[part 3 of 3: package /ComponentTypes]
AUTOSAR XML (schema 00050)
package /ComponentTypes  (continued)
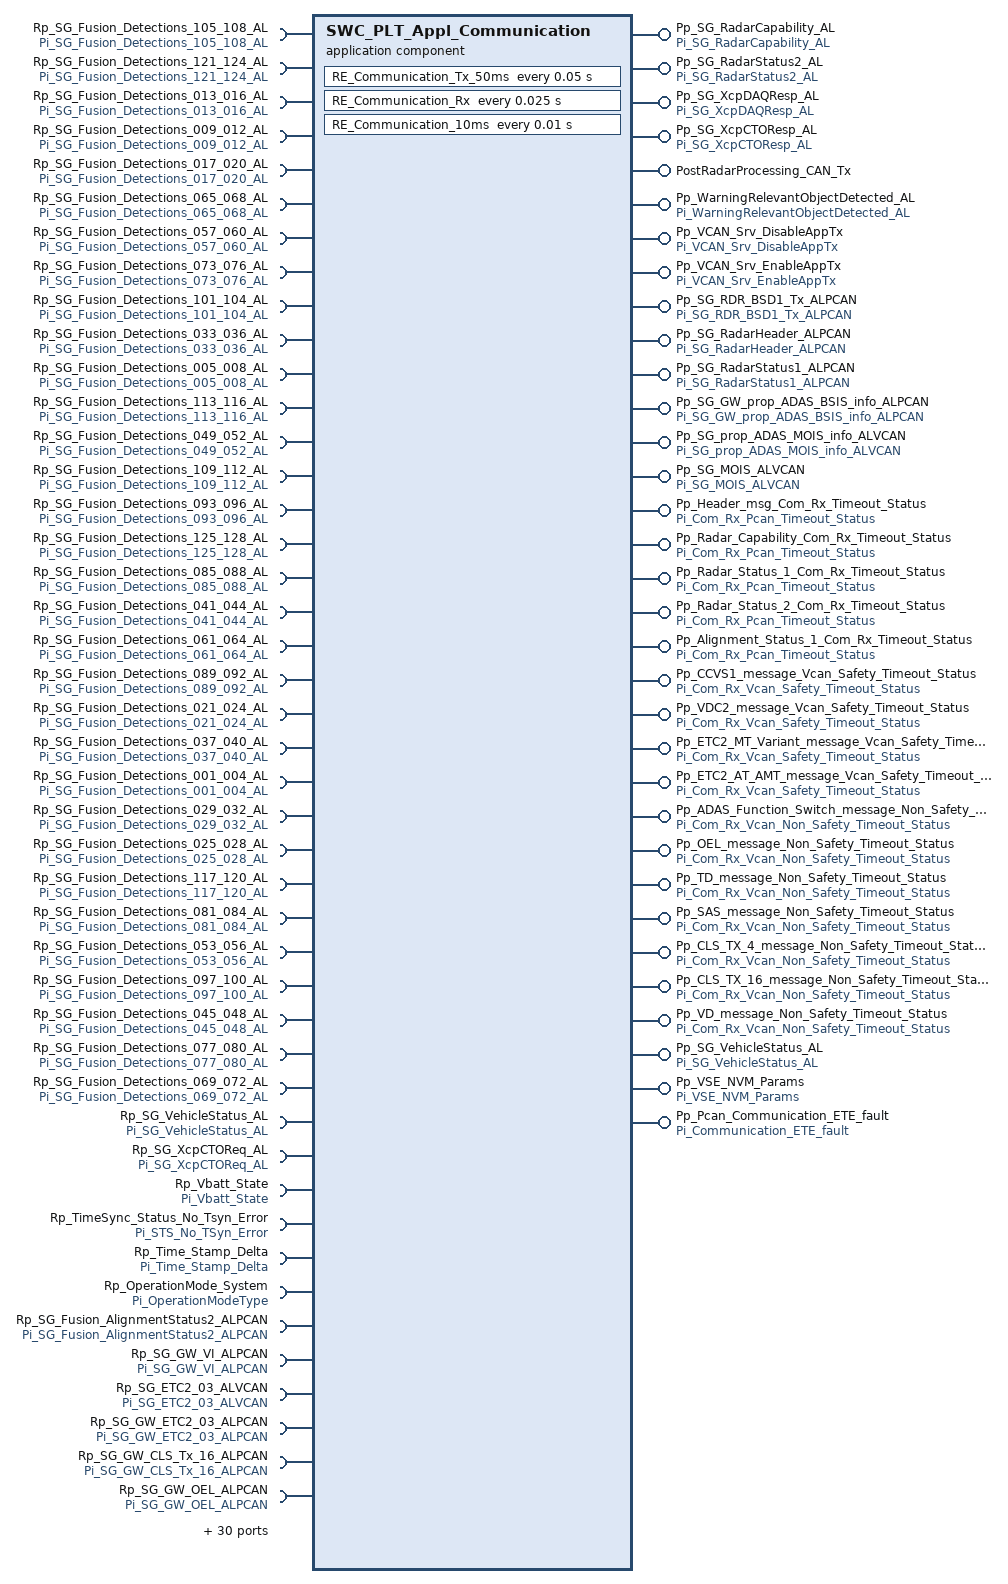
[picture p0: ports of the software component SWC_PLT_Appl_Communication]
  application sw component type SWC_PLT_Appl_Communication  (continued)
    182 x provide port:  (continued)
      Pp_SG_Detections_157_160_AL: nonqueued-sender-com-spec{data-element=Vdp_SG_Detections_157_160_AL, init-value=fields=[DET_AZIMUTH_157:0, DET_AZIMUTH_158:0, DET_AZIMUTH_159:0, DET_AZIMUTH_160:0, DET_AZIMUTH_ERR_157:0, DET_AZIMUTH_ERR_158:0, DET_AZIMUTH_ERR_159:0, DET_AZIMUTH_ERR_160:0, DET_BELOW_RAIN_THOLD_157:0, DET_BELOW_RAIN_THOLD_158:0, DET_BELOW_RAIN_THOLD_159:0, DET_BELOW_RAIN_THOLD_160:0, DET_BI_STATIC_FLAG_157:0, DET_BI_STATIC_FLAG_158:0, DET_BI_STATIC_FLAG_159:0, DET_BI_STATIC_FLAG_160:0, DET_CONFD_AZIMUTH_157:0, DET_CONFD_AZIMUTH_158:0, DET_CONFD_AZIMUTH_159:0, DET_CONFD_AZIMUTH_160:0, DET_CONFD_ELEVATION_157:0, DET_CONFD_ELEVATION_158:0, DET_CONFD_ELEVATION_159:0, DET_CONFD_ELEVATION_160:0, DET_ELEVATION_157:0, DET_ELEVATION_158:0, DET_ELEVATION_159:0, DET_ELEVATION_160:0, DET_ELEVATION_ERR_157:0, DET_ELEVATION_ERR_158:0, DET_ELEVATION_ERR_159:0, DET_ELEVATION_ERR_160:0, DET_EXISTENCE_PROB_157:0, DET_EXISTENCE_PROB_158:0, DET_EXISTENCE_PROB_159:0, DET_EXISTENCE_PROB_160:0, DET_HVC_FLAG_157:0, DET_HVC_FLAG_158:0, DET_HVC_FLAG_159:0, DET_HVC_FLAG_160:0, DET_IDM_157:0, DET_IDM_158:0, DET_IDM_159:0, DET_IDM_160:0, DET_MH_CRC16_157_160:0, DET_MH_CYCLE_COUNTER_157_160:0, DET_MH_SCAN_INDEX_4LSB_157_160:0, DET_MTD_157:0, DET_MTD_158:0, DET_MTD_159:0, DET_MTD_160:0, DET_PROB_1STAZHYPO_157:0, DET_PROB_1STAZHYPO_158:0, DET_PROB_1STAZHYPO_159:0, DET_PROB_1STAZHYPO_160:0, DET_RANGE_157:0, DET_RANGE_158:0, DET_RANGE_159:0, DET_RANGE_160:0, DET_RANGE_ERR_157:0, DET_RANGE_ERR_158:0, DET_RANGE_ERR_159:0, DET_RANGE_ERR_160:0, DET_RANGE_VELOCITY_157:16384, DET_RANGE_VELOCITY_158:16384, DET_RANGE_VELOCITY_159:16384, DET_RANGE_VELOCITY_160:16384, DET_RANGE_VELOCITY_ERR_157:0, DET_RANGE_VELOCITY_ERR_158:0, DET_RANGE_VELOCITY_ERR_159:0, DET_RANGE_VELOCITY_ERR_160:0, DET_RCS_157:128, DET_RCS_158:128, DET_RCS_159:128, DET_RCS_160:128, DET_SNR_157:0, DET_SNR_158:0, DET_SNR_159:0, DET_SNR_160:0, DET_SUPER_RES_TARGET_157:0, DET_SUPER_RES_TARGET_158:0, DET_SUPER_RES_TARGET_159:0, DET_SUPER_RES_TARGET_160:0]}, provided-interface=Pi_SG_Detections_157_160_AL
      Pp_SG_Detections_013_016_AL: nonqueued-sender-com-spec{data-element=Vdp_SG_Detections_013_016_AL, init-value=fields=[DET_AZIMUTH_013:0, DET_AZIMUTH_014:0, DET_AZIMUTH_015:0, DET_AZIMUTH_016:0, DET_AZIMUTH_ERR_013:0, DET_AZIMUTH_ERR_014:0, DET_AZIMUTH_ERR_015:0, DET_AZIMUTH_ERR_016:0, DET_BELOW_RAIN_THOLD_013:0, DET_BELOW_RAIN_THOLD_014:0, DET_BELOW_RAIN_THOLD_015:0, DET_BELOW_RAIN_THOLD_016:0, DET_BI_STATIC_FLAG_013:0, DET_BI_STATIC_FLAG_014:0, DET_BI_STATIC_FLAG_015:0, DET_BI_STATIC_FLAG_016:0, DET_CONFD_AZIMUTH_013:0, DET_CONFD_AZIMUTH_014:0, DET_CONFD_AZIMUTH_015:0, DET_CONFD_AZIMUTH_016:0, DET_CONFD_ELEVATION_013:0, DET_CONFD_ELEVATION_014:0, DET_CONFD_ELEVATION_015:0, DET_CONFD_ELEVATION_016:0, DET_ELEVATION_013:0, DET_ELEVATION_014:0, DET_ELEVATION_015:0, DET_ELEVATION_016:0, DET_ELEVATION_ERR_013:0, DET_ELEVATION_ERR_014:0, DET_ELEVATION_ERR_015:0, DET_ELEVATION_ERR_016:0, DET_EXISTENCE_PROB_013:0, DET_EXISTENCE_PROB_014:0, DET_EXISTENCE_PROB_015:0, DET_EXISTENCE_PROB_016:0, DET_HVC_FLAG_013:0, DET_HVC_FLAG_014:0, DET_HVC_FLAG_015:0, DET_HVC_FLAG_016:0, DET_IDM_013:0, DET_IDM_014:0, DET_IDM_015:0, DET_IDM_016:0, DET_MH_CRC16_013_016:0, DET_MH_CYCLE_COUNTER_013_016:0, DET_MH_SCAN_INDEX_4LSB_013_016:0, DET_MTD_013:0, DET_MTD_014:0, DET_MTD_015:0, DET_MTD_016:0, DET_PROB_1STAZHYPO_013:0, DET_PROB_1STAZHYPO_014:0, DET_PROB_1STAZHYPO_015:0, DET_PROB_1STAZHYPO_016:0, DET_RANGE_013:0, DET_RANGE_014:0, DET_RANGE_015:0, DET_RANGE_016:0, DET_RANGE_ERR_013:0, DET_RANGE_ERR_014:0, DET_RANGE_ERR_015:0, DET_RANGE_ERR_016:0, DET_RANGE_VELOCITY_013:16384, DET_RANGE_VELOCITY_014:16384, DET_RANGE_VELOCITY_015:16384, DET_RANGE_VELOCITY_016:16384, DET_RANGE_VELOCITY_ERR_013:0, DET_RANGE_VELOCITY_ERR_014:0, DET_RANGE_VELOCITY_ERR_015:0, DET_RANGE_VELOCITY_ERR_016:0, DET_RCS_013:128, DET_RCS_014:128, DET_RCS_015:128, DET_RCS_016:128, DET_SNR_013:0, DET_SNR_014:0, DET_SNR_015:0, DET_SNR_016:0, DET_SUPER_RES_TARGET_013:0, DET_SUPER_RES_TARGET_014:0, DET_SUPER_RES_TARGET_015:0, DET_SUPER_RES_TARGET_016:0]}, provided-interface=Pi_SG_Detections_013_016_AL
    32 x require port:
      Rp_SG_Fusion_Detections_105_108_AL: nonqueued-receiver-com-spec{data-element=Vdp_SG_Fusion_Detections_105_108_AL, init-value=fields=[DET_AZIMUTH_105_Rx:0, DET_AZIMUTH_106_Rx:0, DET_AZIMUTH_107_Rx:0, DET_AZIMUTH_108_Rx:0, DET_AZIMUTH_ERR_105_Rx:0, DET_AZIMUTH_ERR_106_Rx:0, DET_AZIMUTH_ERR_107_Rx:0, DET_AZIMUTH_ERR_108_Rx:0, DET_BELOW_RAIN_THOLD_105_Rx:0, DET_BELOW_RAIN_THOLD_106_Rx:0, DET_BELOW_RAIN_THOLD_107_Rx:0, DET_BELOW_RAIN_THOLD_108_Rx:0, DET_BI_STATIC_FLAG_105_Rx:0, DET_BI_STATIC_FLAG_106_Rx:0, DET_BI_STATIC_FLAG_107_Rx:0, DET_BI_STATIC_FLAG_108_Rx:0, DET_CONFD_AZIMUTH_105_Rx:0, DET_CONFD_AZIMUTH_106_Rx:0, DET_CONFD_AZIMUTH_107_Rx:0, DET_CONFD_AZIMUTH_108_Rx:0, DET_CONFD_ELEVATION_105_Rx:0, DET_CONFD_ELEVATION_106_Rx:0, DET_CONFD_ELEVATION_107_Rx:0, DET_CONFD_ELEVATION_108_Rx:0, DET_ELEVATION_105_Rx:0, DET_ELEVATION_106_Rx:0, DET_ELEVATION_107_Rx:0, DET_ELEVATION_108_Rx:0, DET_ELEVATION_ERR_105_Rx:0, DET_ELEVATION_ERR_106_Rx:0, DET_ELEVATION_ERR_107_Rx:0, DET_ELEVATION_ERR_108_Rx:0, DET_EXISTENCE_PROB_105_Rx:0, DET_EXISTENCE_PROB_106_Rx:0, DET_EXISTENCE_PROB_107_Rx:0, DET_EXISTENCE_PROB_108_Rx:0, DET_HVC_FLAG_105_Rx:0, DET_HVC_FLAG_106_Rx:0, DET_HVC_FLAG_107_Rx:0, DET_HVC_FLAG_108_Rx:0, DET_IDM_105_Rx:0, DET_IDM_106_Rx:0, DET_IDM_107_Rx:0, DET_IDM_108_Rx:0, DET_MH_CRC16_105_108_Rx:0, DET_MH_CYCLE_COUNTER_105_108_Rx:0, DET_MH_SCAN_INDEX_4LSB_105_108_Rx:0, DET_MTD_105_Rx:0, DET_MTD_106_Rx:0, DET_MTD_107_Rx:0, DET_MTD_108_Rx:0, DET_PROB_1STAZHYPO_105_Rx:0, DET_PROB_1STAZHYPO_106_Rx:0, DET_PROB_1STAZHYPO_107_Rx:0, DET_PROB_1STAZHYPO_108_Rx:0, DET_RANGE_105_Rx:0, DET_RANGE_106_Rx:0, DET_RANGE_107_Rx:0, DET_RANGE_108_Rx:0, DET_RANGE_ERR_105_Rx:0, DET_RANGE_ERR_106_Rx:0, DET_RANGE_ERR_107_Rx:0, DET_RANGE_ERR_108_Rx:0, DET_RANGE_VELOCITY_105_Rx:0, DET_RANGE_VELOCITY_106_Rx:0, DET_RANGE_VELOCITY_107_Rx:0, DET_RANGE_VELOCITY_108_Rx:0, DET_RANGE_VELOCITY_ERR_105_Rx:0, DET_RANGE_VELOCITY_ERR_106_Rx:0, DET_RANGE_VELOCITY_ERR_107_Rx:0, DET_RANGE_VELOCITY_ERR_108_Rx:0, DET_RCS_105_Rx:0, DET_RCS_106_Rx:0, DET_RCS_107_Rx:0, DET_RCS_108_Rx:0, DET_SNR_105_Rx:0, DET_SNR_106_Rx:0, DET_SNR_107_Rx:0, DET_SNR_108_Rx:0, DET_SUPER_RES_TARGET_105_Rx:0, DET_SUPER_RES_TARGET_106_Rx:0, DET_SUPER_RES_TARGET_107_Rx:0, DET_SUPER_RES_TARGET_108_Rx:0]}, required-interface=Pi_SG_Fusion_Detections_105_108_AL
      Rp_SG_Fusion_Detections_121_124_AL: nonqueued-receiver-com-spec{data-element=Vdp_SG_Fusion_Detections_121_124_AL, init-value=fields=[DET_AZIMUTH_121_Rx:0, DET_AZIMUTH_122_Rx:0, DET_AZIMUTH_123_Rx:0, DET_AZIMUTH_124_Rx:0, DET_AZIMUTH_ERR_121_Rx:0, DET_AZIMUTH_ERR_122_Rx:0, DET_AZIMUTH_ERR_123_Rx:0, DET_AZIMUTH_ERR_124_Rx:0, DET_BELOW_RAIN_THOLD_121_Rx:0, DET_BELOW_RAIN_THOLD_122_Rx:0, DET_BELOW_RAIN_THOLD_123_Rx:0, DET_BELOW_RAIN_THOLD_124_Rx:0, DET_BI_STATIC_FLAG_121_Rx:0, DET_BI_STATIC_FLAG_122_Rx:0, DET_BI_STATIC_FLAG_123_Rx:0, DET_BI_STATIC_FLAG_124_Rx:0, DET_CONFD_AZIMUTH_121_Rx:0, DET_CONFD_AZIMUTH_122_Rx:0, DET_CONFD_AZIMUTH_123_Rx:0, DET_CONFD_AZIMUTH_124_Rx:0, DET_CONFD_ELEVATION_121_Rx:0, DET_CONFD_ELEVATION_122_Rx:0, DET_CONFD_ELEVATION_123_Rx:0, DET_CONFD_ELEVATION_124_Rx:0, DET_ELEVATION_121_Rx:0, DET_ELEVATION_122_Rx:0, DET_ELEVATION_123_Rx:0, DET_ELEVATION_124_Rx:0, DET_ELEVATION_ERR_121_Rx:0, DET_ELEVATION_ERR_122_Rx:0, DET_ELEVATION_ERR_123_Rx:0, DET_ELEVATION_ERR_124_Rx:0, DET_EXISTENCE_PROB_121_Rx:0, DET_EXISTENCE_PROB_122_Rx:0, DET_EXISTENCE_PROB_123_Rx:0, DET_EXISTENCE_PROB_124_Rx:0, DET_HVC_FLAG_121_Rx:0, DET_HVC_FLAG_122_Rx:0, DET_HVC_FLAG_123_Rx:0, DET_HVC_FLAG_124_Rx:0, DET_IDM_121_Rx:0, DET_IDM_122_Rx:0, DET_IDM_123_Rx:0, DET_IDM_124_Rx:0, DET_MH_CRC16_121_124_Rx:0, DET_MH_CYCLE_COUNTER_121_124_Rx:0, DET_MH_SCAN_INDEX_4LSB_121_124_Rx:0, DET_MTD_121_Rx:0, DET_MTD_122_Rx:0, DET_MTD_123_Rx:0, DET_MTD_124_Rx:0, DET_PROB_1STAZHYPO_121_Rx:0, DET_PROB_1STAZHYPO_122_Rx:0, DET_PROB_1STAZHYPO_123_Rx:0, DET_PROB_1STAZHYPO_124_Rx:0, DET_RANGE_121_Rx:0, DET_RANGE_122_Rx:0, DET_RANGE_123_Rx:0, DET_RANGE_124_Rx:0, DET_RANGE_ERR_121_Rx:0, DET_RANGE_ERR_122_Rx:0, DET_RANGE_ERR_123_Rx:0, DET_RANGE_ERR_124_Rx:0, DET_RANGE_VELOCITY_121_Rx:0, DET_RANGE_VELOCITY_122_Rx:0, DET_RANGE_VELOCITY_123_Rx:0, DET_RANGE_VELOCITY_124_Rx:0, DET_RANGE_VELOCITY_ERR_121_Rx:0, DET_RANGE_VELOCITY_ERR_122_Rx:0, DET_RANGE_VELOCITY_ERR_123_Rx:0, DET_RANGE_VELOCITY_ERR_124_Rx:0, DET_RCS_121_Rx:0, DET_RCS_122_Rx:0, DET_RCS_123_Rx:0, DET_RCS_124_Rx:0, DET_SNR_121_Rx:0, DET_SNR_122_Rx:0, DET_SNR_123_Rx:0, DET_SNR_124_Rx:0, DET_SUPER_RES_TARGET_121_Rx:0, DET_SUPER_RES_TARGET_122_Rx:0, DET_SUPER_RES_TARGET_123_Rx:0, DET_SUPER_RES_TARGET_124_Rx:0]}, required-interface=Pi_SG_Fusion_Detections_121_124_AL
      Rp_SG_Fusion_Detections_013_016_AL: nonqueued-receiver-com-spec{data-element=Vdp_SG_Fusion_Detections_013_016_AL, init-value=fields=[DET_AZIMUTH_013_Rx:0, DET_AZIMUTH_014_Rx:0, DET_AZIMUTH_015_Rx:0, DET_AZIMUTH_016_Rx:0, DET_AZIMUTH_ERR_013_Rx:0, DET_AZIMUTH_ERR_014_Rx:0, DET_AZIMUTH_ERR_015_Rx:0, DET_AZIMUTH_ERR_016_Rx:0, DET_BELOW_RAIN_THOLD_013_Rx:0, DET_BELOW_RAIN_THOLD_014_Rx:0, DET_BELOW_RAIN_THOLD_015_Rx:0, DET_BELOW_RAIN_THOLD_016_Rx:0, DET_BI_STATIC_FLAG_013_Rx:0, DET_BI_STATIC_FLAG_014_Rx:0, DET_BI_STATIC_FLAG_015_Rx:0, DET_BI_STATIC_FLAG_016_Rx:0, DET_CONFD_AZIMUTH_013_Rx:0, DET_CONFD_AZIMUTH_014_Rx:0, DET_CONFD_AZIMUTH_015_Rx:0, DET_CONFD_AZIMUTH_016_Rx:0, DET_CONFD_ELEVATION_013_Rx:0, DET_CONFD_ELEVATION_014_Rx:0, DET_CONFD_ELEVATION_015_Rx:0, DET_CONFD_ELEVATION_016_Rx:0, DET_ELEVATION_013_Rx:0, DET_ELEVATION_014_Rx:0, DET_ELEVATION_015_Rx:0, DET_ELEVATION_016_Rx:0, DET_ELEVATION_ERR_013_Rx:0, DET_ELEVATION_ERR_014_Rx:0, DET_ELEVATION_ERR_015_Rx:0, DET_ELEVATION_ERR_016_Rx:0, DET_EXISTENCE_PROB_013_Rx:0, DET_EXISTENCE_PROB_014_Rx:0, DET_EXISTENCE_PROB_015_Rx:0, DET_EXISTENCE_PROB_016_Rx:0, DET_HVC_FLAG_013_Rx:0, DET_HVC_FLAG_014_Rx:0, DET_HVC_FLAG_015_Rx:0, DET_HVC_FLAG_016_Rx:0, DET_IDM_013_Rx:0, DET_IDM_014_Rx:0, DET_IDM_015_Rx:0, DET_IDM_016_Rx:0, DET_MH_CRC16_013_016_Rx:0, DET_MH_CYCLE_COUNTER_013_016_Rx:0, DET_MH_SCAN_INDEX_4LSB_013_016_Rx:0, DET_MTD_013_Rx:0, DET_MTD_014_Rx:0, DET_MTD_015_Rx:0, DET_MTD_016_Rx:0, DET_PROB_1STAZHYPO_013_Rx:0, DET_PROB_1STAZHYPO_014_Rx:0, DET_PROB_1STAZHYPO_015_Rx:0, DET_PROB_1STAZHYPO_016_Rx:0, DET_RANGE_013_Rx:0, DET_RANGE_014_Rx:0, DET_RANGE_015_Rx:0, DET_RANGE_016_Rx:0, DET_RANGE_ERR_013_Rx:0, DET_RANGE_ERR_014_Rx:0, DET_RANGE_ERR_015_Rx:0, DET_RANGE_ERR_016_Rx:0, DET_RANGE_VELOCITY_013_Rx:0, DET_RANGE_VELOCITY_014_Rx:0, DET_RANGE_VELOCITY_015_Rx:0, DET_RANGE_VELOCITY_016_Rx:0, DET_RANGE_VELOCITY_ERR_013_Rx:0, DET_RANGE_VELOCITY_ERR_014_Rx:0, DET_RANGE_VELOCITY_ERR_015_Rx:0, DET_RANGE_VELOCITY_ERR_016_Rx:0, DET_RCS_013_Rx:0, DET_RCS_014_Rx:0, DET_RCS_015_Rx:0, DET_RCS_016_Rx:0, DET_SNR_013_Rx:0, DET_SNR_014_Rx:0, DET_SNR_015_Rx:0, DET_SNR_016_Rx:0, DET_SUPER_RES_TARGET_013_Rx:0, DET_SUPER_RES_TARGET_014_Rx:0, DET_SUPER_RES_TARGET_015_Rx:0, DET_SUPER_RES_TARGET_016_Rx:0]}, required-interface=Pi_SG_Fusion_Detections_013_016_AL
      Rp_SG_Fusion_Detections_009_012_AL: nonqueued-receiver-com-spec{data-element=Vdp_SG_Fusion_Detections_009_012_AL, init-value=fields=[DET_AZIMUTH_009_Rx:0, DET_AZIMUTH_010_Rx:0, DET_AZIMUTH_011_Rx:0, DET_AZIMUTH_012_Rx:0, DET_AZIMUTH_ERR_009_Rx:0, DET_AZIMUTH_ERR_010_Rx:0, DET_AZIMUTH_ERR_011_Rx:0, DET_AZIMUTH_ERR_012_Rx:0, DET_BELOW_RAIN_THOLD_009_Rx:0, DET_BELOW_RAIN_THOLD_010_Rx:0, DET_BELOW_RAIN_THOLD_011_Rx:0, DET_BELOW_RAIN_THOLD_012_Rx:0, DET_BI_STATIC_FLAG_009_Rx:0, DET_BI_STATIC_FLAG_010_Rx:0, DET_BI_STATIC_FLAG_011_Rx:0, DET_BI_STATIC_FLAG_012_Rx:0, DET_CONFD_AZIMUTH_009_Rx:0, DET_CONFD_AZIMUTH_010_Rx:0, DET_CONFD_AZIMUTH_011_Rx:0, DET_CONFD_AZIMUTH_012_Rx:0, DET_CONFD_ELEVATION_009_Rx:0, DET_CONFD_ELEVATION_010_Rx:0, DET_CONFD_ELEVATION_011_Rx:0, DET_CONFD_ELEVATION_012_Rx:0, DET_ELEVATION_009_Rx:0, DET_ELEVATION_010_Rx:0, DET_ELEVATION_011_Rx:0, DET_ELEVATION_012_Rx:0, DET_ELEVATION_ERR_009_Rx:0, DET_ELEVATION_ERR_010_Rx:0, DET_ELEVATION_ERR_011_Rx:0, DET_ELEVATION_ERR_012_Rx:0, DET_EXISTENCE_PROB_009_Rx:0, DET_EXISTENCE_PROB_010_Rx:0, DET_EXISTENCE_PROB_011_Rx:0, DET_EXISTENCE_PROB_012_Rx:0, DET_HVC_FLAG_009_Rx:0, DET_HVC_FLAG_010_Rx:0, DET_HVC_FLAG_011_Rx:0, DET_HVC_FLAG_012_Rx:0, DET_IDM_009_Rx:0, DET_IDM_010_Rx:0, DET_IDM_011_Rx:0, DET_IDM_012_Rx:0, DET_MH_CRC16_009_012_Rx:0, DET_MH_CYCLE_COUNTER_009_012_Rx:0, DET_MH_SCAN_INDEX_4LSB_009_012_Rx:0, DET_MTD_009_Rx:0, DET_MTD_010_Rx:0, DET_MTD_011_Rx:0, DET_MTD_012_Rx:0, DET_PROB_1STAZHYPO_009_Rx:0, DET_PROB_1STAZHYPO_010_Rx:0, DET_PROB_1STAZHYPO_011_Rx:0, DET_PROB_1STAZHYPO_012_Rx:0, DET_RANGE_009_Rx:0, DET_RANGE_010_Rx:0, DET_RANGE_011_Rx:0, DET_RANGE_012_Rx:0, DET_RANGE_ERR_009_Rx:0, DET_RANGE_ERR_010_Rx:0, DET_RANGE_ERR_011_Rx:0, DET_RANGE_ERR_012_Rx:0, DET_RANGE_VELOCITY_009_Rx:0, DET_RANGE_VELOCITY_010_Rx:0, DET_RANGE_VELOCITY_011_Rx:0, DET_RANGE_VELOCITY_012_Rx:0, DET_RANGE_VELOCITY_ERR_009_Rx:0, DET_RANGE_VELOCITY_ERR_010_Rx:0, DET_RANGE_VELOCITY_ERR_011_Rx:0, DET_RANGE_VELOCITY_ERR_012_Rx:0, DET_RCS_009_Rx:0, DET_RCS_010_Rx:0, DET_RCS_011_Rx:0, DET_RCS_012_Rx:0, DET_SNR_009_Rx:0, DET_SNR_010_Rx:0, DET_SNR_011_Rx:0, DET_SNR_012_Rx:0, DET_SUPER_RES_TARGET_009_Rx:0, DET_SUPER_RES_TARGET_010_Rx:0, DET_SUPER_RES_TARGET_011_Rx:0, DET_SUPER_RES_TARGET_012_Rx:0]}, required-interface=Pi_SG_Fusion_Detections_009_012_AL
      Rp_SG_Fusion_Detections_017_020_AL: nonqueued-receiver-com-spec{data-element=Vdp_SG_Fusion_Detections_017_020_AL, init-value=fields=[DET_AZIMUTH_017_Rx:0, DET_AZIMUTH_018_Rx:0, DET_AZIMUTH_019_Rx:0, DET_AZIMUTH_020_Rx:0, DET_AZIMUTH_ERR_017_Rx:0, DET_AZIMUTH_ERR_018_Rx:0, DET_AZIMUTH_ERR_019_Rx:0, DET_AZIMUTH_ERR_020_Rx:0, DET_BELOW_RAIN_THOLD_017_Rx:0, DET_BELOW_RAIN_THOLD_018_Rx:0, DET_BELOW_RAIN_THOLD_019_Rx:0, DET_BELOW_RAIN_THOLD_020_Rx:0, DET_BI_STATIC_FLAG_017_Rx:0, DET_BI_STATIC_FLAG_018_Rx:0, DET_BI_STATIC_FLAG_019_Rx:0, DET_BI_STATIC_FLAG_020_Rx:0, DET_CONFD_AZIMUTH_017_Rx:0, DET_CONFD_AZIMUTH_018_Rx:0, DET_CONFD_AZIMUTH_019_Rx:0, DET_CONFD_AZIMUTH_020_Rx:0, DET_CONFD_ELEVATION_017_Rx:0, DET_CONFD_ELEVATION_018_Rx:0, DET_CONFD_ELEVATION_019_Rx:0, DET_CONFD_ELEVATION_020_Rx:0, DET_ELEVATION_017_Rx:0, DET_ELEVATION_018_Rx:0, DET_ELEVATION_019_Rx:0, DET_ELEVATION_020_Rx:0, DET_ELEVATION_ERR_017_Rx:0, DET_ELEVATION_ERR_018_Rx:0, DET_ELEVATION_ERR_019_Rx:0, DET_ELEVATION_ERR_020_Rx:0, DET_EXISTENCE_PROB_017_Rx:0, DET_EXISTENCE_PROB_018_Rx:0, DET_EXISTENCE_PROB_019_Rx:0, DET_EXISTENCE_PROB_020_Rx:0, DET_HVC_FLAG_017_Rx:0, DET_HVC_FLAG_018_Rx:0, DET_HVC_FLAG_019_Rx:0, DET_HVC_FLAG_020_Rx:0, DET_IDM_017_Rx:0, DET_IDM_018_Rx:0, DET_IDM_019_Rx:0, DET_IDM_020_Rx:0, DET_MH_CRC16_017_020_Rx:0, DET_MH_CYCLE_COUNTER_017_020_Rx:0, DET_MH_SCAN_INDEX_4LSB_017_020_Rx:0, DET_MTD_017_Rx:0, DET_MTD_018_Rx:0, DET_MTD_019_Rx:0, DET_MTD_020_Rx:0, DET_PROB_1STAZHYPO_017_Rx:0, DET_PROB_1STAZHYPO_018_Rx:0, DET_PROB_1STAZHYPO_019_Rx:0, DET_PROB_1STAZHYPO_020_Rx:0, DET_RANGE_017_Rx:0, DET_RANGE_018_Rx:0, DET_RANGE_019_Rx:0, DET_RANGE_020_Rx:0, DET_RANGE_ERR_017_Rx:0, DET_RANGE_ERR_018_Rx:0, DET_RANGE_ERR_019_Rx:0, DET_RANGE_ERR_020_Rx:0, DET_RANGE_VELOCITY_017_Rx:0, DET_RANGE_VELOCITY_018_Rx:0, DET_RANGE_VELOCITY_019_Rx:0, DET_RANGE_VELOCITY_020_Rx:0, DET_RANGE_VELOCITY_ERR_017_Rx:0, DET_RANGE_VELOCITY_ERR_018_Rx:0, DET_RANGE_VELOCITY_ERR_019_Rx:0, DET_RANGE_VELOCITY_ERR_020_Rx:0, DET_RCS_017_Rx:0, DET_RCS_018_Rx:0, DET_RCS_019_Rx:0, DET_RCS_020_Rx:0, DET_SNR_017_Rx:0, DET_SNR_018_Rx:0, DET_SNR_019_Rx:0, DET_SNR_020_Rx:0, DET_SUPER_RES_TARGET_017_Rx:0, DET_SUPER_RES_TARGET_018_Rx:0, DET_SUPER_RES_TARGET_019_Rx:0, DET_SUPER_RES_TARGET_020_Rx:0]}, required-interface=Pi_SG_Fusion_Detections_017_020_AL
      Rp_SG_Fusion_Detections_065_068_AL: nonqueued-receiver-com-spec{data-element=Vdp_SG_Fusion_Detections_065_068_AL, init-value=fields=[DET_AZIMUTH_065_Rx:0, DET_AZIMUTH_066_Rx:0, DET_AZIMUTH_067_Rx:0, DET_AZIMUTH_068_Rx:0, DET_AZIMUTH_ERR_065_Rx:0, DET_AZIMUTH_ERR_066_Rx:0, DET_AZIMUTH_ERR_067_Rx:0, DET_AZIMUTH_ERR_068_Rx:0, DET_BELOW_RAIN_THOLD_065_Rx:0, DET_BELOW_RAIN_THOLD_066_Rx:0, DET_BELOW_RAIN_THOLD_067_Rx:0, DET_BELOW_RAIN_THOLD_068_Rx:0, DET_BI_STATIC_FLAG_065_Rx:0, DET_BI_STATIC_FLAG_066_Rx:0, DET_BI_STATIC_FLAG_067_Rx:0, DET_BI_STATIC_FLAG_068_Rx:0, DET_CONFD_AZIMUTH_065_Rx:0, DET_CONFD_AZIMUTH_066_Rx:0, DET_CONFD_AZIMUTH_067_Rx:0, DET_CONFD_AZIMUTH_068_Rx:0, DET_CONFD_ELEVATION_065_Rx:0, DET_CONFD_ELEVATION_066_Rx:0, DET_CONFD_ELEVATION_067_Rx:0, DET_CONFD_ELEVATION_068_Rx:0, DET_ELEVATION_065_Rx:0, DET_ELEVATION_066_Rx:0, DET_ELEVATION_067_Rx:0, DET_ELEVATION_068_Rx:0, DET_ELEVATION_ERR_065_Rx:0, DET_ELEVATION_ERR_066_Rx:0, DET_ELEVATION_ERR_067_Rx:0, DET_ELEVATION_ERR_068_Rx:0, DET_EXISTENCE_PROB_065_Rx:0, DET_EXISTENCE_PROB_066_Rx:0, DET_EXISTENCE_PROB_067_Rx:0, DET_EXISTENCE_PROB_068_Rx:0, DET_HVC_FLAG_065_Rx:0, DET_HVC_FLAG_066_Rx:0, DET_HVC_FLAG_067_Rx:0, DET_HVC_FLAG_068_Rx:0, DET_IDM_065_Rx:0, DET_IDM_066_Rx:0, DET_IDM_067_Rx:0, DET_IDM_068_Rx:0, DET_MH_CRC16_065_068_Rx:0, DET_MH_CYCLE_COUNTER_065_068_Rx:0, DET_MH_SCAN_INDEX_4LSB_065_068_Rx:0, DET_MTD_065_Rx:0, DET_MTD_066_Rx:0, DET_MTD_067_Rx:0, DET_MTD_068_Rx:0, DET_PROB_1STAZHYPO_065_Rx:0, DET_PROB_1STAZHYPO_066_Rx:0, DET_PROB_1STAZHYPO_067_Rx:0, DET_PROB_1STAZHYPO_068_Rx:0, DET_RANGE_065_Rx:0, DET_RANGE_066_Rx:0, DET_RANGE_067_Rx:0, DET_RANGE_068_Rx:0, DET_RANGE_ERR_065_Rx:0, DET_RANGE_ERR_066_Rx:0, DET_RANGE_ERR_067_Rx:0, DET_RANGE_ERR_068_Rx:0, DET_RANGE_VELOCITY_065_Rx:0, DET_RANGE_VELOCITY_066_Rx:0, DET_RANGE_VELOCITY_067_Rx:0, DET_RANGE_VELOCITY_068_Rx:0, DET_RANGE_VELOCITY_ERR_065_Rx:0, DET_RANGE_VELOCITY_ERR_066_Rx:0, DET_RANGE_VELOCITY_ERR_067_Rx:0, DET_RANGE_VELOCITY_ERR_068_Rx:0, DET_RCS_065_Rx:0, DET_RCS_066_Rx:0, DET_RCS_067_Rx:0, DET_RCS_068_Rx:0, DET_SNR_065_Rx:0, DET_SNR_066_Rx:0, DET_SNR_067_Rx:0, DET_SNR_068_Rx:0, DET_SUPER_RES_TARGET_065_Rx:0, DET_SUPER_RES_TARGET_066_Rx:0, DET_SUPER_RES_TARGET_067_Rx:0, DET_SUPER_RES_TARGET_068_Rx:0]}, required-interface=Pi_SG_Fusion_Detections_065_068_AL
      Rp_SG_Fusion_Detections_057_060_AL: nonqueued-receiver-com-spec{data-element=Vdp_SG_Fusion_Detections_057_060_AL, init-value=fields=[DET_AZIMUTH_057_Rx:0, DET_AZIMUTH_058_Rx:0, DET_AZIMUTH_059_Rx:0, DET_AZIMUTH_060_Rx:0, DET_AZIMUTH_ERR_057_Rx:0, DET_AZIMUTH_ERR_058_Rx:0, DET_AZIMUTH_ERR_059_Rx:0, DET_AZIMUTH_ERR_060_Rx:0, DET_BELOW_RAIN_THOLD_057_Rx:0, DET_BELOW_RAIN_THOLD_058_Rx:0, DET_BELOW_RAIN_THOLD_059_Rx:0, DET_BELOW_RAIN_THOLD_060_Rx:0, DET_BI_STATIC_FLAG_057_Rx:0, DET_BI_STATIC_FLAG_058_Rx:0, DET_BI_STATIC_FLAG_059_Rx:0, DET_BI_STATIC_FLAG_060_Rx:0, DET_CONFD_AZIMUTH_057_Rx:0, DET_CONFD_AZIMUTH_058_Rx:0, DET_CONFD_AZIMUTH_059_Rx:0, DET_CONFD_AZIMUTH_060_Rx:0, DET_CONFD_ELEVATION_057_Rx:0, DET_CONFD_ELEVATION_058_Rx:0, DET_CONFD_ELEVATION_059_Rx:0, DET_CONFD_ELEVATION_060_Rx:0, DET_ELEVATION_057_Rx:0, DET_ELEVATION_058_Rx:0, DET_ELEVATION_059_Rx:0, DET_ELEVATION_060_Rx:0, DET_ELEVATION_ERR_057_Rx:0, DET_ELEVATION_ERR_058_Rx:0, DET_ELEVATION_ERR_059_Rx:0, DET_ELEVATION_ERR_060_Rx:0, DET_EXISTENCE_PROB_057_Rx:0, DET_EXISTENCE_PROB_058_Rx:0, DET_EXISTENCE_PROB_059_Rx:0, DET_EXISTENCE_PROB_060_Rx:0, DET_HVC_FLAG_057_Rx:0, DET_HVC_FLAG_058_Rx:0, DET_HVC_FLAG_059_Rx:0, DET_HVC_FLAG_060_Rx:0, DET_IDM_057_Rx:0, DET_IDM_058_Rx:0, DET_IDM_059_Rx:0, DET_IDM_060_Rx:0, DET_MH_CRC16_057_060_Rx:0, DET_MH_CYCLE_COUNTER_057_060_Rx:0, DET_MH_SCAN_INDEX_4LSB_057_060_Rx:0, DET_MTD_057_Rx:0, DET_MTD_058_Rx:0, DET_MTD_059_Rx:0, DET_MTD_060_Rx:0, DET_PROB_1STAZHYPO_057_Rx:0, DET_PROB_1STAZHYPO_058_Rx:0, DET_PROB_1STAZHYPO_059_Rx:0, DET_PROB_1STAZHYPO_060_Rx:0, DET_RANGE_057_Rx:0, DET_RANGE_058_Rx:0, DET_RANGE_059_Rx:0, DET_RANGE_060_Rx:0, DET_RANGE_ERR_057_Rx:0, DET_RANGE_ERR_058_Rx:0, DET_RANGE_ERR_059_Rx:0, DET_RANGE_ERR_060_Rx:0, DET_RANGE_VELOCITY_057_Rx:0, DET_RANGE_VELOCITY_058_Rx:0, DET_RANGE_VELOCITY_059_Rx:0, DET_RANGE_VELOCITY_060_Rx:0, DET_RANGE_VELOCITY_ERR_057_Rx:0, DET_RANGE_VELOCITY_ERR_058_Rx:0, DET_RANGE_VELOCITY_ERR_059_Rx:0, DET_RANGE_VELOCITY_ERR_060_Rx:0, DET_RCS_057_Rx:0, DET_RCS_058_Rx:0, DET_RCS_059_Rx:0, DET_RCS_060_Rx:0, DET_SNR_057_Rx:0, DET_SNR_058_Rx:0, DET_SNR_059_Rx:0, DET_SNR_060_Rx:0, DET_SUPER_RES_TARGET_057_Rx:0, DET_SUPER_RES_TARGET_058_Rx:0, DET_SUPER_RES_TARGET_059_Rx:0, DET_SUPER_RES_TARGET_060_Rx:0]}, required-interface=Pi_SG_Fusion_Detections_057_060_AL
      Rp_SG_Fusion_Detections_073_076_AL: nonqueued-receiver-com-spec{data-element=Vdp_SG_Fusion_Detections_073_076_AL, init-value=fields=[DET_AZIMUTH_073_Rx:0, DET_AZIMUTH_074_Rx:0, DET_AZIMUTH_075_Rx:0, DET_AZIMUTH_076_Rx:0, DET_AZIMUTH_ERR_073_Rx:0, DET_AZIMUTH_ERR_074_Rx:0, DET_AZIMUTH_ERR_075_Rx:0, DET_AZIMUTH_ERR_076_Rx:0, DET_BELOW_RAIN_THOLD_073_Rx:0, DET_BELOW_RAIN_THOLD_074_Rx:0, DET_BELOW_RAIN_THOLD_075_Rx:0, DET_BELOW_RAIN_THOLD_076_Rx:0, DET_BI_STATIC_FLAG_073_Rx:0, DET_BI_STATIC_FLAG_074_Rx:0, DET_BI_STATIC_FLAG_075_Rx:0, DET_BI_STATIC_FLAG_076_Rx:0, DET_CONFD_AZIMUTH_073_Rx:0, DET_CONFD_AZIMUTH_074_Rx:0, DET_CONFD_AZIMUTH_075_Rx:0, DET_CONFD_AZIMUTH_076_Rx:0, DET_CONFD_ELEVATION_073_Rx:0, DET_CONFD_ELEVATION_074_Rx:0, DET_CONFD_ELEVATION_075_Rx:0, DET_CONFD_ELEVATION_076_Rx:0, DET_ELEVATION_073_Rx:0, DET_ELEVATION_074_Rx:0, DET_ELEVATION_075_Rx:0, DET_ELEVATION_076_Rx:0, DET_ELEVATION_ERR_073_Rx:0, DET_ELEVATION_ERR_074_Rx:0, DET_ELEVATION_ERR_075_Rx:0, DET_ELEVATION_ERR_076_Rx:0, DET_EXISTENCE_PROB_073_Rx:0, DET_EXISTENCE_PROB_074_Rx:0, DET_EXISTENCE_PROB_075_Rx:0, DET_EXISTENCE_PROB_076_Rx:0, DET_HVC_FLAG_073_Rx:0, DET_HVC_FLAG_074_Rx:0, DET_HVC_FLAG_075_Rx:0, DET_HVC_FLAG_076_Rx:0, DET_IDM_073_Rx:0, DET_IDM_074_Rx:0, DET_IDM_075_Rx:0, DET_IDM_076_Rx:0, DET_MH_CRC16_073_076_Rx:0, DET_MH_CYCLE_COUNTER_073_076_Rx:0, DET_MH_SCAN_INDEX_4LSB_073_076_Rx:0, DET_MTD_073_Rx:0, DET_MTD_074_Rx:0, DET_MTD_075_Rx:0, DET_MTD_076_Rx:0, DET_PROB_1STAZHYPO_073_Rx:0, DET_PROB_1STAZHYPO_074_Rx:0, DET_PROB_1STAZHYPO_075_Rx:0, DET_PROB_1STAZHYPO_076_Rx:0, DET_RANGE_073_Rx:0, DET_RANGE_074_Rx:0, DET_RANGE_075_Rx:0, DET_RANGE_076_Rx:0, DET_RANGE_ERR_073_Rx:0, DET_RANGE_ERR_074_Rx:0, DET_RANGE_ERR_075_Rx:0, DET_RANGE_ERR_076_Rx:0, DET_RANGE_VELOCITY_073_Rx:0, DET_RANGE_VELOCITY_074_Rx:0, DET_RANGE_VELOCITY_075_Rx:0, DET_RANGE_VELOCITY_076_Rx:0, DET_RANGE_VELOCITY_ERR_073_Rx:0, DET_RANGE_VELOCITY_ERR_074_Rx:0, DET_RANGE_VELOCITY_ERR_075_Rx:0, DET_RANGE_VELOCITY_ERR_076_Rx:0, DET_RCS_073_Rx:0, DET_RCS_074_Rx:0, DET_RCS_075_Rx:0, DET_RCS_076_Rx:0, DET_SNR_073_Rx:0, DET_SNR_074_Rx:0, DET_SNR_075_Rx:0, DET_SNR_076_Rx:0, DET_SUPER_RES_TARGET_073_Rx:0, DET_SUPER_RES_TARGET_074_Rx:0, DET_SUPER_RES_TARGET_075_Rx:0, DET_SUPER_RES_TARGET_076_Rx:0]}, required-interface=Pi_SG_Fusion_Detections_073_076_AL
      Rp_SG_Fusion_Detections_101_104_AL: nonqueued-receiver-com-spec{data-element=Vdp_SG_Fusion_Detections_101_104_AL, init-value=fields=[DET_AZIMUTH_101_Rx:0, DET_AZIMUTH_102_Rx:0, DET_AZIMUTH_103_Rx:0, DET_AZIMUTH_104_Rx:0, DET_AZIMUTH_ERR_101_Rx:0, DET_AZIMUTH_ERR_102_Rx:0, DET_AZIMUTH_ERR_103_Rx:0, DET_AZIMUTH_ERR_104_Rx:0, DET_BELOW_RAIN_THOLD_101_Rx:0, DET_BELOW_RAIN_THOLD_102_Rx:0, DET_BELOW_RAIN_THOLD_103_Rx:0, DET_BELOW_RAIN_THOLD_104_Rx:0, DET_BI_STATIC_FLAG_101_Rx:0, DET_BI_STATIC_FLAG_102_Rx:0, DET_BI_STATIC_FLAG_103_Rx:0, DET_BI_STATIC_FLAG_104_Rx:0, DET_CONFD_AZIMUTH_101_Rx:0, DET_CONFD_AZIMUTH_102_Rx:0, DET_CONFD_AZIMUTH_103_Rx:0, DET_CONFD_AZIMUTH_104_Rx:0, DET_CONFD_ELEVATION_101_Rx:0, DET_CONFD_ELEVATION_102_Rx:0, DET_CONFD_ELEVATION_103_Rx:0, DET_CONFD_ELEVATION_104_Rx:0, DET_ELEVATION_101_Rx:0, DET_ELEVATION_102_Rx:0, DET_ELEVATION_103_Rx:0, DET_ELEVATION_104_Rx:0, DET_ELEVATION_ERR_101_Rx:0, DET_ELEVATION_ERR_102_Rx:0, DET_ELEVATION_ERR_103_Rx:0, DET_ELEVATION_ERR_104_Rx:0, DET_EXISTENCE_PROB_101_Rx:0, DET_EXISTENCE_PROB_102_Rx:0, DET_EXISTENCE_PROB_103_Rx:0, DET_EXISTENCE_PROB_104_Rx:0, DET_HVC_FLAG_101_Rx:0, DET_HVC_FLAG_102_Rx:0, DET_HVC_FLAG_103_Rx:0, DET_HVC_FLAG_104_Rx:0, DET_IDM_101_Rx:0, DET_IDM_102_Rx:0, DET_IDM_103_Rx:0, DET_IDM_104_Rx:0, DET_MH_CRC16_101_104_Rx:0, DET_MH_CYCLE_COUNTER_101_104_Rx:0, DET_MH_SCAN_INDEX_4LSB_101_104_Rx:0, DET_MTD_101_Rx:0, DET_MTD_102_Rx:0, DET_MTD_103_Rx:0, DET_MTD_104_Rx:0, DET_PROB_1STAZHYPO_101_Rx:0, DET_PROB_1STAZHYPO_102_Rx:0, DET_PROB_1STAZHYPO_103_Rx:0, DET_PROB_1STAZHYPO_104_Rx:0, DET_RANGE_101_Rx:0, DET_RANGE_102_Rx:0, DET_RANGE_103_Rx:0, DET_RANGE_104_Rx:0, DET_RANGE_ERR_101_Rx:0, DET_RANGE_ERR_102_Rx:0, DET_RANGE_ERR_103_Rx:0, DET_RANGE_ERR_104_Rx:0, DET_RANGE_VELOCITY_101_Rx:0, DET_RANGE_VELOCITY_102_Rx:0, DET_RANGE_VELOCITY_103_Rx:0, DET_RANGE_VELOCITY_104_Rx:0, DET_RANGE_VELOCITY_ERR_101_Rx:0, DET_RANGE_VELOCITY_ERR_102_Rx:0, DET_RANGE_VELOCITY_ERR_103_Rx:0, DET_RANGE_VELOCITY_ERR_104_Rx:0, DET_RCS_101_Rx:0, DET_RCS_102_Rx:0, DET_RCS_103_Rx:0, DET_RCS_104_Rx:0, DET_SNR_101_Rx:0, DET_SNR_102_Rx:0, DET_SNR_103_Rx:0, DET_SNR_104_Rx:0, DET_SUPER_RES_TARGET_101_Rx:0, DET_SUPER_RES_TARGET_102_Rx:0, DET_SUPER_RES_TARGET_103_Rx:0, DET_SUPER_RES_TARGET_104_Rx:0]}, required-interface=Pi_SG_Fusion_Detections_101_104_AL
      Rp_SG_Fusion_Detections_033_036_AL: nonqueued-receiver-com-spec{data-element=Vdp_SG_Fusion_Detections_033_036_AL, init-value=fields=[DET_AZIMUTH_033_Rx:0, DET_AZIMUTH_034_Rx:0, DET_AZIMUTH_035_Rx:0, DET_AZIMUTH_036_Rx:0, DET_AZIMUTH_ERR_033_Rx:0, DET_AZIMUTH_ERR_034_Rx:0, DET_AZIMUTH_ERR_035_Rx:0, DET_AZIMUTH_ERR_036_Rx:0, DET_BELOW_RAIN_THOLD_033_Rx:0, DET_BELOW_RAIN_THOLD_034_Rx:0, DET_BELOW_RAIN_THOLD_035_Rx:0, DET_BELOW_RAIN_THOLD_036_Rx:0, DET_BI_STATIC_FLAG_033_Rx:0, DET_BI_STATIC_FLAG_034_Rx:0, DET_BI_STATIC_FLAG_035_Rx:0, DET_BI_STATIC_FLAG_036_Rx:0, DET_CONFD_AZIMUTH_033_Rx:0, DET_CONFD_AZIMUTH_034_Rx:0, DET_CONFD_AZIMUTH_035_Rx:0, DET_CONFD_AZIMUTH_036_Rx:0, DET_CONFD_ELEVATION_033_Rx:0, DET_CONFD_ELEVATION_034_Rx:0, DET_CONFD_ELEVATION_035_Rx:0, DET_CONFD_ELEVATION_036_Rx:0, DET_ELEVATION_033_Rx:0, DET_ELEVATION_034_Rx:0, DET_ELEVATION_035_Rx:0, DET_ELEVATION_036_Rx:0, DET_ELEVATION_ERR_033_Rx:0, DET_ELEVATION_ERR_034_Rx:0, DET_ELEVATION_ERR_035_Rx:0, DET_ELEVATION_ERR_036_Rx:0, DET_EXISTENCE_PROB_033_Rx:0, DET_EXISTENCE_PROB_034_Rx:0, DET_EXISTENCE_PROB_035_Rx:0, DET_EXISTENCE_PROB_036_Rx:0, DET_HVC_FLAG_033_Rx:0, DET_HVC_FLAG_034_Rx:0, DET_HVC_FLAG_035_Rx:0, DET_HVC_FLAG_036_Rx:0, DET_IDM_033_Rx:0, DET_IDM_034_Rx:0, DET_IDM_035_Rx:0, DET_IDM_036_Rx:0, DET_MH_CRC16_033_036_Rx:0, DET_MH_CYCLE_COUNTER_033_036_Rx:0, DET_MH_SCAN_INDEX_4LSB_033_036_Rx:0, DET_MTD_033_Rx:0, DET_MTD_034_Rx:0, DET_MTD_035_Rx:0, DET_MTD_036_Rx:0, DET_PROB_1STAZHYPO_033_Rx:0, DET_PROB_1STAZHYPO_034_Rx:0, DET_PROB_1STAZHYPO_035_Rx:0, DET_PROB_1STAZHYPO_036_Rx:0, DET_RANGE_033_Rx:0, DET_RANGE_034_Rx:0, DET_RANGE_035_Rx:0, DET_RANGE_036_Rx:0, DET_RANGE_ERR_033_Rx:0, DET_RANGE_ERR_034_Rx:0, DET_RANGE_ERR_035_Rx:0, DET_RANGE_ERR_036_Rx:0, DET_RANGE_VELOCITY_033_Rx:0, DET_RANGE_VELOCITY_034_Rx:0, DET_RANGE_VELOCITY_035_Rx:0, DET_RANGE_VELOCITY_036_Rx:0, DET_RANGE_VELOCITY_ERR_033_Rx:0, DET_RANGE_VELOCITY_ERR_034_Rx:0, DET_RANGE_VELOCITY_ERR_035_Rx:0, DET_RANGE_VELOCITY_ERR_036_Rx:0, DET_RCS_033_Rx:0, DET_RCS_034_Rx:0, DET_RCS_035_Rx:0, DET_RCS_036_Rx:0, DET_SNR_033_Rx:0, DET_SNR_034_Rx:0, DET_SNR_035_Rx:0, DET_SNR_036_Rx:0, DET_SUPER_RES_TARGET_033_Rx:0, DET_SUPER_RES_TARGET_034_Rx:0, DET_SUPER_RES_TARGET_035_Rx:0, DET_SUPER_RES_TARGET_036_Rx:0]}, required-interface=Pi_SG_Fusion_Detections_033_036_AL
      Rp_SG_Fusion_Detections_005_008_AL: nonqueued-receiver-com-spec{data-element=Vdp_SG_Fusion_Detections_005_008_AL, init-value=fields=[DET_AZIMUTH_005_Rx:0, DET_AZIMUTH_006_Rx:0, DET_AZIMUTH_007_Rx:0, DET_AZIMUTH_008_Rx:0, DET_AZIMUTH_ERR_005_Rx:0, DET_AZIMUTH_ERR_006_Rx:0, DET_AZIMUTH_ERR_007_Rx:0, DET_AZIMUTH_ERR_008_Rx:0, DET_BELOW_RAIN_THOLD_005_Rx:0, DET_BELOW_RAIN_THOLD_006_Rx:0, DET_BELOW_RAIN_THOLD_007_Rx:0, DET_BELOW_RAIN_THOLD_008_Rx:0, DET_BI_STATIC_FLAG_005_Rx:0, DET_BI_STATIC_FLAG_006_Rx:0, DET_BI_STATIC_FLAG_007_Rx:0, DET_BI_STATIC_FLAG_008_Rx:0, DET_CONFD_AZIMUTH_005_Rx:0, DET_CONFD_AZIMUTH_006_Rx:0, DET_CONFD_AZIMUTH_007_Rx:0, DET_CONFD_AZIMUTH_008_Rx:0, DET_CONFD_ELEVATION_005_Rx:0, DET_CONFD_ELEVATION_006_Rx:0, DET_CONFD_ELEVATION_007_Rx:0, DET_CONFD_ELEVATION_008_Rx:0, DET_ELEVATION_005_Rx:0, DET_ELEVATION_006_Rx:0, DET_ELEVATION_007_Rx:0, DET_ELEVATION_008_Rx:0, DET_ELEVATION_ERR_005_Rx:0, DET_ELEVATION_ERR_006_Rx:0, DET_ELEVATION_ERR_007_Rx:0, DET_ELEVATION_ERR_008_Rx:0, DET_EXISTENCE_PROB_005_Rx:0, DET_EXISTENCE_PROB_006_Rx:0, DET_EXISTENCE_PROB_007_Rx:0, DET_EXISTENCE_PROB_008_Rx:0, DET_HVC_FLAG_005_Rx:0, DET_HVC_FLAG_006_Rx:0, DET_HVC_FLAG_007_Rx:0, DET_HVC_FLAG_008_Rx:0, DET_IDM_005_Rx:0, DET_IDM_006_Rx:0, DET_IDM_007_Rx:0, DET_IDM_008_Rx:0, DET_MH_CRC16_005_008_Rx:0, DET_MH_CYCLE_COUNTER_005_008_Rx:0, DET_MH_SCAN_INDEX_4LSB_005_008_Rx:0, DET_MTD_005_Rx:0, DET_MTD_006_Rx:0, DET_MTD_007_Rx:0, DET_MTD_008_Rx:0, DET_PROB_1STAZHYPO_005_Rx:0, DET_PROB_1STAZHYPO_006_Rx:0, DET_PROB_1STAZHYPO_007_Rx:0, DET_PROB_1STAZHYPO_008_Rx:0, DET_RANGE_005_Rx:0, DET_RANGE_006_Rx:0, DET_RANGE_007_Rx:0, DET_RANGE_008_Rx:0, DET_RANGE_ERR_005_Rx:0, DET_RANGE_ERR_006_Rx:0, DET_RANGE_ERR_007_Rx:0, DET_RANGE_ERR_008_Rx:0, DET_RANGE_VELOCITY_005_Rx:0, DET_RANGE_VELOCITY_006_Rx:0, DET_RANGE_VELOCITY_007_Rx:0, DET_RANGE_VELOCITY_008_Rx:0, DET_RANGE_VELOCITY_ERR_005_Rx:0, DET_RANGE_VELOCITY_ERR_006_Rx:0, DET_RANGE_VELOCITY_ERR_007_Rx:0, DET_RANGE_VELOCITY_ERR_008_Rx:0, DET_RCS_005_Rx:0, DET_RCS_006_Rx:0, DET_RCS_007_Rx:0, DET_RCS_008_Rx:0, DET_SNR_005_Rx:0, DET_SNR_006_Rx:0, DET_SNR_007_Rx:0, DET_SNR_008_Rx:0, DET_SUPER_RES_TARGET_005_Rx:0, DET_SUPER_RES_TARGET_006_Rx:0, DET_SUPER_RES_TARGET_007_Rx:0, DET_SUPER_RES_TARGET_008_Rx:0]}, required-interface=Pi_SG_Fusion_Detections_005_008_AL
      Rp_SG_Fusion_Detections_113_116_AL: nonqueued-receiver-com-spec{data-element=Vdp_SG_Fusion_Detections_113_116_AL, init-value=fields=[DET_AZIMUTH_113_Rx:0, DET_AZIMUTH_114_Rx:0, DET_AZIMUTH_115_Rx:0, DET_AZIMUTH_116_Rx:0, DET_AZIMUTH_ERR_113_Rx:0, DET_AZIMUTH_ERR_114_Rx:0, DET_AZIMUTH_ERR_115_Rx:0, DET_AZIMUTH_ERR_116_Rx:0, DET_BELOW_RAIN_THOLD_113_Rx:0, DET_BELOW_RAIN_THOLD_114_Rx:0, DET_BELOW_RAIN_THOLD_115_Rx:0, DET_BELOW_RAIN_THOLD_116_Rx:0, DET_BI_STATIC_FLAG_113_Rx:0, DET_BI_STATIC_FLAG_114_Rx:0, DET_BI_STATIC_FLAG_115_Rx:0, DET_BI_STATIC_FLAG_116_Rx:0, DET_CONFD_AZIMUTH_113_Rx:0, DET_CONFD_AZIMUTH_114_Rx:0, DET_CONFD_AZIMUTH_115_Rx:0, DET_CONFD_AZIMUTH_116_Rx:0, DET_CONFD_ELEVATION_113_Rx:0, DET_CONFD_ELEVATION_114_Rx:0, DET_CONFD_ELEVATION_115_Rx:0, DET_CONFD_ELEVATION_116_Rx:0, DET_ELEVATION_113_Rx:0, DET_ELEVATION_114_Rx:0, DET_ELEVATION_115_Rx:0, DET_ELEVATION_116_Rx:0, DET_ELEVATION_ERR_113_Rx:0, DET_ELEVATION_ERR_114_Rx:0, DET_ELEVATION_ERR_115_Rx:0, DET_ELEVATION_ERR_116_Rx:0, DET_EXISTENCE_PROB_113_Rx:0, DET_EXISTENCE_PROB_114_Rx:0, DET_EXISTENCE_PROB_115_Rx:0, DET_EXISTENCE_PROB_116_Rx:0, DET_HVC_FLAG_113_Rx:0, DET_HVC_FLAG_114_Rx:0, DET_HVC_FLAG_115_Rx:0, DET_HVC_FLAG_116_Rx:0, DET_IDM_113_Rx:0, DET_IDM_114_Rx:0, DET_IDM_115_Rx:0, DET_IDM_116_Rx:0, DET_MH_CRC16_113_116_Rx:0, DET_MH_CYCLE_COUNTER_113_116_Rx:0, DET_MH_SCAN_INDEX_4LSB_113_116_Rx:0, DET_MTD_113_Rx:0, DET_MTD_114_Rx:0, DET_MTD_115_Rx:0, DET_MTD_116_Rx:0, DET_PROB_1STAZHYPO_113_Rx:0, DET_PROB_1STAZHYPO_114_Rx:0, DET_PROB_1STAZHYPO_115_Rx:0, DET_PROB_1STAZHYPO_116_Rx:0, DET_RANGE_113_Rx:0, DET_RANGE_114_Rx:0, DET_RANGE_115_Rx:0, DET_RANGE_116_Rx:0, DET_RANGE_ERR_113_Rx:0, DET_RANGE_ERR_114_Rx:0, DET_RANGE_ERR_115_Rx:0, DET_RANGE_ERR_116_Rx:0, DET_RANGE_VELOCITY_113_Rx:0, DET_RANGE_VELOCITY_114_Rx:0, DET_RANGE_VELOCITY_115_Rx:0, DET_RANGE_VELOCITY_116_Rx:0, DET_RANGE_VELOCITY_ERR_113_Rx:0, DET_RANGE_VELOCITY_ERR_114_Rx:0, DET_RANGE_VELOCITY_ERR_115_Rx:0, DET_RANGE_VELOCITY_ERR_116_Rx:0, DET_RCS_113_Rx:0, DET_RCS_114_Rx:0, DET_RCS_115_Rx:0, DET_RCS_116_Rx:0, DET_SNR_113_Rx:0, DET_SNR_114_Rx:0, DET_SNR_115_Rx:0, DET_SNR_116_Rx:0, DET_SUPER_RES_TARGET_113_Rx:0, DET_SUPER_RES_TARGET_114_Rx:0, DET_SUPER_RES_TARGET_115_Rx:0, DET_SUPER_RES_TARGET_116_Rx:0]}, required-interface=Pi_SG_Fusion_Detections_113_116_AL
      Rp_SG_Fusion_Detections_049_052_AL: nonqueued-receiver-com-spec{data-element=Vdp_SG_Fusion_Detections_049_052_AL, init-value=fields=[DET_AZIMUTH_049_Rx:0, DET_AZIMUTH_050_Rx:0, DET_AZIMUTH_051_Rx:0, DET_AZIMUTH_052_Rx:0, DET_AZIMUTH_ERR_049_Rx:0, DET_AZIMUTH_ERR_050_Rx:0, DET_AZIMUTH_ERR_051_Rx:0, DET_AZIMUTH_ERR_052_Rx:0, DET_BELOW_RAIN_THOLD_049_Rx:0, DET_BELOW_RAIN_THOLD_050_Rx:0, DET_BELOW_RAIN_THOLD_051_Rx:0, DET_BELOW_RAIN_THOLD_052_Rx:0, DET_BI_STATIC_FLAG_049_Rx:0, DET_BI_STATIC_FLAG_050_Rx:0, DET_BI_STATIC_FLAG_051_Rx:0, DET_BI_STATIC_FLAG_052_Rx:0, DET_CONFD_AZIMUTH_049_Rx:0, DET_CONFD_AZIMUTH_050_Rx:0, DET_CONFD_AZIMUTH_051_Rx:0, DET_CONFD_AZIMUTH_052_Rx:0, DET_CONFD_ELEVATION_049_Rx:0, DET_CONFD_ELEVATION_050_Rx:0, DET_CONFD_ELEVATION_051_Rx:0, DET_CONFD_ELEVATION_052_Rx:0, DET_ELEVATION_049_Rx:0, DET_ELEVATION_050_Rx:0, DET_ELEVATION_051_Rx:0, DET_ELEVATION_052_Rx:0, DET_ELEVATION_ERR_049_Rx:0, DET_ELEVATION_ERR_050_Rx:0, DET_ELEVATION_ERR_051_Rx:0, DET_ELEVATION_ERR_052_Rx:0, DET_EXISTENCE_PROB_049_Rx:0, DET_EXISTENCE_PROB_050_Rx:0, DET_EXISTENCE_PROB_051_Rx:0, DET_EXISTENCE_PROB_052_Rx:0, DET_HVC_FLAG_049_Rx:0, DET_HVC_FLAG_050_Rx:0, DET_HVC_FLAG_051_Rx:0, DET_HVC_FLAG_052_Rx:0, DET_IDM_049_Rx:0, DET_IDM_050_Rx:0, DET_IDM_051_Rx:0, DET_IDM_052_Rx:0, DET_MH_CRC16_049_052_Rx:0, DET_MH_CYCLE_COUNTER_049_052_Rx:0, DET_MH_SCAN_INDEX_4LSB_049_052_Rx:0, DET_MTD_049_Rx:0, DET_MTD_050_Rx:0, DET_MTD_051_Rx:0, DET_MTD_052_Rx:0, DET_PROB_1STAZHYPO_049_Rx:0, DET_PROB_1STAZHYPO_050_Rx:0, DET_PROB_1STAZHYPO_051_Rx:0, DET_PROB_1STAZHYPO_052_Rx:0, DET_RANGE_049_Rx:0, DET_RANGE_050_Rx:0, DET_RANGE_051_Rx:0, DET_RANGE_052_Rx:0, DET_RANGE_ERR_049_Rx:0, DET_RANGE_ERR_050_Rx:0, DET_RANGE_ERR_051_Rx:0, DET_RANGE_ERR_052_Rx:0, DET_RANGE_VELOCITY_049_Rx:0, DET_RANGE_VELOCITY_050_Rx:0, DET_RANGE_VELOCITY_051_Rx:0, DET_RANGE_VELOCITY_052_Rx:0, DET_RANGE_VELOCITY_ERR_049_Rx:0, DET_RANGE_VELOCITY_ERR_050_Rx:0, DET_RANGE_VELOCITY_ERR_051_Rx:0, DET_RANGE_VELOCITY_ERR_052_Rx:0, DET_RCS_049_Rx:0, DET_RCS_050_Rx:0, DET_RCS_051_Rx:0, DET_RCS_052_Rx:0, DET_SNR_049_Rx:0, DET_SNR_050_Rx:0, DET_SNR_051_Rx:0, DET_SNR_052_Rx:0, DET_SUPER_RES_TARGET_049_Rx:0, DET_SUPER_RES_TARGET_050_Rx:0, DET_SUPER_RES_TARGET_051_Rx:0, DET_SUPER_RES_TARGET_052_Rx:0]}, required-interface=Pi_SG_Fusion_Detections_049_052_AL
      Rp_SG_Fusion_Detections_109_112_AL: nonqueued-receiver-com-spec{data-element=Vdp_SG_Fusion_Detections_109_112_AL, init-value=fields=[DET_AZIMUTH_109_Rx:0, DET_AZIMUTH_110_Rx:0, DET_AZIMUTH_111_Rx:0, DET_AZIMUTH_112_Rx:0, DET_AZIMUTH_ERR_109_Rx:0, DET_AZIMUTH_ERR_110_Rx:0, DET_AZIMUTH_ERR_111_Rx:0, DET_AZIMUTH_ERR_112_Rx:0, DET_BELOW_RAIN_THOLD_109_Rx:0, DET_BELOW_RAIN_THOLD_110_Rx:0, DET_BELOW_RAIN_THOLD_111_Rx:0, DET_BELOW_RAIN_THOLD_112_Rx:0, DET_BI_STATIC_FLAG_109_Rx:0, DET_BI_STATIC_FLAG_110_Rx:0, DET_BI_STATIC_FLAG_111_Rx:0, DET_BI_STATIC_FLAG_112_Rx:0, DET_CONFD_AZIMUTH_109_Rx:0, DET_CONFD_AZIMUTH_110_Rx:0, DET_CONFD_AZIMUTH_111_Rx:0, DET_CONFD_AZIMUTH_112_Rx:0, DET_CONFD_ELEVATION_109_Rx:0, DET_CONFD_ELEVATION_110_Rx:0, DET_CONFD_ELEVATION_111_Rx:0, DET_CONFD_ELEVATION_112_Rx:0, DET_ELEVATION_109_Rx:0, DET_ELEVATION_110_Rx:0, DET_ELEVATION_111_Rx:0, DET_ELEVATION_112_Rx:0, DET_ELEVATION_ERR_109_Rx:0, DET_ELEVATION_ERR_110_Rx:0, DET_ELEVATION_ERR_111_Rx:0, DET_ELEVATION_ERR_112_Rx:0, DET_EXISTENCE_PROB_109_Rx:0, DET_EXISTENCE_PROB_110_Rx:0, DET_EXISTENCE_PROB_111_Rx:0, DET_EXISTENCE_PROB_112_Rx:0, DET_HVC_FLAG_109_Rx:0, DET_HVC_FLAG_110_Rx:0, DET_HVC_FLAG_111_Rx:0, DET_HVC_FLAG_112_Rx:0, DET_IDM_109_Rx:0, DET_IDM_110_Rx:0, DET_IDM_111_Rx:0, DET_IDM_112_Rx:0, DET_MH_CRC16_109_112_Rx:0, DET_MH_CYCLE_COUNTER_109_112_Rx:0, DET_MH_SCAN_INDEX_4LSB_109_112_Rx:0, DET_MTD_109_Rx:0, DET_MTD_110_Rx:0, DET_MTD_111_Rx:0, DET_MTD_112_Rx:0, DET_PROB_1STAZHYPO_109_Rx:0, DET_PROB_1STAZHYPO_110_Rx:0, DET_PROB_1STAZHYPO_111_Rx:0, DET_PROB_1STAZHYPO_112_Rx:0, DET_RANGE_109_Rx:0, DET_RANGE_110_Rx:0, DET_RANGE_111_Rx:0, DET_RANGE_112_Rx:0, DET_RANGE_ERR_109_Rx:0, DET_RANGE_ERR_110_Rx:0, DET_RANGE_ERR_111_Rx:0, DET_RANGE_ERR_112_Rx:0, DET_RANGE_VELOCITY_109_Rx:0, DET_RANGE_VELOCITY_110_Rx:0, DET_RANGE_VELOCITY_111_Rx:0, DET_RANGE_VELOCITY_112_Rx:0, DET_RANGE_VELOCITY_ERR_109_Rx:0, DET_RANGE_VELOCITY_ERR_110_Rx:0, DET_RANGE_VELOCITY_ERR_111_Rx:0, DET_RANGE_VELOCITY_ERR_112_Rx:0, DET_RCS_109_Rx:0, DET_RCS_110_Rx:0, DET_RCS_111_Rx:0, DET_RCS_112_Rx:0, DET_SNR_109_Rx:0, DET_SNR_110_Rx:0, DET_SNR_111_Rx:0, DET_SNR_112_Rx:0, DET_SUPER_RES_TARGET_109_Rx:0, DET_SUPER_RES_TARGET_110_Rx:0, DET_SUPER_RES_TARGET_111_Rx:0, DET_SUPER_RES_TARGET_112_Rx:0]}, required-interface=Pi_SG_Fusion_Detections_109_112_AL
      Rp_SG_Fusion_Detections_093_096_AL: nonqueued-receiver-com-spec{data-element=Vdp_SG_Fusion_Detections_093_096_AL, init-value=fields=[DET_AZIMUTH_093_Rx:0, DET_AZIMUTH_094_Rx:0, DET_AZIMUTH_095_Rx:0, DET_AZIMUTH_096_Rx:0, DET_AZIMUTH_ERR_093_Rx:0, DET_AZIMUTH_ERR_094_Rx:0, DET_AZIMUTH_ERR_095_Rx:0, DET_AZIMUTH_ERR_096_Rx:0, DET_BELOW_RAIN_THOLD_093_Rx:0, DET_BELOW_RAIN_THOLD_094_Rx:0, DET_BELOW_RAIN_THOLD_095_Rx:0, DET_BELOW_RAIN_THOLD_096_Rx:0, DET_BI_STATIC_FLAG_093_Rx:0, DET_BI_STATIC_FLAG_094_Rx:0, DET_BI_STATIC_FLAG_095_Rx:0, DET_BI_STATIC_FLAG_096_Rx:0, DET_CONFD_AZIMUTH_093_Rx:0, DET_CONFD_AZIMUTH_094_Rx:0, DET_CONFD_AZIMUTH_095_Rx:0, DET_CONFD_AZIMUTH_096_Rx:0, DET_CONFD_ELEVATION_093_Rx:0, DET_CONFD_ELEVATION_094_Rx:0, DET_CONFD_ELEVATION_095_Rx:0, DET_CONFD_ELEVATION_096_Rx:0, DET_ELEVATION_093_Rx:0, DET_ELEVATION_094_Rx:0, DET_ELEVATION_095_Rx:0, DET_ELEVATION_096_Rx:0, DET_ELEVATION_ERR_093_Rx:0, DET_ELEVATION_ERR_094_Rx:0, DET_ELEVATION_ERR_095_Rx:0, DET_ELEVATION_ERR_096_Rx:0, DET_EXISTENCE_PROB_093_Rx:0, DET_EXISTENCE_PROB_094_Rx:0, DET_EXISTENCE_PROB_095_Rx:0, DET_EXISTENCE_PROB_096_Rx:0, DET_HVC_FLAG_093_Rx:0, DET_HVC_FLAG_094_Rx:0, DET_HVC_FLAG_095_Rx:0, DET_HVC_FLAG_096_Rx:0, DET_IDM_093_Rx:0, DET_IDM_094_Rx:0, DET_IDM_095_Rx:0, DET_IDM_096_Rx:0, DET_MH_CRC16_093_096_Rx:0, DET_MH_CYCLE_COUNTER_093_096_Rx:0, DET_MH_SCAN_INDEX_4LSB_093_096_Rx:0, DET_MTD_093_Rx:0, DET_MTD_094_Rx:0, DET_MTD_095_Rx:0, DET_MTD_096_Rx:0, DET_PROB_1STAZHYPO_093_Rx:0, DET_PROB_1STAZHYPO_094_Rx:0, DET_PROB_1STAZHYPO_095_Rx:0, DET_PROB_1STAZHYPO_096_Rx:0, DET_RANGE_093_Rx:0, DET_RANGE_094_Rx:0, DET_RANGE_095_Rx:0, DET_RANGE_096_Rx:0, DET_RANGE_ERR_093_Rx:0, DET_RANGE_ERR_094_Rx:0, DET_RANGE_ERR_095_Rx:0, DET_RANGE_ERR_096_Rx:0, DET_RANGE_VELOCITY_093_Rx:0, DET_RANGE_VELOCITY_094_Rx:0, DET_RANGE_VELOCITY_095_Rx:0, DET_RANGE_VELOCITY_096_Rx:0, DET_RANGE_VELOCITY_ERR_093_Rx:0, DET_RANGE_VELOCITY_ERR_094_Rx:0, DET_RANGE_VELOCITY_ERR_095_Rx:0, DET_RANGE_VELOCITY_ERR_096_Rx:0, DET_RCS_093_Rx:0, DET_RCS_094_Rx:0, DET_RCS_095_Rx:0, DET_RCS_096_Rx:0, DET_SNR_093_Rx:0, DET_SNR_094_Rx:0, DET_SNR_095_Rx:0, DET_SNR_096_Rx:0, DET_SUPER_RES_TARGET_093_Rx:0, DET_SUPER_RES_TARGET_094_Rx:0, DET_SUPER_RES_TARGET_095_Rx:0, DET_SUPER_RES_TARGET_096_Rx:0]}, required-interface=Pi_SG_Fusion_Detections_093_096_AL
      Rp_SG_Fusion_Detections_125_128_AL: nonqueued-receiver-com-spec{data-element=Vdp_SG_Fusion_Detections_125_128_AL, init-value=fields=[DET_AZIMUTH_125_Rx:0, DET_AZIMUTH_126_Rx:0, DET_AZIMUTH_127_Rx:0, DET_AZIMUTH_128_Rx:0, DET_AZIMUTH_ERR_125_Rx:0, DET_AZIMUTH_ERR_126_Rx:0, DET_AZIMUTH_ERR_127_Rx:0, DET_AZIMUTH_ERR_128_Rx:0, DET_BELOW_RAIN_THOLD_125_Rx:0, DET_BELOW_RAIN_THOLD_126_Rx:0, DET_BELOW_RAIN_THOLD_127_Rx:0, DET_BELOW_RAIN_THOLD_128_Rx:0, DET_BI_STATIC_FLAG_125_Rx:0, DET_BI_STATIC_FLAG_126_Rx:0, DET_BI_STATIC_FLAG_127_Rx:0, DET_BI_STATIC_FLAG_128_Rx:0, DET_CONFD_AZIMUTH_125_Rx:0, DET_CONFD_AZIMUTH_126_Rx:0, DET_CONFD_AZIMUTH_127_Rx:0, DET_CONFD_AZIMUTH_128_Rx:0, DET_CONFD_ELEVATION_125_Rx:0, DET_CONFD_ELEVATION_126_Rx:0, DET_CONFD_ELEVATION_127_Rx:0, DET_CONFD_ELEVATION_128_Rx:0, DET_ELEVATION_125_Rx:0, DET_ELEVATION_126_Rx:0, DET_ELEVATION_127_Rx:0, DET_ELEVATION_128_Rx:0, DET_ELEVATION_ERR_125_Rx:0, DET_ELEVATION_ERR_126_Rx:0, DET_ELEVATION_ERR_127_Rx:0, DET_ELEVATION_ERR_128_Rx:0, DET_EXISTENCE_PROB_125_Rx:0, DET_EXISTENCE_PROB_126_Rx:0, DET_EXISTENCE_PROB_127_Rx:0, DET_EXISTENCE_PROB_128_Rx:0, DET_HVC_FLAG_125_Rx:0, DET_HVC_FLAG_126_Rx:0, DET_HVC_FLAG_127_Rx:0, DET_HVC_FLAG_128_Rx:0, DET_IDM_125_Rx:0, DET_IDM_126_Rx:0, DET_IDM_127_Rx:0, DET_IDM_128_Rx:0, DET_MH_CRC16_125_128_Rx:0, DET_MH_CYCLE_COUNTER_125_128_Rx:0, DET_MH_SCAN_INDEX_4LSB_125_128_Rx:0, DET_MTD_125_Rx:0, DET_MTD_126_Rx:0, DET_MTD_127_Rx:0, DET_MTD_128_Rx:0, DET_PROB_1STAZHYPO_125_Rx:0, DET_PROB_1STAZHYPO_126_Rx:0, DET_PROB_1STAZHYPO_127_Rx:0, DET_PROB_1STAZHYPO_128_Rx:0, DET_RANGE_125_Rx:0, DET_RANGE_126_Rx:0, DET_RANGE_127_Rx:0, DET_RANGE_128_Rx:0, DET_RANGE_ERR_125_Rx:0, DET_RANGE_ERR_126_Rx:0, DET_RANGE_ERR_127_Rx:0, DET_RANGE_ERR_128_Rx:0, DET_RANGE_VELOCITY_125_Rx:0, DET_RANGE_VELOCITY_126_Rx:0, DET_RANGE_VELOCITY_127_Rx:0, DET_RANGE_VELOCITY_128_Rx:0, DET_RANGE_VELOCITY_ERR_125_Rx:0, DET_RANGE_VELOCITY_ERR_126_Rx:0, DET_RANGE_VELOCITY_ERR_127_Rx:0, DET_RANGE_VELOCITY_ERR_128_Rx:0, DET_RCS_125_Rx:0, DET_RCS_126_Rx:0, DET_RCS_127_Rx:0, DET_RCS_128_Rx:0, DET_SNR_125_Rx:0, DET_SNR_126_Rx:0, DET_SNR_127_Rx:0, DET_SNR_128_Rx:0, DET_SUPER_RES_TARGET_125_Rx:0, DET_SUPER_RES_TARGET_126_Rx:0, DET_SUPER_RES_TARGET_127_Rx:0, DET_SUPER_RES_TARGET_128_Rx:0]}, required-interface=Pi_SG_Fusion_Detections_125_128_AL
      Rp_SG_Fusion_Detections_085_088_AL: nonqueued-receiver-com-spec{data-element=Vdp_SG_Fusion_Detections_085_088_AL, init-value=fields=[DET_AZIMUTH_085_Rx:0, DET_AZIMUTH_086_Rx:0, DET_AZIMUTH_087_Rx:0, DET_AZIMUTH_088_Rx:0, DET_AZIMUTH_ERR_085_Rx:0, DET_AZIMUTH_ERR_086_Rx:0, DET_AZIMUTH_ERR_087_Rx:0, DET_AZIMUTH_ERR_088_Rx:0, DET_BELOW_RAIN_THOLD_085_Rx:0, DET_BELOW_RAIN_THOLD_086_Rx:0, DET_BELOW_RAIN_THOLD_087_Rx:0, DET_BELOW_RAIN_THOLD_088_Rx:0, DET_BI_STATIC_FLAG_085_Rx:0, DET_BI_STATIC_FLAG_086_Rx:0, DET_BI_STATIC_FLAG_087_Rx:0, DET_BI_STATIC_FLAG_088_Rx:0, DET_CONFD_AZIMUTH_085_Rx:0, DET_CONFD_AZIMUTH_086_Rx:0, DET_CONFD_AZIMUTH_087_Rx:0, DET_CONFD_AZIMUTH_088_Rx:0, DET_CONFD_ELEVATION_085_Rx:0, DET_CONFD_ELEVATION_086_Rx:0, DET_CONFD_ELEVATION_087_Rx:0, DET_CONFD_ELEVATION_088_Rx:0, DET_ELEVATION_085_Rx:0, DET_ELEVATION_086_Rx:0, DET_ELEVATION_087_Rx:0, DET_ELEVATION_088_Rx:0, DET_ELEVATION_ERR_085_Rx:0, DET_ELEVATION_ERR_086_Rx:0, DET_ELEVATION_ERR_087_Rx:0, DET_ELEVATION_ERR_088_Rx:0, DET_EXISTENCE_PROB_085_Rx:0, DET_EXISTENCE_PROB_086_Rx:0, DET_EXISTENCE_PROB_087_Rx:0, DET_EXISTENCE_PROB_088_Rx:0, DET_HVC_FLAG_085_Rx:0, DET_HVC_FLAG_086_Rx:0, DET_HVC_FLAG_087_Rx:0, DET_HVC_FLAG_088_Rx:0, DET_IDM_085_Rx:0, DET_IDM_086_Rx:0, DET_IDM_087_Rx:0, DET_IDM_088_Rx:0, DET_MH_CRC16_085_088_Rx:0, DET_MH_CYCLE_COUNTER_085_088_Rx:0, DET_MH_SCAN_INDEX_4LSB_085_088_Rx:0, DET_MTD_085_Rx:0, DET_MTD_086_Rx:0, DET_MTD_087_Rx:0, DET_MTD_088_Rx:0, DET_PROB_1STAZHYPO_085_Rx:0, DET_PROB_1STAZHYPO_086_Rx:0, DET_PROB_1STAZHYPO_087_Rx:0, DET_PROB_1STAZHYPO_088_Rx:0, DET_RANGE_085_Rx:0, DET_RANGE_086_Rx:0, DET_RANGE_087_Rx:0, DET_RANGE_088_Rx:0, DET_RANGE_ERR_085_Rx:0, DET_RANGE_ERR_086_Rx:0, DET_RANGE_ERR_087_Rx:0, DET_RANGE_ERR_088_Rx:0, DET_RANGE_VELOCITY_085_Rx:0, DET_RANGE_VELOCITY_086_Rx:0, DET_RANGE_VELOCITY_087_Rx:0, DET_RANGE_VELOCITY_088_Rx:0, DET_RANGE_VELOCITY_ERR_085_Rx:0, DET_RANGE_VELOCITY_ERR_086_Rx:0, DET_RANGE_VELOCITY_ERR_087_Rx:0, DET_RANGE_VELOCITY_ERR_088_Rx:0, DET_RCS_085_Rx:0, DET_RCS_086_Rx:0, DET_RCS_087_Rx:0, DET_RCS_088_Rx:0, DET_SNR_085_Rx:0, DET_SNR_086_Rx:0, DET_SNR_087_Rx:0, DET_SNR_088_Rx:0, DET_SUPER_RES_TARGET_085_Rx:0, DET_SUPER_RES_TARGET_086_Rx:0, DET_SUPER_RES_TARGET_087_Rx:0, DET_SUPER_RES_TARGET_088_Rx:0]}, required-interface=Pi_SG_Fusion_Detections_085_088_AL
      Rp_SG_Fusion_Detections_041_044_AL: nonqueued-receiver-com-spec{data-element=Vdp_SG_Fusion_Detections_041_044_AL, init-value=fields=[DET_AZIMUTH_041_Rx:0, DET_AZIMUTH_042_Rx:0, DET_AZIMUTH_043_Rx:0, DET_AZIMUTH_044_Rx:0, DET_AZIMUTH_ERR_041_Rx:0, DET_AZIMUTH_ERR_042_Rx:0, DET_AZIMUTH_ERR_043_Rx:0, DET_AZIMUTH_ERR_044_Rx:0, DET_BELOW_RAIN_THOLD_041_Rx:0, DET_BELOW_RAIN_THOLD_042_Rx:0, DET_BELOW_RAIN_THOLD_043_Rx:0, DET_BELOW_RAIN_THOLD_044_Rx:0, DET_BI_STATIC_FLAG_041_Rx:0, DET_BI_STATIC_FLAG_042_Rx:0, DET_BI_STATIC_FLAG_043_Rx:0, DET_BI_STATIC_FLAG_044_Rx:0, DET_CONFD_AZIMUTH_041_Rx:0, DET_CONFD_AZIMUTH_042_Rx:0, DET_CONFD_AZIMUTH_043_Rx:0, DET_CONFD_AZIMUTH_044_Rx:0, DET_CONFD_ELEVATION_041_Rx:0, DET_CONFD_ELEVATION_042_Rx:0, DET_CONFD_ELEVATION_043_Rx:0, DET_CONFD_ELEVATION_044_Rx:0, DET_ELEVATION_041_Rx:0, DET_ELEVATION_042_Rx:0, DET_ELEVATION_043_Rx:0, DET_ELEVATION_044_Rx:0, DET_ELEVATION_ERR_041_Rx:0, DET_ELEVATION_ERR_042_Rx:0, DET_ELEVATION_ERR_043_Rx:0, DET_ELEVATION_ERR_044_Rx:0, DET_EXISTENCE_PROB_041_Rx:0, DET_EXISTENCE_PROB_042_Rx:0, DET_EXISTENCE_PROB_043_Rx:0, DET_EXISTENCE_PROB_044_Rx:0, DET_HVC_FLAG_041_Rx:0, DET_HVC_FLAG_042_Rx:0, DET_HVC_FLAG_043_Rx:0, DET_HVC_FLAG_044_Rx:0, DET_IDM_041_Rx:0, DET_IDM_042_Rx:0, DET_IDM_043_Rx:0, DET_IDM_044_Rx:0, DET_MH_CRC16_041_044_Rx:0, DET_MH_CYCLE_COUNTER_041_044_Rx:0, DET_MH_SCAN_INDEX_4LSB_041_044_Rx:0, DET_MTD_041_Rx:0, DET_MTD_042_Rx:0, DET_MTD_043_Rx:0, DET_MTD_044_Rx:0, DET_PROB_1STAZHYPO_041_Rx:0, DET_PROB_1STAZHYPO_042_Rx:0, DET_PROB_1STAZHYPO_043_Rx:0, DET_PROB_1STAZHYPO_044_Rx:0, DET_RANGE_041_Rx:0, DET_RANGE_042_Rx:0, DET_RANGE_043_Rx:0, DET_RANGE_044_Rx:0, DET_RANGE_ERR_041_Rx:0, DET_RANGE_ERR_042_Rx:0, DET_RANGE_ERR_043_Rx:0, DET_RANGE_ERR_044_Rx:0, DET_RANGE_VELOCITY_041_Rx:0, DET_RANGE_VELOCITY_042_Rx:0, DET_RANGE_VELOCITY_043_Rx:0, DET_RANGE_VELOCITY_044_Rx:0, DET_RANGE_VELOCITY_ERR_041_Rx:0, DET_RANGE_VELOCITY_ERR_042_Rx:0, DET_RANGE_VELOCITY_ERR_043_Rx:0, DET_RANGE_VELOCITY_ERR_044_Rx:0, DET_RCS_041_Rx:0, DET_RCS_042_Rx:0, DET_RCS_043_Rx:0, DET_RCS_044_Rx:0, DET_SNR_041_Rx:0, DET_SNR_042_Rx:0, DET_SNR_043_Rx:0, DET_SNR_044_Rx:0, DET_SUPER_RES_TARGET_041_Rx:0, DET_SUPER_RES_TARGET_042_Rx:0, DET_SUPER_RES_TARGET_043_Rx:0, DET_SUPER_RES_TARGET_044_Rx:0]}, required-interface=Pi_SG_Fusion_Detections_041_044_AL
      Rp_SG_Fusion_Detections_061_064_AL: nonqueued-receiver-com-spec{data-element=Vdp_SG_Fusion_Detections_061_064_AL, init-value=fields=[DET_AZIMUTH_061_Rx:0, DET_AZIMUTH_062_Rx:0, DET_AZIMUTH_063_Rx:0, DET_AZIMUTH_064_Rx:0, DET_AZIMUTH_ERR_061_Rx:0, DET_AZIMUTH_ERR_062_Rx:0, DET_AZIMUTH_ERR_063_Rx:0, DET_AZIMUTH_ERR_064_Rx:0, DET_BELOW_RAIN_THOLD_061_Rx:0, DET_BELOW_RAIN_THOLD_062_Rx:0, DET_BELOW_RAIN_THOLD_063_Rx:0, DET_BELOW_RAIN_THOLD_064_Rx:0, DET_BI_STATIC_FLAG_061_Rx:0, DET_BI_STATIC_FLAG_062_Rx:0, DET_BI_STATIC_FLAG_063_Rx:0, DET_BI_STATIC_FLAG_064_Rx:0, DET_CONFD_AZIMUTH_061_Rx:0, DET_CONFD_AZIMUTH_062_Rx:0, DET_CONFD_AZIMUTH_063_Rx:0, DET_CONFD_AZIMUTH_064_Rx:0, DET_CONFD_ELEVATION_061_Rx:0, DET_CONFD_ELEVATION_062_Rx:0, DET_CONFD_ELEVATION_063_Rx:0, DET_CONFD_ELEVATION_064_Rx:0, DET_ELEVATION_061_Rx:0, DET_ELEVATION_062_Rx:0, DET_ELEVATION_063_Rx:0, DET_ELEVATION_064_Rx:0, DET_ELEVATION_ERR_061_Rx:0, DET_ELEVATION_ERR_062_Rx:0, DET_ELEVATION_ERR_063_Rx:0, DET_ELEVATION_ERR_064_Rx:0, DET_EXISTENCE_PROB_061_Rx:0, DET_EXISTENCE_PROB_062_Rx:0, DET_EXISTENCE_PROB_063_Rx:0, DET_EXISTENCE_PROB_064_Rx:0, DET_HVC_FLAG_061_Rx:0, DET_HVC_FLAG_062_Rx:0, DET_HVC_FLAG_063_Rx:0, DET_HVC_FLAG_064_Rx:0, DET_IDM_061_Rx:0, DET_IDM_062_Rx:0, DET_IDM_063_Rx:0, DET_IDM_064_Rx:0, DET_MH_CRC16_061_064_Rx:0, DET_MH_CYCLE_COUNTER_061_064_Rx:0, DET_MH_SCAN_INDEX_4LSB_061_064_Rx:0, DET_MTD_061_Rx:0, DET_MTD_062_Rx:0, DET_MTD_063_Rx:0, DET_MTD_064_Rx:0, DET_PROB_1STAZHYPO_061_Rx:0, DET_PROB_1STAZHYPO_062_Rx:0, DET_PROB_1STAZHYPO_063_Rx:0, DET_PROB_1STAZHYPO_064_Rx:0, DET_RANGE_061_Rx:0, DET_RANGE_062_Rx:0, DET_RANGE_063_Rx:0, DET_RANGE_064_Rx:0, DET_RANGE_ERR_061_Rx:0, DET_RANGE_ERR_062_Rx:0, DET_RANGE_ERR_063_Rx:0, DET_RANGE_ERR_064_Rx:0, DET_RANGE_VELOCITY_061_Rx:0, DET_RANGE_VELOCITY_062_Rx:0, DET_RANGE_VELOCITY_063_Rx:0, DET_RANGE_VELOCITY_064_Rx:0, DET_RANGE_VELOCITY_ERR_061_Rx:0, DET_RANGE_VELOCITY_ERR_062_Rx:0, DET_RANGE_VELOCITY_ERR_063_Rx:0, DET_RANGE_VELOCITY_ERR_064_Rx:0, DET_RCS_061_Rx:0, DET_RCS_062_Rx:0, DET_RCS_063_Rx:0, DET_RCS_064_Rx:0, DET_SNR_061_Rx:0, DET_SNR_062_Rx:0, DET_SNR_063_Rx:0, DET_SNR_064_Rx:0, DET_SUPER_RES_TARGET_061_Rx:0, DET_SUPER_RES_TARGET_062_Rx:0, DET_SUPER_RES_TARGET_063_Rx:0, DET_SUPER_RES_TARGET_064_Rx:0]}, required-interface=Pi_SG_Fusion_Detections_061_064_AL
      Rp_SG_Fusion_Detections_089_092_AL: nonqueued-receiver-com-spec{data-element=Vdp_SG_Fusion_Detections_089_092_AL, init-value=fields=[DET_AZIMUTH_089_Rx:0, DET_AZIMUTH_090_Rx:0, DET_AZIMUTH_091_Rx:0, DET_AZIMUTH_092_Rx:0, DET_AZIMUTH_ERR_089_Rx:0, DET_AZIMUTH_ERR_090_Rx:0, DET_AZIMUTH_ERR_091_Rx:0, DET_AZIMUTH_ERR_092_Rx:0, DET_BELOW_RAIN_THOLD_089_Rx:0, DET_BELOW_RAIN_THOLD_090_Rx:0, DET_BELOW_RAIN_THOLD_091_Rx:0, DET_BELOW_RAIN_THOLD_092_Rx:0, DET_BI_STATIC_FLAG_089_Rx:0, DET_BI_STATIC_FLAG_090_Rx:0, DET_BI_STATIC_FLAG_091_Rx:0, DET_BI_STATIC_FLAG_092_Rx:0, DET_CONFD_AZIMUTH_089_Rx:0, DET_CONFD_AZIMUTH_090_Rx:0, DET_CONFD_AZIMUTH_091_Rx:0, DET_CONFD_AZIMUTH_092_Rx:0, DET_CONFD_ELEVATION_089_Rx:0, DET_CONFD_ELEVATION_090_Rx:0, DET_CONFD_ELEVATION_091_Rx:0, DET_CONFD_ELEVATION_092_Rx:0, DET_ELEVATION_089_Rx:0, DET_ELEVATION_090_Rx:0, DET_ELEVATION_091_Rx:0, DET_ELEVATION_092_Rx:0, DET_ELEVATION_ERR_089_Rx:0, DET_ELEVATION_ERR_090_Rx:0, DET_ELEVATION_ERR_091_Rx:0, DET_ELEVATION_ERR_092_Rx:0, DET_EXISTENCE_PROB_089_Rx:0, DET_EXISTENCE_PROB_090_Rx:0, DET_EXISTENCE_PROB_091_Rx:0, DET_EXISTENCE_PROB_092_Rx:0, DET_HVC_FLAG_089_Rx:0, DET_HVC_FLAG_090_Rx:0, DET_HVC_FLAG_091_Rx:0, DET_HVC_FLAG_092_Rx:0, DET_IDM_089_Rx:0, DET_IDM_090_Rx:0, DET_IDM_091_Rx:0, DET_IDM_092_Rx:0, DET_MH_CRC16_089_092_Rx:0, DET_MH_CYCLE_COUNTER_089_092_Rx:0, DET_MH_SCAN_INDEX_4LSB_089_092_Rx:0, DET_MTD_089_Rx:0, DET_MTD_090_Rx:0, DET_MTD_091_Rx:0, DET_MTD_092_Rx:0, DET_PROB_1STAZHYPO_089_Rx:0, DET_PROB_1STAZHYPO_090_Rx:0, DET_PROB_1STAZHYPO_091_Rx:0, DET_PROB_1STAZHYPO_092_Rx:0, DET_RANGE_089_Rx:0, DET_RANGE_090_Rx:0, DET_RANGE_091_Rx:0, DET_RANGE_092_Rx:0, DET_RANGE_ERR_089_Rx:0, DET_RANGE_ERR_090_Rx:0, DET_RANGE_ERR_091_Rx:0, DET_RANGE_ERR_092_Rx:0, DET_RANGE_VELOCITY_089_Rx:0, DET_RANGE_VELOCITY_090_Rx:0, DET_RANGE_VELOCITY_091_Rx:0, DET_RANGE_VELOCITY_092_Rx:0, DET_RANGE_VELOCITY_ERR_089_Rx:0, DET_RANGE_VELOCITY_ERR_090_Rx:0, DET_RANGE_VELOCITY_ERR_091_Rx:0, DET_RANGE_VELOCITY_ERR_092_Rx:0, DET_RCS_089_Rx:0, DET_RCS_090_Rx:0, DET_RCS_091_Rx:0, DET_RCS_092_Rx:0, DET_SNR_089_Rx:0, DET_SNR_090_Rx:0, DET_SNR_091_Rx:0, DET_SNR_092_Rx:0, DET_SUPER_RES_TARGET_089_Rx:0, DET_SUPER_RES_TARGET_090_Rx:0, DET_SUPER_RES_TARGET_091_Rx:0, DET_SUPER_RES_TARGET_092_Rx:0]}, required-interface=Pi_SG_Fusion_Detections_089_092_AL
      Rp_SG_Fusion_Detections_021_024_AL: nonqueued-receiver-com-spec{data-element=Vdp_SG_Fusion_Detections_021_024_AL, init-value=fields=[DET_AZIMUTH_021_Rx:0, DET_AZIMUTH_022_Rx:0, DET_AZIMUTH_023_Rx:0, DET_AZIMUTH_024_Rx:0, DET_AZIMUTH_ERR_021_Rx:0, DET_AZIMUTH_ERR_022_Rx:0, DET_AZIMUTH_ERR_023_Rx:0, DET_AZIMUTH_ERR_024_Rx:0, DET_BELOW_RAIN_THOLD_021_Rx:0, DET_BELOW_RAIN_THOLD_022_Rx:0, DET_BELOW_RAIN_THOLD_023_Rx:0, DET_BELOW_RAIN_THOLD_024_Rx:0, DET_BI_STATIC_FLAG_021_Rx:0, DET_BI_STATIC_FLAG_022_Rx:0, DET_BI_STATIC_FLAG_023_Rx:0, DET_BI_STATIC_FLAG_024_Rx:0, DET_CONFD_AZIMUTH_021_Rx:0, DET_CONFD_AZIMUTH_022_Rx:0, DET_CONFD_AZIMUTH_023_Rx:0, DET_CONFD_AZIMUTH_024_Rx:0, DET_CONFD_ELEVATION_021_Rx:0, DET_CONFD_ELEVATION_022_Rx:0, DET_CONFD_ELEVATION_023_Rx:0, DET_CONFD_ELEVATION_024_Rx:0, DET_ELEVATION_021_Rx:0, DET_ELEVATION_022_Rx:0, DET_ELEVATION_023_Rx:0, DET_ELEVATION_024_Rx:0, DET_ELEVATION_ERR_021_Rx:0, DET_ELEVATION_ERR_022_Rx:0, DET_ELEVATION_ERR_023_Rx:0, DET_ELEVATION_ERR_024_Rx:0, DET_EXISTENCE_PROB_021_Rx:0, DET_EXISTENCE_PROB_022_Rx:0, DET_EXISTENCE_PROB_023_Rx:0, DET_EXISTENCE_PROB_024_Rx:0, DET_HVC_FLAG_021_Rx:0, DET_HVC_FLAG_022_Rx:0, DET_HVC_FLAG_023_Rx:0, DET_HVC_FLAG_024_Rx:0, DET_IDM_021_Rx:0, DET_IDM_022_Rx:0, DET_IDM_023_Rx:0, DET_IDM_024_Rx:0, DET_MH_CRC16_021_024_Rx:0, DET_MH_CYCLE_COUNTER_021_024_Rx:0, DET_MH_SCAN_INDEX_4LSB_021_024_Rx:0, DET_MTD_021_Rx:0, DET_MTD_022_Rx:0, DET_MTD_023_Rx:0, DET_MTD_024_Rx:0, DET_PROB_1STAZHYPO_021_Rx:0, DET_PROB_1STAZHYPO_022_Rx:0, DET_PROB_1STAZHYPO_023_Rx:0, DET_PROB_1STAZHYPO_024_Rx:0, DET_RANGE_021_Rx:0, DET_RANGE_022_Rx:0, DET_RANGE_023_Rx:0, DET_RANGE_024_Rx:0, DET_RANGE_ERR_021_Rx:0, DET_RANGE_ERR_022_Rx:0, DET_RANGE_ERR_023_Rx:0, DET_RANGE_ERR_024_Rx:0, DET_RANGE_VELOCITY_021_Rx:0, DET_RANGE_VELOCITY_022_Rx:0, DET_RANGE_VELOCITY_023_Rx:0, DET_RANGE_VELOCITY_024_Rx:0, DET_RANGE_VELOCITY_ERR_021_Rx:0, DET_RANGE_VELOCITY_ERR_022_Rx:0, DET_RANGE_VELOCITY_ERR_023_Rx:0, DET_RANGE_VELOCITY_ERR_024_Rx:0, DET_RCS_021_Rx:0, DET_RCS_022_Rx:0, DET_RCS_023_Rx:0, DET_RCS_024_Rx:0, DET_SNR_021_Rx:0, DET_SNR_022_Rx:0, DET_SNR_023_Rx:0, DET_SNR_024_Rx:0, DET_SUPER_RES_TARGET_021_Rx:0, DET_SUPER_RES_TARGET_022_Rx:0, DET_SUPER_RES_TARGET_023_Rx:0, DET_SUPER_RES_TARGET_024_Rx:0]}, required-interface=Pi_SG_Fusion_Detections_021_024_AL
      Rp_SG_Fusion_Detections_037_040_AL: nonqueued-receiver-com-spec{data-element=Vdp_SG_Fusion_Detections_037_040_AL, init-value=fields=[DET_AZIMUTH_037_Rx:0, DET_AZIMUTH_038_Rx:0, DET_AZIMUTH_039_Rx:0, DET_AZIMUTH_040_Rx:0, DET_AZIMUTH_ERR_037_Rx:0, DET_AZIMUTH_ERR_038_Rx:0, DET_AZIMUTH_ERR_039_Rx:0, DET_AZIMUTH_ERR_040_Rx:0, DET_BELOW_RAIN_THOLD_037_Rx:0, DET_BELOW_RAIN_THOLD_038_Rx:0, DET_BELOW_RAIN_THOLD_039_Rx:0, DET_BELOW_RAIN_THOLD_040_Rx:0, DET_BI_STATIC_FLAG_037_Rx:0, DET_BI_STATIC_FLAG_038_Rx:0, DET_BI_STATIC_FLAG_039_Rx:0, DET_BI_STATIC_FLAG_040_Rx:0, DET_CONFD_AZIMUTH_037_Rx:0, DET_CONFD_AZIMUTH_038_Rx:0, DET_CONFD_AZIMUTH_039_Rx:0, DET_CONFD_AZIMUTH_040_Rx:0, DET_CONFD_ELEVATION_037_Rx:0, DET_CONFD_ELEVATION_038_Rx:0, DET_CONFD_ELEVATION_039_Rx:0, DET_CONFD_ELEVATION_040_Rx:0, DET_ELEVATION_037_Rx:0, DET_ELEVATION_038_Rx:0, DET_ELEVATION_039_Rx:0, DET_ELEVATION_040_Rx:0, DET_ELEVATION_ERR_037_Rx:0, DET_ELEVATION_ERR_038_Rx:0, DET_ELEVATION_ERR_039_Rx:0, DET_ELEVATION_ERR_040_Rx:0, DET_EXISTENCE_PROB_037_Rx:0, DET_EXISTENCE_PROB_038_Rx:0, DET_EXISTENCE_PROB_039_Rx:0, DET_EXISTENCE_PROB_040_Rx:0, DET_HVC_FLAG_037_Rx:0, DET_HVC_FLAG_038_Rx:0, DET_HVC_FLAG_039_Rx:0, DET_HVC_FLAG_040_Rx:0, DET_IDM_037_Rx:0, DET_IDM_038_Rx:0, DET_IDM_039_Rx:0, DET_IDM_040_Rx:0, DET_MH_CRC16_037_040_Rx:0, DET_MH_CYCLE_COUNTER_037_040_Rx:0, DET_MH_SCAN_INDEX_4LSB_037_040_Rx:0, DET_MTD_037_Rx:0, DET_MTD_038_Rx:0, DET_MTD_039_Rx:0, DET_MTD_040_Rx:0, DET_PROB_1STAZHYPO_037_Rx:0, DET_PROB_1STAZHYPO_038_Rx:0, DET_PROB_1STAZHYPO_039_Rx:0, DET_PROB_1STAZHYPO_040_Rx:0, DET_RANGE_037_Rx:0, DET_RANGE_038_Rx:0, DET_RANGE_039_Rx:0, DET_RANGE_040_Rx:0, DET_RANGE_ERR_037_Rx:0, DET_RANGE_ERR_038_Rx:0, DET_RANGE_ERR_039_Rx:0, DET_RANGE_ERR_040_Rx:0, DET_RANGE_VELOCITY_037_Rx:0, DET_RANGE_VELOCITY_038_Rx:0, DET_RANGE_VELOCITY_039_Rx:0, DET_RANGE_VELOCITY_040_Rx:0, DET_RANGE_VELOCITY_ERR_037_Rx:0, DET_RANGE_VELOCITY_ERR_038_Rx:0, DET_RANGE_VELOCITY_ERR_039_Rx:0, DET_RANGE_VELOCITY_ERR_040_Rx:0, DET_RCS_037_Rx:0, DET_RCS_038_Rx:0, DET_RCS_039_Rx:0, DET_RCS_040_Rx:0, DET_SNR_037_Rx:0, DET_SNR_038_Rx:0, DET_SNR_039_Rx:0, DET_SNR_040_Rx:0, DET_SUPER_RES_TARGET_037_Rx:0, DET_SUPER_RES_TARGET_038_Rx:0, DET_SUPER_RES_TARGET_039_Rx:0, DET_SUPER_RES_TARGET_040_Rx:0]}, required-interface=Pi_SG_Fusion_Detections_037_040_AL
      Rp_SG_Fusion_Detections_001_004_AL: nonqueued-receiver-com-spec{data-element=Vdp_SG_Fusion_Detections_001_004_AL, init-value=fields=[DET_AZIMUTH_001_Rx:0, DET_AZIMUTH_002_Rx:0, DET_AZIMUTH_003_Rx:0, DET_AZIMUTH_004_Rx:0, DET_AZIMUTH_ERR_001_Rx:0, DET_AZIMUTH_ERR_002_Rx:0, DET_AZIMUTH_ERR_003_Rx:0, DET_AZIMUTH_ERR_004_Rx:0, DET_BELOW_RAIN_THOLD_001_Rx:0, DET_BELOW_RAIN_THOLD_002_Rx:0, DET_BELOW_RAIN_THOLD_003_Rx:0, DET_BELOW_RAIN_THOLD_004_Rx:0, DET_BI_STATIC_FLAG_001_Rx:0, DET_BI_STATIC_FLAG_002_Rx:0, DET_BI_STATIC_FLAG_003_Rx:0, DET_BI_STATIC_FLAG_004_Rx:0, DET_CONFD_AZIMUTH_001_Rx:0, DET_CONFD_AZIMUTH_002_Rx:0, DET_CONFD_AZIMUTH_003_Rx:0, DET_CONFD_AZIMUTH_004_Rx:0, DET_CONFD_ELEVATION_001_Rx:0, DET_CONFD_ELEVATION_002_Rx:0, DET_CONFD_ELEVATION_003_Rx:0, DET_CONFD_ELEVATION_004_Rx:0, DET_ELEVATION_001_Rx:0, DET_ELEVATION_002_Rx:0, DET_ELEVATION_003_Rx:0, DET_ELEVATION_004_Rx:0, DET_ELEVATION_ERR_001_Rx:0, DET_ELEVATION_ERR_002_Rx:0, DET_ELEVATION_ERR_003_Rx:0, DET_ELEVATION_ERR_004_Rx:0, DET_EXISTENCE_PROB_001_Rx:0, DET_EXISTENCE_PROB_002_Rx:0, DET_EXISTENCE_PROB_003_Rx:0, DET_EXISTENCE_PROB_004_Rx:0, DET_HVC_FLAG_001_Rx:0, DET_HVC_FLAG_002_Rx:0, DET_HVC_FLAG_003_Rx:0, DET_HVC_FLAG_004_Rx:0, DET_IDM_001_Rx:0, DET_IDM_002_Rx:0, DET_IDM_003_Rx:0, DET_IDM_004_Rx:0, DET_MH_CRC16_001_004_Rx:0, DET_MH_CYCLE_COUNTER_001_004_Rx:0, DET_MH_SCAN_INDEX_4LSB_001_004_Rx:0, DET_MTD_001_Rx:0, DET_MTD_002_Rx:0, DET_MTD_003_Rx:0, DET_MTD_004_Rx:0, DET_PROB_1STAZHYPO_001_Rx:0, DET_PROB_1STAZHYPO_002_Rx:0, DET_PROB_1STAZHYPO_003_Rx:0, DET_PROB_1STAZHYPO_004_Rx:0, DET_RANGE_001_Rx:0, DET_RANGE_002_Rx:0, DET_RANGE_003_Rx:0, DET_RANGE_004_Rx:0, DET_RANGE_ERR_001_Rx:0, DET_RANGE_ERR_002_Rx:0, DET_RANGE_ERR_003_Rx:0, DET_RANGE_ERR_004_Rx:0, DET_RANGE_VELOCITY_001_Rx:0, DET_RANGE_VELOCITY_002_Rx:0, DET_RANGE_VELOCITY_003_Rx:0, DET_RANGE_VELOCITY_004_Rx:0, DET_RANGE_VELOCITY_ERR_001_Rx:0, DET_RANGE_VELOCITY_ERR_002_Rx:0, DET_RANGE_VELOCITY_ERR_003_Rx:0, DET_RANGE_VELOCITY_ERR_004_Rx:0, DET_RCS_001_Rx:0, DET_RCS_002_Rx:0, DET_RCS_003_Rx:0, DET_RCS_004_Rx:0, DET_SNR_001_Rx:0, DET_SNR_002_Rx:0, DET_SNR_003_Rx:0, DET_SNR_004_Rx:0, DET_SUPER_RES_TARGET_001_Rx:0, DET_SUPER_RES_TARGET_002_Rx:0, DET_SUPER_RES_TARGET_003_Rx:0, DET_SUPER_RES_TARGET_004_Rx:0]}, required-interface=Pi_SG_Fusion_Detections_001_004_AL
      Rp_SG_Fusion_Detections_029_032_AL: nonqueued-receiver-com-spec{data-element=Vdp_SG_Fusion_Detections_029_032_AL, init-value=fields=[DET_AZIMUTH_029_Rx:0, DET_AZIMUTH_030_Rx:0, DET_AZIMUTH_031_Rx:0, DET_AZIMUTH_032_Rx:0, DET_AZIMUTH_ERR_029_Rx:0, DET_AZIMUTH_ERR_030_Rx:0, DET_AZIMUTH_ERR_031_Rx:0, DET_AZIMUTH_ERR_032_Rx:0, DET_BELOW_RAIN_THOLD_029_Rx:0, DET_BELOW_RAIN_THOLD_030_Rx:0, DET_BELOW_RAIN_THOLD_031_Rx:0, DET_BELOW_RAIN_THOLD_032_Rx:0, DET_BI_STATIC_FLAG_029_Rx:0, DET_BI_STATIC_FLAG_030_Rx:0, DET_BI_STATIC_FLAG_031_Rx:0, DET_BI_STATIC_FLAG_032_Rx:0, DET_CONFD_AZIMUTH_029_Rx:0, DET_CONFD_AZIMUTH_030_Rx:0, DET_CONFD_AZIMUTH_031_Rx:0, DET_CONFD_AZIMUTH_032_Rx:0, DET_CONFD_ELEVATION_029_Rx:0, DET_CONFD_ELEVATION_030_Rx:0, DET_CONFD_ELEVATION_031_Rx:0, DET_CONFD_ELEVATION_032_Rx:0, DET_ELEVATION_029_Rx:0, DET_ELEVATION_030_Rx:0, DET_ELEVATION_031_Rx:0, DET_ELEVATION_032_Rx:0, DET_ELEVATION_ERR_029_Rx:0, DET_ELEVATION_ERR_030_Rx:0, DET_ELEVATION_ERR_031_Rx:0, DET_ELEVATION_ERR_032_Rx:0, DET_EXISTENCE_PROB_029_Rx:0, DET_EXISTENCE_PROB_030_Rx:0, DET_EXISTENCE_PROB_031_Rx:0, DET_EXISTENCE_PROB_032_Rx:0, DET_HVC_FLAG_029_Rx:0, DET_HVC_FLAG_030_Rx:0, DET_HVC_FLAG_031_Rx:0, DET_HVC_FLAG_032_Rx:0, DET_IDM_029_Rx:0, DET_IDM_030_Rx:0, DET_IDM_031_Rx:0, DET_IDM_032_Rx:0, DET_MH_CRC16_029_032_Rx:0, DET_MH_CYCLE_COUNTER_029_032_Rx:0, DET_MH_SCAN_INDEX_4LSB_029_032_Rx:0, DET_MTD_029_Rx:0, DET_MTD_030_Rx:0, DET_MTD_031_Rx:0, DET_MTD_032_Rx:0, DET_PROB_1STAZHYPO_029_Rx:0, DET_PROB_1STAZHYPO_030_Rx:0, DET_PROB_1STAZHYPO_031_Rx:0, DET_PROB_1STAZHYPO_032_Rx:0, DET_RANGE_029_Rx:0, DET_RANGE_030_Rx:0, DET_RANGE_031_Rx:0, DET_RANGE_032_Rx:0, DET_RANGE_ERR_029_Rx:0, DET_RANGE_ERR_030_Rx:0, DET_RANGE_ERR_031_Rx:0, DET_RANGE_ERR_032_Rx:0, DET_RANGE_VELOCITY_029_Rx:0, DET_RANGE_VELOCITY_030_Rx:0, DET_RANGE_VELOCITY_031_Rx:0, DET_RANGE_VELOCITY_032_Rx:0, DET_RANGE_VELOCITY_ERR_029_Rx:0, DET_RANGE_VELOCITY_ERR_030_Rx:0, DET_RANGE_VELOCITY_ERR_031_Rx:0, DET_RANGE_VELOCITY_ERR_032_Rx:0, DET_RCS_029_Rx:0, DET_RCS_030_Rx:0, DET_RCS_031_Rx:0, DET_RCS_032_Rx:0, DET_SNR_029_Rx:0, DET_SNR_030_Rx:0, DET_SNR_031_Rx:0, DET_SNR_032_Rx:0, DET_SUPER_RES_TARGET_029_Rx:0, DET_SUPER_RES_TARGET_030_Rx:0, DET_SUPER_RES_TARGET_031_Rx:0, DET_SUPER_RES_TARGET_032_Rx:0]}, required-interface=Pi_SG_Fusion_Detections_029_032_AL
      Rp_SG_Fusion_Detections_025_028_AL: nonqueued-receiver-com-spec{data-element=Vdp_SG_Fusion_Detections_025_028_AL, init-value=fields=[DET_AZIMUTH_025_Rx:0, DET_AZIMUTH_026_Rx:0, DET_AZIMUTH_027_Rx:0, DET_AZIMUTH_028_Rx:0, DET_AZIMUTH_ERR_025_Rx:0, DET_AZIMUTH_ERR_026_Rx:0, DET_AZIMUTH_ERR_027_Rx:0, DET_AZIMUTH_ERR_028_Rx:0, DET_BELOW_RAIN_THOLD_025_Rx:0, DET_BELOW_RAIN_THOLD_026_Rx:0, DET_BELOW_RAIN_THOLD_027_Rx:0, DET_BELOW_RAIN_THOLD_028_Rx:0, DET_BI_STATIC_FLAG_025_Rx:0, DET_BI_STATIC_FLAG_026_Rx:0, DET_BI_STATIC_FLAG_027_Rx:0, DET_BI_STATIC_FLAG_028_Rx:0, DET_CONFD_AZIMUTH_025_Rx:0, DET_CONFD_AZIMUTH_026_Rx:0, DET_CONFD_AZIMUTH_027_Rx:0, DET_CONFD_AZIMUTH_028_Rx:0, DET_CONFD_ELEVATION_025_Rx:0, DET_CONFD_ELEVATION_026_Rx:0, DET_CONFD_ELEVATION_027_Rx:0, DET_CONFD_ELEVATION_028_Rx:0, DET_ELEVATION_025_Rx:0, DET_ELEVATION_026_Rx:0, DET_ELEVATION_027_Rx:0, DET_ELEVATION_028_Rx:0, DET_ELEVATION_ERR_025_Rx:0, DET_ELEVATION_ERR_026_Rx:0, DET_ELEVATION_ERR_027_Rx:0, DET_ELEVATION_ERR_028_Rx:0, DET_EXISTENCE_PROB_025_Rx:0, DET_EXISTENCE_PROB_026_Rx:0, DET_EXISTENCE_PROB_027_Rx:0, DET_EXISTENCE_PROB_028_Rx:0, DET_HVC_FLAG_025_Rx:0, DET_HVC_FLAG_026_Rx:0, DET_HVC_FLAG_027_Rx:0, DET_HVC_FLAG_028_Rx:0, DET_IDM_025_Rx:0, DET_IDM_026_Rx:0, DET_IDM_027_Rx:0, DET_IDM_028_Rx:0, DET_MH_CRC16_025_028_Rx:0, DET_MH_CYCLE_COUNTER_025_028_Rx:0, DET_MH_SCAN_INDEX_4LSB_025_028_Rx:0, DET_MTD_025_Rx:0, DET_MTD_026_Rx:0, DET_MTD_027_Rx:0, DET_MTD_028_Rx:0, DET_PROB_1STAZHYPO_025_Rx:0, DET_PROB_1STAZHYPO_026_Rx:0, DET_PROB_1STAZHYPO_027_Rx:0, DET_PROB_1STAZHYPO_028_Rx:0, DET_RANGE_025_Rx:0, DET_RANGE_026_Rx:0, DET_RANGE_027_Rx:0, DET_RANGE_028_Rx:0, DET_RANGE_ERR_025_Rx:0, DET_RANGE_ERR_026_Rx:0, DET_RANGE_ERR_027_Rx:0, DET_RANGE_ERR_028_Rx:0, DET_RANGE_VELOCITY_025_Rx:0, DET_RANGE_VELOCITY_026_Rx:0, DET_RANGE_VELOCITY_027_Rx:0, DET_RANGE_VELOCITY_028_Rx:0, DET_RANGE_VELOCITY_ERR_025_Rx:0, DET_RANGE_VELOCITY_ERR_026_Rx:0, DET_RANGE_VELOCITY_ERR_027_Rx:0, DET_RANGE_VELOCITY_ERR_028_Rx:0, DET_RCS_025_Rx:0, DET_RCS_026_Rx:0, DET_RCS_027_Rx:0, DET_RCS_028_Rx:0, DET_SNR_025_Rx:0, DET_SNR_026_Rx:0, DET_SNR_027_Rx:0, DET_SNR_028_Rx:0, DET_SUPER_RES_TARGET_025_Rx:0, DET_SUPER_RES_TARGET_026_Rx:0, DET_SUPER_RES_TARGET_027_Rx:0, DET_SUPER_RES_TARGET_028_Rx:0]}, required-interface=Pi_SG_Fusion_Detections_025_028_AL
      Rp_SG_Fusion_Detections_117_120_AL: nonqueued-receiver-com-spec{data-element=Vdp_SG_Fusion_Detections_117_120_AL, init-value=fields=[DET_AZIMUTH_117_Rx:0, DET_AZIMUTH_118_Rx:0, DET_AZIMUTH_119_Rx:0, DET_AZIMUTH_120_Rx:0, DET_AZIMUTH_ERR_117_Rx:0, DET_AZIMUTH_ERR_118_Rx:0, DET_AZIMUTH_ERR_119_Rx:0, DET_AZIMUTH_ERR_120_Rx:0, DET_BELOW_RAIN_THOLD_117_Rx:0, DET_BELOW_RAIN_THOLD_118_Rx:0, DET_BELOW_RAIN_THOLD_119_Rx:0, DET_BELOW_RAIN_THOLD_120_Rx:0, DET_BI_STATIC_FLAG_117_Rx:0, DET_BI_STATIC_FLAG_118_Rx:0, DET_BI_STATIC_FLAG_119_Rx:0, DET_BI_STATIC_FLAG_120_Rx:0, DET_CONFD_AZIMUTH_117_Rx:0, DET_CONFD_AZIMUTH_118_Rx:0, DET_CONFD_AZIMUTH_119_Rx:0, DET_CONFD_AZIMUTH_120_Rx:0, DET_CONFD_ELEVATION_117_Rx:0, DET_CONFD_ELEVATION_118_Rx:0, DET_CONFD_ELEVATION_119_Rx:0, DET_CONFD_ELEVATION_120_Rx:0, DET_ELEVATION_117_Rx:0, DET_ELEVATION_118_Rx:0, DET_ELEVATION_119_Rx:0, DET_ELEVATION_120_Rx:0, DET_ELEVATION_ERR_117_Rx:0, DET_ELEVATION_ERR_118_Rx:0, DET_ELEVATION_ERR_119_Rx:0, DET_ELEVATION_ERR_120_Rx:0, DET_EXISTENCE_PROB_117_Rx:0, DET_EXISTENCE_PROB_118_Rx:0, DET_EXISTENCE_PROB_119_Rx:0, DET_EXISTENCE_PROB_120_Rx:0, DET_HVC_FLAG_117_Rx:0, DET_HVC_FLAG_118_Rx:0, DET_HVC_FLAG_119_Rx:0, DET_HVC_FLAG_120_Rx:0, DET_IDM_117_Rx:0, DET_IDM_118_Rx:0, DET_IDM_119_Rx:0, DET_IDM_120_Rx:0, DET_MH_CRC16_117_120_Rx:0, DET_MH_CYCLE_COUNTER_117_120_Rx:0, DET_MH_SCAN_INDEX_4LSB_117_120_Rx:0, DET_MTD_117_Rx:0, DET_MTD_118_Rx:0, DET_MTD_119_Rx:0, DET_MTD_120_Rx:0, DET_PROB_1STAZHYPO_117_Rx:0, DET_PROB_1STAZHYPO_118_Rx:0, DET_PROB_1STAZHYPO_119_Rx:0, DET_PROB_1STAZHYPO_120_Rx:0, DET_RANGE_117_Rx:0, DET_RANGE_118_Rx:0, DET_RANGE_119_Rx:0, DET_RANGE_120_Rx:0, DET_RANGE_ERR_117_Rx:0, DET_RANGE_ERR_118_Rx:0, DET_RANGE_ERR_119_Rx:0, DET_RANGE_ERR_120_Rx:0, DET_RANGE_VELOCITY_117_Rx:0, DET_RANGE_VELOCITY_118_Rx:0, DET_RANGE_VELOCITY_119_Rx:0, DET_RANGE_VELOCITY_120_Rx:0, DET_RANGE_VELOCITY_ERR_117_Rx:0, DET_RANGE_VELOCITY_ERR_118_Rx:0, DET_RANGE_VELOCITY_ERR_119_Rx:0, DET_RANGE_VELOCITY_ERR_120_Rx:0, DET_RCS_117_Rx:0, DET_RCS_118_Rx:0, DET_RCS_119_Rx:0, DET_RCS_120_Rx:0, DET_SNR_117_Rx:0, DET_SNR_118_Rx:0, DET_SNR_119_Rx:0, DET_SNR_120_Rx:0, DET_SUPER_RES_TARGET_117_Rx:0, DET_SUPER_RES_TARGET_118_Rx:0, DET_SUPER_RES_TARGET_119_Rx:0, DET_SUPER_RES_TARGET_120_Rx:0]}, required-interface=Pi_SG_Fusion_Detections_117_120_AL
      Rp_SG_Fusion_Detections_081_084_AL: nonqueued-receiver-com-spec{data-element=Vdp_SG_Fusion_Detections_081_084_AL, init-value=fields=[DET_AZIMUTH_081_Rx:0, DET_AZIMUTH_082_Rx:0, DET_AZIMUTH_083_Rx:0, DET_AZIMUTH_084_Rx:0, DET_AZIMUTH_ERR_081_Rx:0, DET_AZIMUTH_ERR_082_Rx:0, DET_AZIMUTH_ERR_083_Rx:0, DET_AZIMUTH_ERR_084_Rx:0, DET_BELOW_RAIN_THOLD_081_Rx:0, DET_BELOW_RAIN_THOLD_082_Rx:0, DET_BELOW_RAIN_THOLD_083_Rx:0, DET_BELOW_RAIN_THOLD_084_Rx:0, DET_BI_STATIC_FLAG_081_Rx:0, DET_BI_STATIC_FLAG_082_Rx:0, DET_BI_STATIC_FLAG_083_Rx:0, DET_BI_STATIC_FLAG_084_Rx:0, DET_CONFD_AZIMUTH_081_Rx:0, DET_CONFD_AZIMUTH_082_Rx:0, DET_CONFD_AZIMUTH_083_Rx:0, DET_CONFD_AZIMUTH_084_Rx:0, DET_CONFD_ELEVATION_081_Rx:0, DET_CONFD_ELEVATION_082_Rx:0, DET_CONFD_ELEVATION_083_Rx:0, DET_CONFD_ELEVATION_084_Rx:0, DET_ELEVATION_081_Rx:0, DET_ELEVATION_082_Rx:0, DET_ELEVATION_083_Rx:0, DET_ELEVATION_084_Rx:0, DET_ELEVATION_ERR_081_Rx:0, DET_ELEVATION_ERR_082_Rx:0, DET_ELEVATION_ERR_083_Rx:0, DET_ELEVATION_ERR_084_Rx:0, DET_EXISTENCE_PROB_081_Rx:0, DET_EXISTENCE_PROB_082_Rx:0, DET_EXISTENCE_PROB_083_Rx:0, DET_EXISTENCE_PROB_084_Rx:0, DET_HVC_FLAG_081_Rx:0, DET_HVC_FLAG_082_Rx:0, DET_HVC_FLAG_083_Rx:0, DET_HVC_FLAG_084_Rx:0, DET_IDM_081_Rx:0, DET_IDM_082_Rx:0, DET_IDM_083_Rx:0, DET_IDM_084_Rx:0, DET_MH_CRC16_081_084_Rx:0, DET_MH_CYCLE_COUNTER_081_084_Rx:0, DET_MH_SCAN_INDEX_4LSB_081_084_Rx:0, DET_MTD_081_Rx:0, DET_MTD_082_Rx:0, DET_MTD_083_Rx:0, DET_MTD_084_Rx:0, DET_PROB_1STAZHYPO_081_Rx:0, DET_PROB_1STAZHYPO_082_Rx:0, DET_PROB_1STAZHYPO_083_Rx:0, DET_PROB_1STAZHYPO_084_Rx:0, DET_RANGE_081_Rx:0, DET_RANGE_082_Rx:0, DET_RANGE_083_Rx:0, DET_RANGE_084_Rx:0, DET_RANGE_ERR_081_Rx:0, DET_RANGE_ERR_082_Rx:0, DET_RANGE_ERR_083_Rx:0, DET_RANGE_ERR_084_Rx:0, DET_RANGE_VELOCITY_081_Rx:0, DET_RANGE_VELOCITY_082_Rx:0, DET_RANGE_VELOCITY_083_Rx:0, DET_RANGE_VELOCITY_084_Rx:0, DET_RANGE_VELOCITY_ERR_081_Rx:0, DET_RANGE_VELOCITY_ERR_082_Rx:0, DET_RANGE_VELOCITY_ERR_083_Rx:0, DET_RANGE_VELOCITY_ERR_084_Rx:0, DET_RCS_081_Rx:0, DET_RCS_082_Rx:0, DET_RCS_083_Rx:0, DET_RCS_084_Rx:0, DET_SNR_081_Rx:0, DET_SNR_082_Rx:0, DET_SNR_083_Rx:0, DET_SNR_084_Rx:0, DET_SUPER_RES_TARGET_081_Rx:0, DET_SUPER_RES_TARGET_082_Rx:0, DET_SUPER_RES_TARGET_083_Rx:0, DET_SUPER_RES_TARGET_084_Rx:0]}, required-interface=Pi_SG_Fusion_Detections_081_084_AL
      Rp_SG_Fusion_Detections_053_056_AL: nonqueued-receiver-com-spec{data-element=Vdp_SG_Fusion_Detections_053_056_AL, init-value=fields=[DET_AZIMUTH_053_Rx:0, DET_AZIMUTH_054_Rx:0, DET_AZIMUTH_055_Rx:0, DET_AZIMUTH_056_Rx:0, DET_AZIMUTH_ERR_053_Rx:0, DET_AZIMUTH_ERR_054_Rx:0, DET_AZIMUTH_ERR_055_Rx:0, DET_AZIMUTH_ERR_056_Rx:0, DET_BELOW_RAIN_THOLD_053_Rx:0, DET_BELOW_RAIN_THOLD_054_Rx:0, DET_BELOW_RAIN_THOLD_055_Rx:0, DET_BELOW_RAIN_THOLD_056_Rx:0, DET_BI_STATIC_FLAG_053_Rx:0, DET_BI_STATIC_FLAG_054_Rx:0, DET_BI_STATIC_FLAG_055_Rx:0, DET_BI_STATIC_FLAG_056_Rx:0, DET_CONFD_AZIMUTH_053_Rx:0, DET_CONFD_AZIMUTH_054_Rx:0, DET_CONFD_AZIMUTH_055_Rx:0, DET_CONFD_AZIMUTH_056_Rx:0, DET_CONFD_ELEVATION_053_Rx:0, DET_CONFD_ELEVATION_054_Rx:0, DET_CONFD_ELEVATION_055_Rx:0, DET_CONFD_ELEVATION_056_Rx:0, DET_ELEVATION_053_Rx:0, DET_ELEVATION_054_Rx:0, DET_ELEVATION_055_Rx:0, DET_ELEVATION_056_Rx:0, DET_ELEVATION_ERR_053_Rx:0, DET_ELEVATION_ERR_054_Rx:0, DET_ELEVATION_ERR_055_Rx:0, DET_ELEVATION_ERR_056_Rx:0, DET_EXISTENCE_PROB_053_Rx:0, DET_EXISTENCE_PROB_054_Rx:0, DET_EXISTENCE_PROB_055_Rx:0, DET_EXISTENCE_PROB_056_Rx:0, DET_HVC_FLAG_053_Rx:0, DET_HVC_FLAG_054_Rx:0, DET_HVC_FLAG_055_Rx:0, DET_HVC_FLAG_056_Rx:0, DET_IDM_053_Rx:0, DET_IDM_054_Rx:0, DET_IDM_055_Rx:0, DET_IDM_056_Rx:0, DET_MH_CRC16_053_056_Rx:0, DET_MH_CYCLE_COUNTER_053_056_Rx:0, DET_MH_SCAN_INDEX_4LSB_053_056_Rx:0, DET_MTD_053_Rx:0, DET_MTD_054_Rx:0, DET_MTD_055_Rx:0, DET_MTD_056_Rx:0, DET_PROB_1STAZHYPO_053_Rx:0, DET_PROB_1STAZHYPO_054_Rx:0, DET_PROB_1STAZHYPO_055_Rx:0, DET_PROB_1STAZHYPO_056_Rx:0, DET_RANGE_053_Rx:0, DET_RANGE_054_Rx:0, DET_RANGE_055_Rx:0, DET_RANGE_056_Rx:0, DET_RANGE_ERR_053_Rx:0, DET_RANGE_ERR_054_Rx:0, DET_RANGE_ERR_055_Rx:0, DET_RANGE_ERR_056_Rx:0, DET_RANGE_VELOCITY_053_Rx:0, DET_RANGE_VELOCITY_054_Rx:0, DET_RANGE_VELOCITY_055_Rx:0, DET_RANGE_VELOCITY_056_Rx:0, DET_RANGE_VELOCITY_ERR_053_Rx:0, DET_RANGE_VELOCITY_ERR_054_Rx:0, DET_RANGE_VELOCITY_ERR_055_Rx:0, DET_RANGE_VELOCITY_ERR_056_Rx:0, DET_RCS_053_Rx:0, DET_RCS_054_Rx:0, DET_RCS_055_Rx:0, DET_RCS_056_Rx:0, DET_SNR_053_Rx:0, DET_SNR_054_Rx:0, DET_SNR_055_Rx:0, DET_SNR_056_Rx:0, DET_SUPER_RES_TARGET_053_Rx:0, DET_SUPER_RES_TARGET_054_Rx:0, DET_SUPER_RES_TARGET_055_Rx:0, DET_SUPER_RES_TARGET_056_Rx:0]}, required-interface=Pi_SG_Fusion_Detections_053_056_AL
      Rp_SG_Fusion_Detections_097_100_AL: nonqueued-receiver-com-spec{data-element=Vdp_SG_Fusion_Detections_097_100_AL, init-value=fields=[DET_AZIMUTH_097_Rx:0, DET_AZIMUTH_098_Rx:0, DET_AZIMUTH_099_Rx:0, DET_AZIMUTH_100_Rx:0, DET_AZIMUTH_ERR_097_Rx:0, DET_AZIMUTH_ERR_098_Rx:0, DET_AZIMUTH_ERR_099_Rx:0, DET_AZIMUTH_ERR_100_Rx:0, DET_BELOW_RAIN_THOLD_097_Rx:0, DET_BELOW_RAIN_THOLD_098_Rx:0, DET_BELOW_RAIN_THOLD_099_Rx:0, DET_BELOW_RAIN_THOLD_100_Rx:0, DET_BI_STATIC_FLAG_097_Rx:0, DET_BI_STATIC_FLAG_098_Rx:0, DET_BI_STATIC_FLAG_099_Rx:0, DET_BI_STATIC_FLAG_100_Rx:0, DET_CONFD_AZIMUTH_097_Rx:0, DET_CONFD_AZIMUTH_098_Rx:0, DET_CONFD_AZIMUTH_099_Rx:0, DET_CONFD_AZIMUTH_100_Rx:0, DET_CONFD_ELEVATION_097_Rx:0, DET_CONFD_ELEVATION_098_Rx:0, DET_CONFD_ELEVATION_099_Rx:0, DET_CONFD_ELEVATION_100_Rx:0, DET_ELEVATION_097_Rx:0, DET_ELEVATION_098_Rx:0, DET_ELEVATION_099_Rx:0, DET_ELEVATION_100_Rx:0, DET_ELEVATION_ERR_097_Rx:0, DET_ELEVATION_ERR_098_Rx:0, DET_ELEVATION_ERR_099_Rx:0, DET_ELEVATION_ERR_100_Rx:0, DET_EXISTENCE_PROB_097_Rx:0, DET_EXISTENCE_PROB_098_Rx:0, DET_EXISTENCE_PROB_099_Rx:0, DET_EXISTENCE_PROB_100_Rx:0, DET_HVC_FLAG_097_Rx:0, DET_HVC_FLAG_098_Rx:0, DET_HVC_FLAG_099_Rx:0, DET_HVC_FLAG_100_Rx:0, DET_IDM_097_Rx:0, DET_IDM_098_Rx:0, DET_IDM_099_Rx:0, DET_IDM_100_Rx:0, DET_MH_CRC16_097_100_Rx:0, DET_MH_CYCLE_COUNTER_097_100_Rx:0, DET_MH_SCAN_INDEX_4LSB_097_100_Rx:0, DET_MTD_097_Rx:0, DET_MTD_098_Rx:0, DET_MTD_099_Rx:0, DET_MTD_100_Rx:0, DET_PROB_1STAZHYPO_097_Rx:0, DET_PROB_1STAZHYPO_098_Rx:0, DET_PROB_1STAZHYPO_099_Rx:0, DET_PROB_1STAZHYPO_100_Rx:0, DET_RANGE_097_Rx:0, DET_RANGE_098_Rx:0, DET_RANGE_099_Rx:0, DET_RANGE_100_Rx:0, DET_RANGE_ERR_097_Rx:0, DET_RANGE_ERR_098_Rx:0, DET_RANGE_ERR_099_Rx:0, DET_RANGE_ERR_100_Rx:0, DET_RANGE_VELOCITY_097_Rx:0, DET_RANGE_VELOCITY_098_Rx:0, DET_RANGE_VELOCITY_099_Rx:0, DET_RANGE_VELOCITY_100_Rx:0, DET_RANGE_VELOCITY_ERR_097_Rx:0, DET_RANGE_VELOCITY_ERR_098_Rx:0, DET_RANGE_VELOCITY_ERR_099_Rx:0, DET_RANGE_VELOCITY_ERR_100_Rx:0, DET_RCS_097_Rx:0, DET_RCS_098_Rx:0, DET_RCS_099_Rx:0, DET_RCS_100_Rx:0, DET_SNR_097_Rx:0, DET_SNR_098_Rx:0, DET_SNR_099_Rx:0, DET_SNR_100_Rx:0, DET_SUPER_RES_TARGET_097_Rx:0, DET_SUPER_RES_TARGET_098_Rx:0, DET_SUPER_RES_TARGET_099_Rx:0, DET_SUPER_RES_TARGET_100_Rx:0]}, required-interface=Pi_SG_Fusion_Detections_097_100_AL
      Rp_SG_Fusion_Detections_045_048_AL: nonqueued-receiver-com-spec{data-element=Vdp_SG_Fusion_Detections_045_048_AL, init-value=fields=[DET_AZIMUTH_045_Rx:0, DET_AZIMUTH_046_Rx:0, DET_AZIMUTH_047_Rx:0, DET_AZIMUTH_048_Rx:0, DET_AZIMUTH_ERR_045_Rx:0, DET_AZIMUTH_ERR_046_Rx:0, DET_AZIMUTH_ERR_047_Rx:0, DET_AZIMUTH_ERR_048_Rx:0, DET_BELOW_RAIN_THOLD_045_Rx:0, DET_BELOW_RAIN_THOLD_046_Rx:0, DET_BELOW_RAIN_THOLD_047_Rx:0, DET_BELOW_RAIN_THOLD_048_Rx:0, DET_BI_STATIC_FLAG_045_Rx:0, DET_BI_STATIC_FLAG_046_Rx:0, DET_BI_STATIC_FLAG_047_Rx:0, DET_BI_STATIC_FLAG_048_Rx:0, DET_CONFD_AZIMUTH_045_Rx:0, DET_CONFD_AZIMUTH_046_Rx:0, DET_CONFD_AZIMUTH_047_Rx:0, DET_CONFD_AZIMUTH_048_Rx:0, DET_CONFD_ELEVATION_045_Rx:0, DET_CONFD_ELEVATION_046_Rx:0, DET_CONFD_ELEVATION_047_Rx:0, DET_CONFD_ELEVATION_048_Rx:0, DET_ELEVATION_045_Rx:0, DET_ELEVATION_046_Rx:0, DET_ELEVATION_047_Rx:0, DET_ELEVATION_048_Rx:0, DET_ELEVATION_ERR_045_Rx:0, DET_ELEVATION_ERR_046_Rx:0, DET_ELEVATION_ERR_047_Rx:0, DET_ELEVATION_ERR_048_Rx:0, DET_EXISTENCE_PROB_045_Rx:0, DET_EXISTENCE_PROB_046_Rx:0, DET_EXISTENCE_PROB_047_Rx:0, DET_EXISTENCE_PROB_048_Rx:0, DET_HVC_FLAG_045_Rx:0, DET_HVC_FLAG_046_Rx:0, DET_HVC_FLAG_047_Rx:0, DET_HVC_FLAG_048_Rx:0, DET_IDM_045_Rx:0, DET_IDM_046_Rx:0, DET_IDM_047_Rx:0, DET_IDM_048_Rx:0, DET_MH_CRC16_045_048_Rx:0, DET_MH_CYCLE_COUNTER_045_048_Rx:0, DET_MH_SCAN_INDEX_4LSB_045_048_Rx:0, DET_MTD_045_Rx:0, DET_MTD_046_Rx:0, DET_MTD_047_Rx:0, DET_MTD_048_Rx:0, DET_PROB_1STAZHYPO_045_Rx:0, DET_PROB_1STAZHYPO_046_Rx:0, DET_PROB_1STAZHYPO_047_Rx:0, DET_PROB_1STAZHYPO_048_Rx:0, DET_RANGE_045_Rx:0, DET_RANGE_046_Rx:0, DET_RANGE_047_Rx:0, DET_RANGE_048_Rx:0, DET_RANGE_ERR_045_Rx:0, DET_RANGE_ERR_046_Rx:0, DET_RANGE_ERR_047_Rx:0, DET_RANGE_ERR_048_Rx:0, DET_RANGE_VELOCITY_045_Rx:0, DET_RANGE_VELOCITY_046_Rx:0, DET_RANGE_VELOCITY_047_Rx:0, DET_RANGE_VELOCITY_048_Rx:0, DET_RANGE_VELOCITY_ERR_045_Rx:0, DET_RANGE_VELOCITY_ERR_046_Rx:0, DET_RANGE_VELOCITY_ERR_047_Rx:0, DET_RANGE_VELOCITY_ERR_048_Rx:0, DET_RCS_045_Rx:0, DET_RCS_046_Rx:0, DET_RCS_047_Rx:0, DET_RCS_048_Rx:0, DET_SNR_045_Rx:0, DET_SNR_046_Rx:0, DET_SNR_047_Rx:0, DET_SNR_048_Rx:0, DET_SUPER_RES_TARGET_045_Rx:0, DET_SUPER_RES_TARGET_046_Rx:0, DET_SUPER_RES_TARGET_047_Rx:0, DET_SUPER_RES_TARGET_048_Rx:0]}, required-interface=Pi_SG_Fusion_Detections_045_048_AL
      Rp_SG_Fusion_Detections_077_080_AL: nonqueued-receiver-com-spec{data-element=Vdp_SG_Fusion_Detections_077_080_AL, init-value=fields=[DET_AZIMUTH_077_Rx:0, DET_AZIMUTH_078_Rx:0, DET_AZIMUTH_079_Rx:0, DET_AZIMUTH_080_Rx:0, DET_AZIMUTH_ERR_077_Rx:0, DET_AZIMUTH_ERR_078_Rx:0, DET_AZIMUTH_ERR_079_Rx:0, DET_AZIMUTH_ERR_080_Rx:0, DET_BELOW_RAIN_THOLD_077_Rx:0, DET_BELOW_RAIN_THOLD_078_Rx:0, DET_BELOW_RAIN_THOLD_079_Rx:0, DET_BELOW_RAIN_THOLD_080_Rx:0, DET_BI_STATIC_FLAG_077_Rx:0, DET_BI_STATIC_FLAG_078_Rx:0, DET_BI_STATIC_FLAG_079_Rx:0, DET_BI_STATIC_FLAG_080_Rx:0, DET_CONFD_AZIMUTH_077_Rx:0, DET_CONFD_AZIMUTH_078_Rx:0, DET_CONFD_AZIMUTH_079_Rx:0, DET_CONFD_AZIMUTH_080_Rx:0, DET_CONFD_ELEVATION_077_Rx:0, DET_CONFD_ELEVATION_078_Rx:0, DET_CONFD_ELEVATION_079_Rx:0, DET_CONFD_ELEVATION_080_Rx:0, DET_ELEVATION_077_Rx:0, DET_ELEVATION_078_Rx:0, DET_ELEVATION_079_Rx:0, DET_ELEVATION_080_Rx:0, DET_ELEVATION_ERR_077_Rx:0, DET_ELEVATION_ERR_078_Rx:0, DET_ELEVATION_ERR_079_Rx:0, DET_ELEVATION_ERR_080_Rx:0, DET_EXISTENCE_PROB_077_Rx:0, DET_EXISTENCE_PROB_078_Rx:0, DET_EXISTENCE_PROB_079_Rx:0, DET_EXISTENCE_PROB_080_Rx:0, DET_HVC_FLAG_077_Rx:0, DET_HVC_FLAG_078_Rx:0, DET_HVC_FLAG_079_Rx:0, DET_HVC_FLAG_080_Rx:0, DET_IDM_077_Rx:0, DET_IDM_078_Rx:0, DET_IDM_079_Rx:0, DET_IDM_080_Rx:0, DET_MH_CRC16_077_080_Rx:0, DET_MH_CYCLE_COUNTER_077_080_Rx:0, DET_MH_SCAN_INDEX_4LSB_077_080_Rx:0, DET_MTD_077_Rx:0, DET_MTD_078_Rx:0, DET_MTD_079_Rx:0, DET_MTD_080_Rx:0, DET_PROB_1STAZHYPO_077_Rx:0, DET_PROB_1STAZHYPO_078_Rx:0, DET_PROB_1STAZHYPO_079_Rx:0, DET_PROB_1STAZHYPO_080_Rx:0, DET_RANGE_077_Rx:0, DET_RANGE_078_Rx:0, DET_RANGE_079_Rx:0, DET_RANGE_080_Rx:0, DET_RANGE_ERR_077_Rx:0, DET_RANGE_ERR_078_Rx:0, DET_RANGE_ERR_079_Rx:0, DET_RANGE_ERR_080_Rx:0, DET_RANGE_VELOCITY_077_Rx:0, DET_RANGE_VELOCITY_078_Rx:0, DET_RANGE_VELOCITY_079_Rx:0, DET_RANGE_VELOCITY_080_Rx:0, DET_RANGE_VELOCITY_ERR_077_Rx:0, DET_RANGE_VELOCITY_ERR_078_Rx:0, DET_RANGE_VELOCITY_ERR_079_Rx:0, DET_RANGE_VELOCITY_ERR_080_Rx:0, DET_RCS_077_Rx:0, DET_RCS_078_Rx:0, DET_RCS_079_Rx:0, DET_RCS_080_Rx:0, DET_SNR_077_Rx:0, DET_SNR_078_Rx:0, DET_SNR_079_Rx:0, DET_SNR_080_Rx:0, DET_SUPER_RES_TARGET_077_Rx:0, DET_SUPER_RES_TARGET_078_Rx:0, DET_SUPER_RES_TARGET_079_Rx:0, DET_SUPER_RES_TARGET_080_Rx:0]}, required-interface=Pi_SG_Fusion_Detections_077_080_AL
      Rp_SG_Fusion_Detections_069_072_AL: nonqueued-receiver-com-spec{data-element=Vdp_SG_Fusion_Detections_069_072_AL, init-value=fields=[DET_AZIMUTH_069_Rx:0, DET_AZIMUTH_070_Rx:0, DET_AZIMUTH_071_Rx:0, DET_AZIMUTH_072_Rx:0, DET_AZIMUTH_ERR_069_Rx:0, DET_AZIMUTH_ERR_070_Rx:0, DET_AZIMUTH_ERR_071_Rx:0, DET_AZIMUTH_ERR_072_Rx:0, DET_BELOW_RAIN_THOLD_069_Rx:0, DET_BELOW_RAIN_THOLD_070_Rx:0, DET_BELOW_RAIN_THOLD_071_Rx:0, DET_BELOW_RAIN_THOLD_072_Rx:0, DET_BI_STATIC_FLAG_069_Rx:0, DET_BI_STATIC_FLAG_070_Rx:0, DET_BI_STATIC_FLAG_071_Rx:0, DET_BI_STATIC_FLAG_072_Rx:0, DET_CONFD_AZIMUTH_069_Rx:0, DET_CONFD_AZIMUTH_070_Rx:0, DET_CONFD_AZIMUTH_071_Rx:0, DET_CONFD_AZIMUTH_072_Rx:0, DET_CONFD_ELEVATION_069_Rx:0, DET_CONFD_ELEVATION_070_Rx:0, DET_CONFD_ELEVATION_071_Rx:0, DET_CONFD_ELEVATION_072_Rx:0, DET_ELEVATION_069_Rx:0, DET_ELEVATION_070_Rx:0, DET_ELEVATION_071_Rx:0, DET_ELEVATION_072_Rx:0, DET_ELEVATION_ERR_069_Rx:0, DET_ELEVATION_ERR_070_Rx:0, DET_ELEVATION_ERR_071_Rx:0, DET_ELEVATION_ERR_072_Rx:0, DET_EXISTENCE_PROB_069_Rx:0, DET_EXISTENCE_PROB_070_Rx:0, DET_EXISTENCE_PROB_071_Rx:0, DET_EXISTENCE_PROB_072_Rx:0, DET_HVC_FLAG_069_Rx:0, DET_HVC_FLAG_070_Rx:0, DET_HVC_FLAG_071_Rx:0, DET_HVC_FLAG_072_Rx:0, DET_IDM_069_Rx:0, DET_IDM_070_Rx:0, DET_IDM_071_Rx:0, DET_IDM_072_Rx:0, DET_MH_CRC16_069_072_Rx:0, DET_MH_CYCLE_COUNTER_069_072_Rx:0, DET_MH_SCAN_INDEX_4LSB_069_072_Rx:0, DET_MTD_069_Rx:0, DET_MTD_070_Rx:0, DET_MTD_071_Rx:0, DET_MTD_072_Rx:0, DET_PROB_1STAZHYPO_069_Rx:0, DET_PROB_1STAZHYPO_070_Rx:0, DET_PROB_1STAZHYPO_071_Rx:0, DET_PROB_1STAZHYPO_072_Rx:0, DET_RANGE_069_Rx:0, DET_RANGE_070_Rx:0, DET_RANGE_071_Rx:0, DET_RANGE_072_Rx:0, DET_RANGE_ERR_069_Rx:0, DET_RANGE_ERR_070_Rx:0, DET_RANGE_ERR_071_Rx:0, DET_RANGE_ERR_072_Rx:0, DET_RANGE_VELOCITY_069_Rx:0, DET_RANGE_VELOCITY_070_Rx:0, DET_RANGE_VELOCITY_071_Rx:0, DET_RANGE_VELOCITY_072_Rx:0, DET_RANGE_VELOCITY_ERR_069_Rx:0, DET_RANGE_VELOCITY_ERR_070_Rx:0, DET_RANGE_VELOCITY_ERR_071_Rx:0, DET_RANGE_VELOCITY_ERR_072_Rx:0, DET_RCS_069_Rx:0, DET_RCS_070_Rx:0, DET_RCS_071_Rx:0, DET_RCS_072_Rx:0, DET_SNR_069_Rx:0, DET_SNR_070_Rx:0, DET_SNR_071_Rx:0, DET_SNR_072_Rx:0, DET_SUPER_RES_TARGET_069_Rx:0, DET_SUPER_RES_TARGET_070_Rx:0, DET_SUPER_RES_TARGET_071_Rx:0, DET_SUPER_RES_TARGET_072_Rx:0]}, required-interface=Pi_SG_Fusion_Detections_069_072_AL
    provide port Pp_SG_RadarCapability_AL: nonqueued-sender-com-spec{data-element=Vdp_SG_RadarCapability_AL, init-value=fields=[CAP_AngleAzimuthRangeEnd:0, CAP_AngleAzimuthRangeStart:0, CAP_BlockageActive:1, CAP_BlockageProbability:0, CAP_BlockageSensitivity:2, CAP_BlockageStatus:3, CAP_BlockageValue:5, CAP_CYCLE_COUNTER:0, CAP_DampingActive:0, CAP_DampingCurrent:25500, CAP_DampingStandardDeviation:0, CAP_DampingStatus:3, CAP_FreeSightCheckActive:1, CAP_FreeSightCheckStatus:255, CAP_MaxDetectionRangeCar_0:0, CAP_MaxDetectionRangeCar_1:0, CAP_MaxDetectionRangeCar_2:0, CAP_MaxDetRangeMotorbike_0:0, CAP_MaxDetRangeMotorbike_1:0, CAP_MaxDetRangeMotorbike_2:0, CAP_MaxDetRangePedestrian_0:0, CAP_MaxDetRangePedestrian_1:0, CAP_MaxDetRangePedestrian_2:0, CAP_MH_CRC16:0, CAP_RangeEstimationActive:1, CAP_RangeEstimationStatus:3, CAP_SideLobeLevelBeamformer:0, CAP_SLBlockageFilterValue:0, CAP_SLBlockageFlag:0, CAP_SLLMonitoringActive:1, CAP_SLLMonitoringStatus:3]}, provided-interface=Pi_SG_RadarCapability_AL
    provide port Pp_SG_RadarStatus2_AL: nonqueued-sender-com-spec{data-element=Vdp_SG_RadarStatus2_AL, init-value=fields=[STS_AF_CORE_THROUGHPUT:0, STS_BRR_STATUS:0, STS_CAN_NM_State:0, STS_CORE_ACTV_FLT_BYTE_0_to_3:0, STS_CORE_ACTV_FLT_BYTE_4_to_7:0, STS_CORE_ACTV_FLT_BYTE_8_to_11:0, STS_CORE_ACTV_FLT_BYTE_11_to_15:0, STS_First_CAN_Det_Inst_Latency:0, STS_Gear_Position:0, STS_INTRFC_VERSION_ID_MAJOR:0, STS_INTRFC_VERSION_ID_MINOR:0, STS_INTRFC_VERSION_ID_PATCH:0, STS_Last_CAN_Det_Inst_Latency:0, STS_MCU_TEMP:0, STS_MH_002_CRC16:0, STS_MH_002_CYCLE_COUNTER:0, 0, STS_MMIC_TEMP_RX:0, STS_MMIC_TEMP_TX0:0, STS_MMIC_TEMP_TX1_2:0, STS_MMIC_TEMP_TX3_4:0, STS_NO_TSYN_ERROR:0, STS_POINT_OF_TRIGGER:0, STS_RAIN_COUNT:0, STS_RDD_CORE_THROUGHPUT:0, STS_SCAN_TYPE:0, STS_STEERING_ANGLE:0, STS_STEERING_ANGLE_SIGN:0, STS_TIME_SYNC_OFFSET:0, STS_TKEY_ACTV_FLT_BYTE_0_to_3:0, STS_TKEY_ACTV_FLT_BYTE_4_to_5:0, STS_VEH_SPEED_DIRECTION:0, STS_VEHICLE_SPEED_CALC:0, STS_Vehicle_Speed_Calc_QF:0, STS_VEHICLE_SUPPLY_VOLTAGE:0, STS_XCVR_OPERATIONAL:0, STS_YAW_RATE_BIAS:0, STS_Yaw_Rate_Calc_QF:0]}, provided-interface=Pi_SG_RadarStatus2_AL
    require port Rp_SG_VehicleStatus_AL: nonqueued-receiver-com-spec{data-element=Vdp_SG_VehicleStatus_AL, init-value=fields=[SSTS_CAN_PCAN_MAJOR_ADAS:0, SSTS_CAN_PCAN_MINOR_ADAS:0, SSTS_DRIVE_DIR:0, SSTS_DRIVE_REVERSE:0, SSTS_GEAR_POSITION:0, SSTS_IGN_STATUS:0, SSTS_MH_VS_CRC16:0, SSTS_MH_VS_CYCLE_COUNTER:0, SSTS_STEERING_ANGLE:0, SSTS_STEERING_ANGLE_SIGN:0, SSTS_SW_VERSION_ADAS:0, SSTS_VEH_AbsoluteTime_Day:0, SSTS_VEH_AbsoluteTime_Hour:0, SSTS_VEH_AbsoluteTime_Minute:0, SSTS_VEH_AbsoluteTime_Month:0, SSTS_VEH_AbsoluteTime_Second:0, SSTS_VEH_AbsoluteTime_Year:0, SSTS_VEH_ODOMETER:0, SSTS_VEH_POWER_MODE_STATUS:0, SSTS_VEH_SPD_COMP_FACTOR:0, SSTS_VEH_Status_CMAC:5 x 0, SSTS_VEH_Status_FV:7 x 0, SSTS_VEH_SYSTEM_VOLTAGE:0, SSTS_VEH_TRAILER_CONNECTED:0, SSTS_VEH_VARIANT:0, SSTS_VEHICLE_SPEED_CALC:0, SSTS_VEHICLE_SPEED_CALC_QF:0, SSTS_VEHICLE_STATE:0, SSTS_VIN_Data_Byte0:0, SSTS_VIN_Data_Byte1:0, SSTS_VIN_Data_Byte2:0, SSTS_VIN_Data_Byte3:0, SSTS_VIN_Data_Byte4:0, SSTS_VIN_Data_Byte5:0, SSTS_VIN_Data_Byte6:0, SSTS_VIN_FrameIdx:0, SSTS_YAW_RATE_BIAS:0, SSTS_YAW_RATE_CALC:0, SSTS_YAW_RATE_CALC_QF:0]}, required-interface=Pi_SG_VehicleStatus_AL
    require port Rp_SG_XcpCTOReq_AL: nonqueued-receiver-com-spec{data-element=Vdp_SG_XcpCTOReq_AL, init-value=fields=[STS_PID:0, STS_XCP_REQ_CTO_Byte1:0, STS_XCP_REQ_CTO_Byte2:0, STS_XCP_REQ_CTO_Byte3:0, STS_XCP_REQ_CTO_Byte4:0, STS_XCP_REQ_CTO_Byte5:0, STS_XCP_REQ_CTO_Byte6:0, STS_XCP_REQ_CTO_Byte7:0, STS_XCP_REQ_CTO_Byte8:0, STS_XCP_REQ_CTO_Byte9:0, STS_XCP_REQ_CTO_Byte10:0, STS_XCP_REQ_CTO_Byte11:0, STS_XCP_REQ_CTO_Byte12:0, STS_XCP_REQ_CTO_Byte13:0, STS_XCP_REQ_CTO_Byte14:0, STS_XCP_REQ_CTO_Byte15:0, STS_XCP_REQ_CTO_Byte16:0, STS_XCP_REQ_CTO_Byte17:0, STS_XCP_REQ_CTO_Byte18:0, STS_XCP_REQ_CTO_Byte19:0, STS_XCP_REQ_CTO_Byte20:0, STS_XCP_REQ_CTO_Byte21:0, STS_XCP_REQ_CTO_Byte22:0, STS_XCP_REQ_CTO_Byte23:0, STS_XCP_REQ_CTO_Byte24:0, STS_XCP_REQ_CTO_Byte25:0, STS_XCP_REQ_CTO_Byte26:0, STS_XCP_REQ_CTO_Byte27:0, STS_XCP_REQ_CTO_Byte28:0, STS_XCP_REQ_CTO_Byte29:0, STS_XCP_REQ_CTO_Byte30:0, STS_XCP_REQ_CTO_Byte31:0, STS_XCP_REQ_CTO_Byte32:0, STS_XCP_REQ_CTO_Byte33:0, STS_XCP_REQ_CTO_Byte34:0, STS_XCP_REQ_CTO_Byte35:0, STS_XCP_REQ_CTO_Byte36:0, STS_XCP_REQ_CTO_Byte37:0, STS_XCP_REQ_CTO_Byte38:0, STS_XCP_REQ_CTO_Byte39:0, STS_XCP_REQ_CTO_Byte40:0, STS_XCP_REQ_CTO_Byte41:0, STS_XCP_REQ_CTO_Byte42:0, STS_XCP_REQ_CTO_Byte43:0, STS_XCP_REQ_CTO_Byte44:0, STS_XCP_REQ_CTO_Byte45:0, STS_XCP_REQ_CTO_Byte46:0, STS_XCP_REQ_CTO_Byte47:0, STS_XCP_REQ_CTO_Byte48:0, STS_XCP_REQ_CTO_Byte49:0, STS_XCP_REQ_CTO_Byte50:0, STS_XCP_REQ_CTO_Byte51:0, STS_XCP_REQ_CTO_Byte52:0, STS_XCP_REQ_CTO_Byte53:0, STS_XCP_REQ_CTO_Byte54:0, STS_XCP_REQ_CTO_Byte55:0, STS_XCP_REQ_CTO_Byte56:0, STS_XCP_REQ_CTO_Byte57:0, STS_XCP_REQ_CTO_Byte58:0, STS_XCP_REQ_CTO_Byte59:0, STS_XCP_REQ_CTO_Byte60:0, STS_XCP_REQ_CTO_Byte61:0, STS_XCP_REQ_CTO_Byte62:0, STS_XCP_REQ_CTO_Byte63:0]}, required-interface=Pi_SG_XcpCTOReq_AL
    provide port Pp_SG_XcpDAQResp_AL: nonqueued-sender-com-spec{data-element=Vdp_SG_XcpDAQResp_AL, init-value=fields=[STS_XCP_RES_DAQ_Byte0:0, STS_XCP_RES_DAQ_Byte1:0, STS_XCP_RES_DAQ_Byte2:0, STS_XCP_RES_DAQ_Byte3:0, STS_XCP_RES_DAQ_Byte4:0, STS_XCP_RES_DAQ_Byte5:0, STS_XCP_RES_DAQ_Byte6:0, STS_XCP_RES_DAQ_Byte7:0, STS_XCP_RES_DAQ_Byte8:0, STS_XCP_RES_DAQ_Byte9:0, STS_XCP_RES_DAQ_Byte10:0, STS_XCP_RES_DAQ_Byte11:0, STS_XCP_RES_DAQ_Byte12:0, STS_XCP_RES_DAQ_Byte13:0, STS_XCP_RES_DAQ_Byte14:0, STS_XCP_RES_DAQ_Byte15:0, STS_XCP_RES_DAQ_Byte16:0, STS_XCP_RES_DAQ_Byte17:0, STS_XCP_RES_DAQ_Byte18:0, STS_XCP_RES_DAQ_Byte19:0, STS_XCP_RES_DAQ_Byte20:0, STS_XCP_RES_DAQ_Byte21:0, STS_XCP_RES_DAQ_Byte22:0, STS_XCP_RES_DAQ_Byte23:0, STS_XCP_RES_DAQ_Byte24:0, STS_XCP_RES_DAQ_Byte25:0, STS_XCP_RES_DAQ_Byte26:0, STS_XCP_RES_DAQ_Byte27:0, STS_XCP_RES_DAQ_Byte28:0, STS_XCP_RES_DAQ_Byte29:0, STS_XCP_RES_DAQ_Byte30:0, STS_XCP_RES_DAQ_Byte31:0, STS_XCP_RES_DAQ_Byte32:0, STS_XCP_RES_DAQ_Byte33:0, STS_XCP_RES_DAQ_Byte34:0, STS_XCP_RES_DAQ_Byte35:0, STS_XCP_RES_DAQ_Byte36:0, STS_XCP_RES_DAQ_Byte37:0, STS_XCP_RES_DAQ_Byte38:0, STS_XCP_RES_DAQ_Byte39:0, STS_XCP_RES_DAQ_Byte40:0, STS_XCP_RES_DAQ_Byte41:0, STS_XCP_RES_DAQ_Byte42:0, STS_XCP_RES_DAQ_Byte43:0, STS_XCP_RES_DAQ_Byte44:0, STS_XCP_RES_DAQ_Byte45:0, STS_XCP_RES_DAQ_Byte46:0, STS_XCP_RES_DAQ_Byte47:0, STS_XCP_RES_DAQ_Byte48:0, STS_XCP_RES_DAQ_Byte49:0, STS_XCP_RES_DAQ_Byte50:0, STS_XCP_RES_DAQ_Byte51:0, STS_XCP_RES_DAQ_Byte52:0, STS_XCP_RES_DAQ_Byte53:0, STS_XCP_RES_DAQ_Byte54:0, STS_XCP_RES_DAQ_Byte55:0, STS_XCP_RES_DAQ_Byte56:0, STS_XCP_RES_DAQ_Byte57:0, STS_XCP_RES_DAQ_Byte58:0, STS_XCP_RES_DAQ_Byte59:0, STS_XCP_RES_DAQ_Byte60:0, STS_XCP_RES_DAQ_Byte61:0, STS_XCP_RES_DAQ_Byte62:0, STS_XCP_RES_DAQ_Byte63:0]}, provided-interface=Pi_SG_XcpDAQResp_AL
    provide port Pp_SG_XcpCTOResp_AL: nonqueued-sender-com-spec{data-element=Vdp_SG_XcpCTOResp_AL, init-value=fields=[STS_XCP_RES_CTO_Byte0:0, STS_XCP_RES_CTO_Byte1:0, STS_XCP_RES_CTO_Byte2:0, STS_XCP_RES_CTO_Byte3:0, STS_XCP_RES_CTO_Byte4:0, STS_XCP_RES_CTO_Byte5:0, STS_XCP_RES_CTO_Byte6:0, STS_XCP_RES_CTO_Byte7:0, STS_XCP_RES_CTO_Byte8:0, STS_XCP_RES_CTO_Byte9:0, STS_XCP_RES_CTO_Byte10:0, STS_XCP_RES_CTO_Byte11:0, STS_XCP_RES_CTO_Byte12:0, STS_XCP_RES_CTO_Byte13:0, STS_XCP_RES_CTO_Byte14:0, STS_XCP_RES_CTO_Byte15:0, STS_XCP_RES_CTO_Byte16:0, STS_XCP_RES_CTO_Byte17:0, STS_XCP_RES_CTO_Byte18:0, STS_XCP_RES_CTO_Byte19:0, STS_XCP_RES_CTO_Byte20:0, STS_XCP_RES_CTO_Byte21:0, STS_XCP_RES_CTO_Byte22:0, STS_XCP_RES_CTO_Byte23:0, STS_XCP_RES_CTO_Byte24:0, STS_XCP_RES_CTO_Byte25:0, STS_XCP_RES_CTO_Byte26:0, STS_XCP_RES_CTO_Byte27:0, STS_XCP_RES_CTO_Byte28:0, STS_XCP_RES_CTO_Byte29:0, STS_XCP_RES_CTO_Byte30:0, STS_XCP_RES_CTO_Byte31:0, STS_XCP_RES_CTO_Byte32:0, STS_XCP_RES_CTO_Byte33:0, STS_XCP_RES_CTO_Byte34:0, STS_XCP_RES_CTO_Byte35:0, STS_XCP_RES_CTO_Byte36:0, STS_XCP_RES_CTO_Byte37:0, STS_XCP_RES_CTO_Byte38:0, STS_XCP_RES_CTO_Byte39:0, STS_XCP_RES_CTO_Byte40:0, STS_XCP_RES_CTO_Byte41:0, STS_XCP_RES_CTO_Byte42:0, STS_XCP_RES_CTO_Byte43:0, STS_XCP_RES_CTO_Byte44:0, STS_XCP_RES_CTO_Byte45:0, STS_XCP_RES_CTO_Byte46:0, STS_XCP_RES_CTO_Byte47:0, STS_XCP_RES_CTO_Byte48:0, STS_XCP_RES_CTO_Byte49:0, STS_XCP_RES_CTO_Byte50:0, STS_XCP_RES_CTO_Byte51:0, STS_XCP_RES_CTO_Byte52:0, STS_XCP_RES_CTO_Byte53:0, STS_XCP_RES_CTO_Byte54:0, STS_XCP_RES_CTO_Byte55:0, STS_XCP_RES_CTO_Byte56:0, STS_XCP_RES_CTO_Byte57:0, STS_XCP_RES_CTO_Byte58:0, STS_XCP_RES_CTO_Byte59:0, STS_XCP_RES_CTO_Byte60:0, STS_XCP_RES_CTO_Byte61:0, STS_XCP_RES_CTO_Byte62:0, STS_XCP_RES_CTO_Byte63:0]}, provided-interface=Pi_SG_XcpCTOResp_AL
    provide port PostRadarProcessing_CAN_Tx: server-com-spec{operation=RE_Communication_Tx, queue-length=1}, provided-interface=PostRadarProcessing_CAN_Tx
    4 x require port:
      Rp_Vbatt_State: nonqueued-receiver-com-spec{data-element=De_Vbatt_State, filter=data-filter-type=ALWAYS, init-value=0}, required-interface=Pi_Vbatt_State
      Rp_TimeSync_Status_No_Tsyn_Error: nonqueued-receiver-com-spec{data-element=De_STS_No_TSyn_Error, filter=data-filter-type=ALWAYS, init-value=0}, required-interface=Pi_STS_No_TSyn_Error
      Rp_Time_Stamp_Delta: nonqueued-receiver-com-spec{data-element=De_Time_Stamp_Delta, filter=data-filter-type=ALWAYS, init-value=0}, required-interface=Pi_Time_Stamp_Delta
      Rp_OperationMode_System: nonqueued-receiver-com-spec{data-element=De_OperationMode_System, filter=data-filter-type=ALWAYS, init-value=0}, required-interface=Pi_OperationModeType
    9 x provide port:
      Pp_WarningRelevantObjectDetected_AL: nonqueued-sender-com-spec{data-element=Vdp_WarningRelevantObjectDetected_AL, init-value=0}, provided-interface=Pi_WarningRelevantObjectDetected_AL
      Pp_VCAN_Srv_DisableAppTx: server-com-spec{operation=Operation, queue-length=1}, provided-interface=Pi_VCAN_Srv_DisableAppTx
      Pp_VCAN_Srv_EnableAppTx: server-com-spec{operation=Operation, queue-length=1}, provided-interface=Pi_VCAN_Srv_EnableAppTx
      Pp_SG_RDR_BSD1_Tx_ALPCAN: nonqueued-sender-com-spec{data-element=Vdp_SG_RDR_BSD1_Tx_ALPCAN, init-value=fields=[BlindSpotCollisionWarningLevel_Tx:0, BlindSpotDetectionState_Tx:0]}, provided-interface=Pi_SG_RDR_BSD1_Tx_ALPCAN
      Pp_SG_RadarHeader_ALPCAN: nonqueued-sender-com-spec{data-element=Vdp_SG_RadarHeader_ALPCAN, init-value=fields=[HED_ALIGN_HOR_REF:0, HED_ALIGN_VER_REF:0, HED_Auth_CRC32:0, HED_DATA_QUALIFIER:0, HED_DET_BI_STATIC_COUNT:0, HED_DET_NUM_OF_1PASS:0, HED_DET_NUM_OF_2PASS:0, HED_DET_RANGE_MAX:0, HED_DET_RANGE_MIN:0, HED_DET_SPEED_RANGE_MAX:0, HED_DET_SPEED_RANGE_MIN:0, HED_FOV_HOR_MAX:0, HED_FOV_HOR_MIN:0, HED_FOV_VER_MAX:0, HED_FOV_VER_MIN:0, HED_LOOK_ID:0, HED_LOOK_INDEX:0, HED_MAX_NUM_OF_DETECTIONS:0, HED_MH_CRC16:0, HED_MH_CYCLE_COUNTER:0, HED_NUM_OF_RESTBINS_USED:0, HED_NUM_OF_VALID_DETECTIONS:0, HED_OPERATION_MODE:0, HED_PROCESSED_RANGE:0, HED_R_WRAPPING:0, HED_Rain_Level:0, HED_RDR_HEADER_CMAC:5 x 0, HED_RDR_HEADER_FV:7 x 0, HED_SCAN_INDEX:0, HED_SENSOR_TIME_STAMP_NS:0, HED_SENSOR_TIME_STAMP_SEC:0, HED_SLOPE_CORR_EXECUTIONFLAG:0, HED_TIME_SYNC_SRC_MASTER:0, HED_TIME_SYNC_VALIDITY_FLAG:0, HED_TRIGGER_TIME:0, HED_V_WRAPPING:0]}, provided-interface=Pi_SG_RadarHeader_ALPCAN
      Pp_SG_RadarStatus1_ALPCAN: nonqueued-sender-com-spec{data-element=Vdp_SG_RadarStatus1_ALPCAN, init-value=fields=[STS_AF_TIME_INST:0, STS_AF_TIME_PEAK:0, STS_DET_DBC_BASE_VER_MAJOR:0, STS_DET_DBC_BASE_VER_MINOR:0, STS_DIST_FRNT_BMPR_TO_RR_AXL:0, STS_HARDWARE_VERSION:0, STS_MAIN_CORE_TIME_INST:0, STS_MAIN_CORE_TIME_PEAK:0, STS_MH_001_CRC16:0, STS_MH_001_CYCLE_COUNTER:0, STS_PBL_VERSION_FIELD1:0, STS_PBL_VERSION_FIELD2:0, STS_PBL_VERSION_FIELD3:0, STS_PBL_VERSION_FIELD4:0, STS_PCAN_PROTOCOL_VER_MAJOR:0, STS_PCAN_PROTOCOL_VER_MINOR:0, STS_PLATFORM_VARIANT:0, STS_RDD_CORE_TIME_INST:0, STS_RDD_CORE_TIME_PEAK:0, STS_SENSOR_HEIGHT:0, STS_SENSOR_MOUNT_ORNT_PITCH:0, STS_SENSOR_MOUNT_ORNT_ROLL:0, STS_SENSOR_MOUNT_ORNT_YAW:0, STS_SENSOR_MOUNT_POS_X:0, STS_SENSOR_MOUNT_POS_Y:0, STS_SENSOR_MOUNT_POS_Z:0, STS_SENSOR_POLARITY:0, STS_SENSOR_POSITION:0, STS_SERIAL_NUM_JULIAN_DAY:0, STS_SERIAL_NUM_JULIAN_YEAR:0, STS_SERIAL_NUMBER_SEQUENCE:0, STS_SMC_CAL_VER_MAJOR:0, STS_SMC_CAL_VER_MINOR:0, STS_SMC_PLATFROM_VERSION:0, STS_SMC_SECTION_COMPTBLITY:0, STS_SP_CORE_TIME_INST:0, STS_SP_CORE_TIME_PEAK:0, STS_SW_VERSION_FIELD1:0, STS_SW_VERSION_FIELD2:0, STS_SW_VERSION_FIELD3:0, STS_SW_VERSION_FIELD4:0, STS_TIME_SINCE_POWER_ON:0, STS_USC_CAL_VER_MAJOR:0, STS_USC_CAL_VER_MINOR:0, STS_USC_SECTION_COMPTBLITY:0, STS_VIN_Status:0]}, provided-interface=Pi_SG_RadarStatus1_ALPCAN
      Pp_SG_GW_prop_ADAS_BSIS_info_ALPCAN: nonqueued-sender-com-spec{data-element=Vdp_SG_GW_prop_ADAS_BSIS_info_ALPCAN, init-value=fields=[BlindSpotCollisionWarningLevel:0, BlindSpotDetectionState:0]}, provided-interface=Pi_SG_GW_prop_ADAS_BSIS_info_ALPCAN
      Pp_SG_prop_ADAS_MOIS_info_ALVCAN: nonqueued-sender-com-spec{data-element=Vdp_SG_prop_ADAS_MOIS_info_ALVCAN, init-value=fields=[rdn_MOISCollisionWarningLevel:0, rdn_MovingObjectDetectionState:0]}, provided-interface=Pi_SG_prop_ADAS_MOIS_info_ALVCAN
      Pp_SG_MOIS_ALVCAN: nonqueued-sender-com-spec{data-element=Vdp_SG_MOIS_ALVCAN, init-value=fields=[MOISCollisionWarningLevel:0, MovingObjectDetectionState:0]}, provided-interface=Pi_SG_MOIS_ALVCAN
    36 x require port:
      Rp_SG_Fusion_AlignmentStatus2_ALPCAN: nonqueued-receiver-com-spec{data-element=Vdp_SG_Fusion_AlignmentStatus2_ALPCAN, init-value=fields=[AL_STS_002_CYCLE_COUNTER_Rx:0, AL_STS_002_MH_CRC16_Rx:0, STS_AlignmentServiceStatus_Rx:0, STS_AlignmentShortTrackStatus_Rx:0, STS_AlignmentStaticStatus_Rx:0, STS_AverageNumberOfDetections_Rx:0, STS_AverageSpeed_Rx:0, STS_DistanceAbsolute_Rx:0, STS_DistanceEffective_Rx:0, STS_DurationAbsolute_Rx:0, STS_DurationEffective_Rx:0, STS_ImpactByInterference_Rx:0, STS_Measured_Range_Rx:0, STS_MeasuredAmpSTD_Rx:0, STS_MeasuredRangeRate_Rx:0, STS_MeasuredRangeRateStd_Rx:0, STS_MeasuredRangeStd_Rx:0, STS_MeasuredRawAmplitude_Rx:0, STS_VehicleCondition_Rx:0]}, required-interface=Pi_SG_Fusion_AlignmentStatus2_ALPCAN
      Rp_SG_GW_VI_ALPCAN: nonqueued-receiver-com-spec{data-element=Vdp_SG_GW_VI_ALPCAN, init-value=fields=VehicleIdentification:0}, required-interface=Pi_SG_GW_VI_ALPCAN
      Rp_SG_ETC2_03_ALVCAN: nonqueued-receiver-com-spec{data-element=Vdp_SG_ETC2_03_ALVCAN, init-value=fields=TransCurrentGear_03:0}, required-interface=Pi_SG_ETC2_03_ALVCAN
      Rp_SG_GW_ETC2_03_ALPCAN: nonqueued-receiver-com-spec{data-element=Vdp_SG_GW_ETC2_03_ALPCAN, init-value=fields=TransCurrentGear_03:0}, required-interface=Pi_SG_GW_ETC2_03_ALPCAN
      Rp_SG_GW_CLS_Tx_16_ALPCAN: nonqueued-receiver-com-spec{data-element=Vdp_SG_GW_CLS_Tx_16_ALPCAN, init-value=fields=[Crawler_confi_status_info:0, Transmission_type_info:0]}, required-interface=Pi_SG_GW_CLS_Tx_16_ALPCAN
      Rp_SG_GW_OEL_ALPCAN: nonqueued-receiver-com-spec{data-element=Vdp_SG_GW_OEL_ALPCAN, init-value=fields=[HazardLightSwitch:0, HighLowBeamSwitch:0, TurnSignalSwitch:0]}, required-interface=Pi_SG_GW_OEL_ALPCAN
      Rp_SG_Fusion_RadarHeader_ALPCAN: nonqueued-receiver-com-spec{data-element=Vdp_SG_Fusion_RadarHeader_ALPCAN, init-value=fields=[HED_ALIGN_HOR_REF_Rx:0, HED_ALIGN_VER_REF_Rx:0, HED_Auth_CRC32_Rx:0, HED_DATA_QUALIFIER_Rx:0, HED_DET_BI_STATIC_COUNT_Rx:0, HED_DET_NUM_OF_1PASS_Rx:0, HED_DET_NUM_OF_2PASS_Rx:0, HED_DET_RANGE_MAX_Rx:0, HED_DET_RANGE_MIN_Rx:0, HED_DET_SPEED_RANGE_MAX_Rx:0, HED_DET_SPEED_RANGE_MIN_Rx:0, HED_FOV_HOR_MAX_Rx:0, HED_FOV_HOR_MIN_Rx:0, HED_FOV_VER_MAX_Rx:0, HED_FOV_VER_MIN_Rx:0, HED_LOOK_ID_Rx:0, HED_LOOK_INDEX_Rx:0, HED_MAX_NUM_OF_DETECTIONS_Rx:0, HED_MH_CRC16_Rx:0, HED_MH_CYCLE_COUNTER_Rx:0, HED_NUM_OF_RESTBINS_USED_Rx:0, HED_NUM_OF_VALID_DETECTIONS_Rx:0, HED_OPERATION_MODE_Rx:0, HED_PROCESSED_RANGE_Rx:0, HED_R_WRAPPING_Rx:0, HED_Rain_Level_Rx:0, HED_RDR_HEADER_CMAC_Rx:5 x 0, HED_RDR_HEADER_FV_Rx:7 x 0, HED_SCAN_INDEX_Rx:0, HED_SENSOR_TIME_STAMP_NS_Rx:0, HED_SENSOR_TIME_STAMP_SEC_Rx:0, HED_SLOPE_CORR_EXECUTIONFLAG_Rx:0, HED_TIME_SYNC_SRC_MASTER_Rx:0, HED_TIME_SYNC_VALIDITY_FLAG_Rx:0, HED_TRIGGER_TIME_Rx:0, HED_V_WRAPPING_Rx:0]}, required-interface=Pi_SG_Fusion_RadarHeader_ALPCAN
      Rp_SG_GW_VD_ALPCAN: nonqueued-receiver-com-spec{data-element=Vdp_SG_GW_VD_ALPCAN, init-value=fields=TotalVehicleDistance:0}, required-interface=Pi_SG_GW_VD_ALPCAN
      Rp_SG_OEL_ALVCAN: nonqueued-receiver-com-spec{data-element=Vdp_SG_OEL_ALVCAN, init-value=fields=[HazardLightSwitch:0, HighLowBeamSwitch:0, TurnSignalSwitch:0]}, required-interface=Pi_SG_OEL_ALVCAN
      Rp_SG_VI_ALVCAN: nonqueued-receiver-com-spec{data-element=Vdp_SG_VI_ALVCAN, init-value=fields=VehicleIdentification:0}, required-interface=Pi_SG_VI_ALVCAN
      Rp_SG_Fusion_RadarStatus2_ALPCAN: nonqueued-receiver-com-spec{data-element=Vdp_SG_Fusion_RadarStatus2_ALPCAN, init-value=fields=[STS_AF_CORE_THROUGHPUT_Rx:0, STS_BRR_STATUS_Rx:0, STS_CAN_NM_State_Rx:0, STS_CORE_ACTV_FLT_BYTE_0_to_3_Rx:0, STS_CORE_ACTV_FLT_BYTE_4_to_7_Rx:0, STS_CORE_ACTV_FLT_BYTE_8_to_11_Rx:0, STS_CORE_ACTV_FLT_BYTE_11_to_15_Rx:0, STS_First_CAN_Det_Inst_Latency_Rx:0, STS_Gear_Position_Rx:0, STS_INTRFC_VERSION_ID_MAJOR_Rx:0, STS_INTRFC_VERSION_ID_MINOR_Rx:0, STS_INTRFC_VERSION_ID_PATCH_Rx:0, STS_Last_CAN_Det_Inst_Latency_Rx:0, STS_MCU_TEMP_Rx:0, STS_MH_002_CRC16_Rx:0, STS_MH_002_CYCLE_COUNTER_Rx:0, 0, STS_MMIC_TEMP_RX_Rx:0, STS_MMIC_TEMP_TX0_Rx:0, STS_MMIC_TEMP_TX1_2_Rx:0, STS_MMIC_TEMP_TX3_4_Rx:0, STS_NO_TSYN_ERROR_Rx:0, STS_POINT_OF_TRIGGER_Rx:0, STS_RAIN_COUNT_Rx:0, STS_RDD_CORE_THROUGHPUT_Rx:0, STS_SCAN_TYPE_Rx:0, STS_STEERING_ANGLE_Rx:0, STS_STEERING_ANGLE_SIGN_Rx:0, STS_TIME_SYNC_OFFSET_Rx:0, STS_TKEY_ACTV_FLT_BYTE_0_to_3_Rx:0, STS_TKEY_ACTV_FLT_BYTE_4_to_5_Rx:0, STS_VEH_SPEED_DIRECTION_Rx:0, STS_Vehicle_Speed_Calc_QF_Rx:0, STS_VEHICLE_SPEED_CALC_Rx:0, STS_VEHICLE_SUPPLY_VOLTAGE_Rx:0, STS_XCVR_OPERATIONAL_Rx:0, STS_YAW_RATE_BIAS_Rx:0, STS_Yaw_Rate_Calc_QF_Rx:0]}, required-interface=Pi_SG_Fusion_RadarStatus2_ALPCAN
      Rp_SG_VD_ALVCAN: nonqueued-receiver-com-spec{data-element=Vdp_SG_VD_ALVCAN, init-value=fields=Total_vehicle_distance:0}, required-interface=Pi_SG_VD_ALVCAN
      Rp_SG_GW_CCVS1_ALPCAN: nonqueued-receiver-com-spec{data-element=Vdp_SG_GW_CCVS1_ALPCAN, init-value=fields=[BrakeSwitch:0, ParkingBrakeSwitch:0, WheelBasedVehicleSpeed:0]}, required-interface=Pi_SG_GW_CCVS1_ALPCAN
      Rp_SG_Fusion_AlignmentStatus1_ALPCAN: nonqueued-receiver-com-spec{data-element=Vdp_SG_Fusion_AlignmentStatus1_ALPCAN, init-value=fields=[AL_STS_001_CYCLE_COUNTER_Rx:0, AL_STS_001_MH_CRC16_Rx:0, STS_AAAzimuthStd_Rx:0, STS_AACurrentAzimuth_Rx:0, STS_AACurrentElevation_Rx:0, STS_AACurrentRoll_Rx:0, STS_AAElevationStd_Rx:0, STS_AARoll_Std_Rx:0, STS_AlignmentAutoStatus_Rx:0, STS_AlignmentAzimuth_Rx:0, STS_AlignmentElevation_Rx:0, STS_AlignmentError_Rx:0, STS_AlignmentModeIn_Rx:0, STS_AlignmentModeOut_Rx:0, STS_AutoAlignmentFailRootCause_Rx:0, STS_AzimuthErrorNegative_Rx:0, STS_AzimuthErrorPositive_Rx:0, STS_AzimuthStd_Rx:0, STS_AzimuthUpdates_Rx:0, STS_CalDisplay_Rx:0, STS_CalTime_Rx:0, STS_CoordinateSystemInput_Rx:0, STS_ElevationErrorNegative_Rx:0, STS_ElevationErrorPositive_Rx:0, STS_ElevationStd_Rx:0, STS_ElevationUpdates_Rx:0, STS_HostSpdCompensationFactorQF_Rx:0, STS_HostSpeedCompensationFactor_Rx:0, 0, 0, 0, 0, 0, 0, STS_ProgressPercent_Rx:0, STS_RadarTypeInput_Rx:0, STS_Roll_Updates_Rx:0, STS_RollErrorNegative_Rx:0, STS_RollErrorPositive_Rx:0, STS_StartAzimuth_Rx:0, STS_StartElevation_Rx:0, STS_StartRoll_Rx:0]}, required-interface=Pi_SG_Fusion_AlignmentStatus1_ALPCAN
      Rp_SG_CLS_Tx_4_ALVCAN: nonqueued-receiver-com-spec{data-element=Vdp_SG_CLS_Tx_4_ALVCAN, init-value=fields=[Ignition:0, ReverseSwitchInfo:0]}, required-interface=Pi_SG_CLS_Tx_4_ALVCAN
      Rp_SG_Fusion_RadarCapability_ALPCAN: nonqueued-receiver-com-spec{data-element=Vdp_SG_Fusion_RadarCapability_ALPCAN, init-value=fields=[CAP_AngleAzimuthRangeEnd_Rx:0, CAP_AngleAzimuthRangeStart_Rx:0, CAP_BlockageActive_Rx:0, CAP_BlockageProbability_Rx:0, CAP_BlockageSensitivity_Rx:0, CAP_BlockageStatus_Rx:0, CAP_BlockageValue_Rx:0, CAP_CYCLE_COUNTER_Rx:0, CAP_DampingActive_Rx:0, CAP_DampingCurrent_Rx:0, CAP_DampingStandardDeviation_Rx:0, CAP_DampingStatus_Rx:0, CAP_FreeSightCheckActive_Rx:0, CAP_FreeSightCheckStatus_Rx:0, CAP_MaxDetectionRangeCar_0_Rx:0, CAP_MaxDetectionRangeCar_1_Rx:0, CAP_MaxDetectionRangeCar_2_Rx:0, CAP_MaxDetRangeMotorbike_0_Rx:0, CAP_MaxDetRangeMotorbike_1_Rx:0, CAP_MaxDetRangeMotorbike_2_Rx:0, CAP_MaxDetRangePedestrian_0_Rx:0, CAP_MaxDetRangePedestrian_1_Rx:0, CAP_MaxDetRangePedestrian_2_Rx:0, CAP_MH_CRC16_Rx:0, CAP_RangeEstimationActive_Rx:0, CAP_RangeEstimationStatus_Rx:0, CAP_SideLobeLevelBeamformer_Rx:0, CAP_SLBlockageFilterValue_Rx:0, CAP_SLBlockageFlag_Rx:0, CAP_SLLMonitoringActive_Rx:0, CAP_SLLMonitoringStatus_Rx:0]}, required-interface=Pi_SG_Fusion_RadarCapability_ALPCAN
      Rp_SG_GW_ETC2_ALPCAN: nonqueued-receiver-com-spec{data-element=Vdp_SG_GW_ETC2_ALPCAN, init-value=fields=TransCurrentGear_00:0}, required-interface=Pi_SG_GW_ETC2_ALPCAN
      Rp_SG_GW_VDC2_ALPCAN: nonqueued-receiver-com-spec{data-element=Vdp_SG_GW_VDC2_ALPCAN, init-value=fields=[LateralAcceleration:0, LongitudinalAcceleration:0, SteerWheelAngle:0, YawRate:0]}, required-interface=Pi_SG_GW_VDC2_ALPCAN
      Rp_SG_SAS_ALVCAN: nonqueued-receiver-com-spec{data-element=Vdp_SG_SAS_ALVCAN, init-value=fields=[ActiveMode:0, Calibrated:0, MessageChecksum:0, MessageCounter:0, SteeringWheelAngle:0, SteeringWheelAngleRange:0, SteeringWheelAngleRangeCounter:0, SteeringWheelAngleRangeCounterType:0]}, required-interface=Pi_SG_SAS_ALVCAN
      Rp_SG_TD_ALVCAN: nonqueued-receiver-com-spec{data-element=Vdp_SG_TD_ALVCAN, init-value=fields=[Day:0, Hours:0, LocalHourOffset:125, LocalMinuteOffset:125, Minutes:0, Month:0, Seconds:0, Year:0]}, required-interface=Pi_SG_TD_ALVCAN
      Rp_SG_ETC2_00_ALVCAN: nonqueued-receiver-com-spec{data-element=Vdp_SG_ETC2_00_ALVCAN, init-value=fields=TransCurrentGear_00:125}, required-interface=Pi_SG_ETC2_00_ALVCAN
      Rp_SG_CLS_Tx_16_ALVCAN: nonqueued-receiver-com-spec{data-element=Vdp_SG_CLS_Tx_16_ALVCAN, init-value=fields=[Crawler_confi_status_info:0, Transmission_type_info:0]}, required-interface=Pi_SG_CLS_Tx_16_ALVCAN
      Rp_SG_GW_TD_ALPCAN: nonqueued-receiver-com-spec{data-element=Vdp_SG_GW_TD_ALPCAN, init-value=fields=[Day:0, Hours:0, LocalHourOffset:0, LocalMinuteOffset:0, Minutes:0, Month:0, Seconds:0, Year:0]}, required-interface=Pi_SG_GW_TD_ALPCAN
      Rp_SG_CCVS1_ALVCAN: nonqueued-receiver-com-spec{data-element=Vdp_SG_CCVS1_ALVCAN, init-value=fields=[BrakeSwitch:0, ParkingBrakeSwitch:0, WheelBasedVehicleSpeed:0]}, required-interface=Pi_SG_CCVS1_ALVCAN
      Rp_SG_VDC2_ALVCAN: nonqueued-receiver-com-spec{data-element=Vdp_SG_VDC2_ALVCAN, init-value=fields=[LateralAcceleration:32127, LongitudinalAcceleration:125, SteerWheelAngle:32127, YawRate:32113]}, required-interface=Pi_SG_VDC2_ALVCAN
      Rp_SG_Fusion_RadarStatus_ALPCAN: nonqueued-receiver-com-spec{data-element=Vdp_SG_Fusion_RadarStatus_ALPCAN, init-value=fields=[STS_AF_TIME_INST_Rx:0, STS_AF_TIME_PEAK_Rx:0, STS_DET_DBC_BASE_VER_MAJOR_Rx:0, STS_DET_DBC_BASE_VER_MINOR_Rx:0, STS_DIST_FRNT_BMPR_TO_RR_AXL_Rx:0, STS_HARDWARE_VERSION_Rx:0, STS_MAIN_CORE_TIME_INST_Rx:0, STS_MAIN_CORE_TIME_PEAK_Rx:0, STS_MH_001_CRC16_Rx:0, STS_MH_001_CYCLE_COUNTER_Rx:0, STS_PBL_VERSION_FIELD1_Rx:0, STS_PBL_VERSION_FIELD2_Rx:0, STS_PBL_VERSION_FIELD3_Rx:0, STS_PBL_VERSION_FIELD4_Rx:0, STS_PCAN_PROTOCOL_VER_MAJOR_Rx:0, STS_PCAN_PROTOCOL_VER_MINOR_Rx:0, STS_PLATFORM_VARIANT_Rx:0, STS_RDD_CORE_TIME_INST_Rx:0, STS_RDD_CORE_TIME_PEAK_Rx:0, STS_SENSOR_HEIGHT_Rx:0, STS_SENSOR_MOUNT_ORNT_PITCH_Rx:0, STS_SENSOR_MOUNT_ORNT_ROLL_Rx:0, STS_SENSOR_MOUNT_ORNT_YAW_Rx:0, STS_SENSOR_MOUNT_POS_X_Rx:0, STS_SENSOR_MOUNT_POS_Y_Rx:0, STS_SENSOR_MOUNT_POS_Z_Rx:0, STS_SENSOR_POLARITY_Rx:0, STS_SENSOR_POSITION_Rx:0, STS_SERIAL_NUM_JULIAN_DAY_Rx:0, STS_SERIAL_NUM_JULIAN_YEAR_Rx:0, STS_SERIAL_NUMBER_SEQUENCE_Rx:0, STS_SMC_CAL_VER_MAJOR_Rx:0, STS_SMC_CAL_VER_MINOR_Rx:0, STS_SMC_PLATFROM_VERSION_Rx:0, STS_SMC_SECTION_COMPTBLITY_Rx:0, STS_SP_CORE_TIME_INST_Rx:0, STS_SP_CORE_TIME_PEAK_Rx:0, STS_SW_VERSION_FIELD1_Rx:0, STS_SW_VERSION_FIELD2_Rx:0, STS_SW_VERSION_FIELD3_Rx:0, STS_SW_VERSION_FIELD4_Rx:0, STS_TIME_SINCE_POWER_ON_Rx:0, STS_USC_CAL_VER_MAJOR_Rx:0, STS_USC_CAL_VER_MINOR_Rx:0, STS_USC_SECTION_COMPTBLITY_Rx:0, STS_VIN_Status_Rx:0]}, required-interface=Pi_SG_Fusion_RadarStatus_ALPCAN
      Rp_SG_GW_SAS_ALPCAN: nonqueued-receiver-com-spec{data-element=Vdp_SG_GW_SAS_ALPCAN, init-value=fields=[MessageChecksum:0, MessageCounter:0, SteerAngleSensorActiveMode:0, SteerAngleSensorCalibrated:0, SteerWheelAngle:0, SteerWheelAngleRange:0, SteerWheelAngleRangeCounter:0, SteerWheelAngleRangeCounterType:0]}, required-interface=Pi_SG_GW_SAS_ALPCAN
      Rp_SG_GW_ADAS_FN_Enable_disable_sts_ALPCAN: nonqueued-receiver-com-spec{data-element=Vdp_SG_GW_ADAS_FN_Enable_disable_sts_ALPCAN, init-value=fields=[AEBS_FN_Switch_sts:0, BSIS_fn_Switch_Sts:0, DDAW_fn_switch_sts:0, DDAW_warning_suppression:0, LDWS_FN_Switch_sts:0, MessageAliveCounter:0, MessageCRC:0, MOIS_Fn_Switch_sts:0]}, required-interface=Pi_SG_GW_ADAS_FN_Enable_disable_sts_ALPCAN
      Rp_SG_GW_CLS_Tx_4_ALPCAN: nonqueued-receiver-com-spec{data-element=Vdp_SG_GW_CLS_Tx_4_ALPCAN, init-value=fields=[Ignition:0, ReverseSwitchInfo:0]}, required-interface=Pi_SG_GW_CLS_Tx_4_ALPCAN
      Rp_SG_ADAS_FN_Enable_disable_sts_ALVCAN: nonqueued-receiver-com-spec{data-element=Vdp_SG_ADAS_FN_Enable_disable_sts_ALVCAN, init-value=fields=[BSIS_Fn_Switch_Sts:0, MessageAliveCounter:0, MessageCRC:0, MOIS_Fn_Switch_sts:0]}, required-interface=Pi_SG_ADAS_FN_Enable_disable_sts_ALVCAN
      Rp_Alignment_M2D_Data: nonqueued-receiver-com-spec{data-element=De_Alignment_M2D_Data, filter=data-filter-type=ALWAYS, init-value=fields=[{short-label=static_alignment_data, fields=[yaw:0, pitch:0, plate_angle_deg_scs:0, plate_distance:0, polarity:0, horz_angle_min:0, horz_angle_max:0, vert_angle_min:0, vert_angle_max:0, plate_lat_position:0, mount_loc:0, align_cmd:0, max_abs_misalignment_az:0, max_abs_misalignment_el_sky:0, max_abs_misalignment_el_ground:0, target_height_over_ground:0, k_num_valid_scan_needed:0, k_max_number_of_scans_allowed:0, target_range_rate:0, target_type_select:0, f_data_valid:0]}, {short-label=dynamic_alignment_data, fields=[0, 0, 0, max_abs_misalignment_az:0, short_track_target_height:0, short_track_target_range_rate:0, az_scf_kf_covariance:[0, 0, 0, 0], el_kf_covariance:0, iso_sensor_x_posn:0, iso_sensor_y_posn:0, iso_sensor_z_posn:0, iso_sensor_yaw:0, iso_sensor_pitch:0, iso_sensor_roll:0, distance_rear_axle_to_front_bumper:0, max_abs_misalignment_el_sky:0, max_abs_misalignment_el_ground:0, aacurrent_azimuth:0, aacurrent_elevation:0, 0, 0, mount_loc:0, short_track_exit_condition:0, f_data_valid:0, 0, 0, align_cmd:0, auto_align_status:0, 0, 0, el_roll_kf_covariance:[0, 0, 0, 0], Align_RadarOperation_Mode:0, coordinate_system_input:0]}]}, required-interface=Pi_Alignment_M2D_Data
      Rp_Alignment_Handler: nonqueued-receiver-com-spec{data-element=De_Alignment_Handler, filter=data-filter-type=ALWAYS, init-value=fields=[0, 0, 0, 0, 0, AlignmentAzimuth:0, AlignmentElevation:0, AzimuthStd:0, ElevationStd:0, calTime:0, CalDisplay:0, ProgressPercent:0, AlignmentError:0, ElevationQuality:0, AzimuthQuality:0, Alignment_modeIn:0, AlignmentModeOut:0, 0, Radar_Type_Input:0, CoordinateSystem_Input:0, 0, 0, AlignmentRoll:0, RollStd:0]}, required-interface=Pi_Alignment_Handler
      Rp_AlignmentService: nonqueued-receiver-com-spec{data-element=De_AlignmentService, filter=data-filter-type=ALWAYS, init-value=fields=[DistanceAbsolute:0, DistanceEffective:0, AvgNumOfDet:0, DurationAbsolute:0, DurationEffective:0, AverageSpeed:0, AlignmentServiceSt:0, VehicleCondition:0]}, required-interface=Pi_AlignmentService
      Rp_AlignmentShortTrack: nonqueued-receiver-com-spec{data-element=De_AlignmentShortTrack, filter=data-filter-type=ALWAYS, init-value=fields=AlignShortTrackSt:0}, required-interface=Pi_AlignmentShortTrack
      Rp_AlignmentAuto: nonqueued-receiver-com-spec{data-element=De_AlignmentAuto, filter=data-filter-type=ALWAYS, init-value=fields=[StartAzimuth:0, StartElevation:0, AACurrentAzimuth:0, AACurrentElevation:0, AAAzimuthStd:0, AAElevationStd:0, AARollStd:0, Az_Err_positive:0, Az_Err_negative:0, El_Err_positive:0, El_Err_negative:0, RollError_positive:0, RollError_negative:0, HostScf:0, AzimuthNumUpdates:0, ElevationNumUpdates:0, AutoAlignmentFailRootCause:0, AlignAutoStatus:0, HostScf_QF:0, StartRoll:0, AACurrentRoll:0, RollUpdates:0]}, required-interface=Pi_AlignmentAuto
      Rp_AlignmentStatic: nonqueued-receiver-com-spec{data-element=De_AlignmentStatic, filter=data-filter-type=ALWAYS, init-value=fields=[MeasuredAzimuth:0, MeasuredElevation:0, Measured_Az_Std:0, Measured_El_Std:0, MeasuredRange:0, MeasuredRangeStd:0, MeasuredRangeRate:0, MeasuredRangeRateStd:0, MeasuredAmplitude:0, MeasuredAmpStd:0, AlignmentStaticStatus:0, StatusOfPlate:0, StatusOfAzimuth:0, StatusOfElevation:0, ImpactByInterference:0]}, required-interface=Pi_AlignmentStatic
    19 x provide port:
      Pp_Header_msg_Com_Rx_Timeout_Status: nonqueued-sender-com-spec{data-element=De_Com_Rx_Timeout_Status, init-value=170}, provided-interface=Pi_Com_Rx_Pcan_Timeout_Status
      Pp_Radar_Capability_Com_Rx_Timeout_Status: nonqueued-sender-com-spec{data-element=De_Com_Rx_Timeout_Status, init-value=170}, provided-interface=Pi_Com_Rx_Pcan_Timeout_Status
      Pp_Radar_Status_1_Com_Rx_Timeout_Status: nonqueued-sender-com-spec{data-element=De_Com_Rx_Timeout_Status, init-value=170}, provided-interface=Pi_Com_Rx_Pcan_Timeout_Status
      Pp_Radar_Status_2_Com_Rx_Timeout_Status: nonqueued-sender-com-spec{data-element=De_Com_Rx_Timeout_Status, init-value=170}, provided-interface=Pi_Com_Rx_Pcan_Timeout_Status
      Pp_Alignment_Status_1_Com_Rx_Timeout_Status: nonqueued-sender-com-spec{data-element=De_Com_Rx_Timeout_Status, init-value=170}, provided-interface=Pi_Com_Rx_Pcan_Timeout_Status
      Pp_CCVS1_message_Vcan_Safety_Timeout_Status: nonqueued-sender-com-spec{data-element=De_Com_Rx_Vcan_Timeout_Status, init-value=170}, provided-interface=Pi_Com_Rx_Vcan_Safety_Timeout_Status
      Pp_VDC2_message_Vcan_Safety_Timeout_Status: nonqueued-sender-com-spec{data-element=De_Com_Rx_Vcan_Timeout_Status, init-value=170}, provided-interface=Pi_Com_Rx_Vcan_Safety_Timeout_Status
      Pp_ETC2_MT_Variant_message_Vcan_Safety_Timeout_Status: nonqueued-sender-com-spec{data-element=De_Com_Rx_Vcan_Timeout_Status, init-value=170}, provided-interface=Pi_Com_Rx_Vcan_Safety_Timeout_Status
      Pp_ETC2_AT_AMT_message_Vcan_Safety_Timeout_Status: nonqueued-sender-com-spec{data-element=De_Com_Rx_Vcan_Timeout_Status, init-value=170}, provided-interface=Pi_Com_Rx_Vcan_Safety_Timeout_Status
      Pp_ADAS_Function_Switch_message_Non_Safety_Timeout_Status: nonqueued-sender-com-spec{data-element=De_Com_Rx_Vcan_Non_Safety_Timeout_Status, init-value=170}, provided-interface=Pi_Com_Rx_Vcan_Non_Safety_Timeout_Status
      Pp_OEL_message_Non_Safety_Timeout_Status: nonqueued-sender-com-spec{data-element=De_Com_Rx_Vcan_Non_Safety_Timeout_Status, init-value=170}, provided-interface=Pi_Com_Rx_Vcan_Non_Safety_Timeout_Status
      Pp_TD_message_Non_Safety_Timeout_Status: nonqueued-sender-com-spec{data-element=De_Com_Rx_Vcan_Non_Safety_Timeout_Status, init-value=170}, provided-interface=Pi_Com_Rx_Vcan_Non_Safety_Timeout_Status
      Pp_SAS_message_Non_Safety_Timeout_Status: nonqueued-sender-com-spec{data-element=De_Com_Rx_Vcan_Non_Safety_Timeout_Status, init-value=170}, provided-interface=Pi_Com_Rx_Vcan_Non_Safety_Timeout_Status
      Pp_CLS_TX_4_message_Non_Safety_Timeout_Status: nonqueued-sender-com-spec{data-element=De_Com_Rx_Vcan_Non_Safety_Timeout_Status, init-value=170}, provided-interface=Pi_Com_Rx_Vcan_Non_Safety_Timeout_Status
      Pp_CLS_TX_16_message_Non_Safety_Timeout_Status: nonqueued-sender-com-spec{data-element=De_Com_Rx_Vcan_Non_Safety_Timeout_Status, init-value=170}, provided-interface=Pi_Com_Rx_Vcan_Non_Safety_Timeout_Status
      Pp_VD_message_Non_Safety_Timeout_Status: nonqueued-sender-com-spec{data-element=De_Com_Rx_Vcan_Non_Safety_Timeout_Status, init-value=170}, provided-interface=Pi_Com_Rx_Vcan_Non_Safety_Timeout_Status
      Pp_SG_VehicleStatus_AL: nonqueued-sender-com-spec{data-element=Vdp_SG_VehicleStatus_AL, init-value=fields=[SSTS_CAN_PCAN_MAJOR_ADAS:0, SSTS_CAN_PCAN_MINOR_ADAS:0, SSTS_DRIVE_DIR:0, SSTS_DRIVE_REVERSE:0, SSTS_GEAR_POSITION:0, SSTS_IGN_STATUS:0, SSTS_MH_VS_CRC16:0, SSTS_MH_VS_CYCLE_COUNTER:0, SSTS_STEERING_ANGLE:0, SSTS_STEERING_ANGLE_SIGN:0, SSTS_SW_VERSION_ADAS:0, SSTS_VEH_AbsoluteTime_Day:0, SSTS_VEH_AbsoluteTime_Hour:0, SSTS_VEH_AbsoluteTime_Minute:0, SSTS_VEH_AbsoluteTime_Month:0, SSTS_VEH_AbsoluteTime_Second:0, SSTS_VEH_AbsoluteTime_Year:0, SSTS_VEH_ODOMETER:0, SSTS_VEH_POWER_MODE_STATUS:0, SSTS_VEH_SPD_COMP_FACTOR:0, SSTS_VEH_Status_CMAC:5 x 0, SSTS_VEH_Status_FV:7 x 0, SSTS_VEH_SYSTEM_VOLTAGE:0, SSTS_VEH_TRAILER_CONNECTED:0, SSTS_VEH_VARIANT:0, SSTS_VEHICLE_SPEED_CALC:0, SSTS_VEHICLE_SPEED_CALC_QF:0, SSTS_VEHICLE_STATE:0, SSTS_VIN_Data_Byte0:0, SSTS_VIN_Data_Byte1:0, SSTS_VIN_Data_Byte2:0, SSTS_VIN_Data_Byte3:0, SSTS_VIN_Data_Byte4:0, SSTS_VIN_Data_Byte5:0, SSTS_VIN_Data_Byte6:0, SSTS_VIN_FrameIdx:0, SSTS_YAW_RATE_BIAS:0, SSTS_YAW_RATE_CALC:0, SSTS_YAW_RATE_CALC_QF:0]}, provided-interface=Pi_SG_VehicleStatus_AL
      Pp_VSE_NVM_Params: nonqueued-sender-com-spec{data-element=De_VSE_NVM_Params, init-value=fields=[nvm_last_rem_swa_bias_deg:0, nvm_last_rem_speed_comp:0, nvm_last_rem_stop_yaw_bias_primary_radps:0, nvm_last_rem_stop_yaw_bias_secondary_radps:0, nvm_f_last_rem_swa_bias:0]}, provided-interface=Pi_VSE_NVM_Params
      Pp_Pcan_Communication_ETE_fault: nonqueued-sender-com-spec{data-element=De_Communication_ETE_fault, init-value=170}, provided-interface=Pi_Communication_ETE_fault
    behavior SWC_PLT_Appl_Communication_InternalBehavior: data-type-mapping=defaultDataTypeMappingSet_CPFS, handle-termination-and-restart=NO-SUPPORT
      init event RE_Communication_InitEvent: start-on-event=RE_Communication_Init
      timing event TMT_RE_Communication_Tx: start-on-event=RE_Communication_Tx_50ms, period=0.05
      timing event TMT_RE_Communication_Rx: start-on-event=RE_Communication_Rx, period=0.025
      5 x operation invoked event:
        OIT_Pp_PCAN_Srv_DisableAppTx_Operation_Pp_PCAN_Srv_DisableAppTx_Operation: start-on-event=Pp_PCAN_Srv_DisableAppTx_Operation, operation=Pp_PCAN_Srv_DisableAppTx.Operation
        OIT_Rp_PCAN_Srv_EnableAppTx_Operation_Rp_PCAN_Srv_EnableAppTx_Operation: start-on-event=Pp_PCAN_Srv_EnableAppTx_Operation, operation=Pp_PCAN_Srv_EnableAppTx.Operation
        OIT_PostRadarProcessing_CAN_Tx_RE_Communication_Tx_PostRadarProcessing_CAN_Tx_RE_Communication_Tx: start-on-event=PostRadarProcessing_CAN_Tx_RE_Communication_Tx, operation=PostRadarProcessing_CAN_Tx.RE_Communication_Tx
        OIT_Pp_VCAN_Srv_DisableAppTx_Operation_Pp_VCAN_Srv_DisableAppTx_Operation: start-on-event=Pp_VCAN_Srv_DisableAppTx_Operation, operation=Pp_VCAN_Srv_DisableAppTx.Operation
        OIT_Pp_VCAN_Srv_EnableAppTx_Operation_Pp_VCAN_Srv_EnableAppTx_Operation: start-on-event=Pp_VCAN_Srv_EnableAppTx_Operation, operation=Pp_VCAN_Srv_EnableAppTx.Operation
      timing event TMT_RE_Communication_10ms: start-on-event=RE_Communication_10ms, period=0.01
      9 x runnable:
        RE_Communication_Init
          data-send-points:
            5 x access:
              SEND_Request_SDC_C_consService_RDR_1_ADAS_Vehicle_Status_2b1e055b_requestedMode: accessed-variable=Request_SDC_C_consService_RDR_1_ADAS_Vehicle_Status_2b1e055b.requestedMode
              SEND_Request_SDC_C_consService_RDR_1_ADAS_Vehicle_Status_2b1e055b_CEG_consServiceGrp_RDR_1_ADAS_Vehicle_Status_4b79da85_4D4FE2E4: accessed-variable=Request_SDC_C_consService_RDR_1_ADAS_Vehicle_Status_2b1e055b_CEG_consServiceGrp_RDR_1_ADAS_Vehicle_Status_4b79da85.requestedMode
              SEND_Request_SDC_S_provService_RDR_1_Detections_89f78c9f_requestedMode: accessed-variable=Request_SDC_S_provService_RDR_1_Detections_89f78c9f.requestedMode
              SEND_Request_SDC_S_provService_RDR_1_SW_Info_c2745ec9_requestedMode: accessed-variable=Request_SDC_S_provService_RDR_1_SW_Info_c2745ec9.requestedMode
              SEND_Request_SDC_S_provService_RDR_1_Status_d2069d01_requestedMode: accessed-variable=Request_SDC_S_provService_RDR_1_Status_d2069d01.requestedMode
        RE_Communication_Tx_50ms
          data-receive-point-by-arguments:
            4 x access:
              REC_Rp_Vbatt_State_De_Vbatt_State: accessed-variable=Rp_Vbatt_State.De_Vbatt_State
              REC_Rp_TimeSync_Status_No_Tsyn_Error_De_STS_No_TSyn_Error: accessed-variable=Rp_TimeSync_Status_No_Tsyn_Error.De_STS_No_TSyn_Error
              REC_Rp_Time_Stamp_Delta_De_Time_Stamp_Delta: accessed-variable=Rp_Time_Stamp_Delta.De_Time_Stamp_Delta
              REC_Rp_OperationModeType_De_OperationMode_System: accessed-variable=Rp_OperationMode_System.De_OperationMode_System
          data-send-points:
            215 x access:
              SEND_Pp_RDR_DetectionList_Event_DetectionList_Event: accessed-variable=Pp_RDR_DetectionList_Event.DetectionList_Event
              SEND_Pp_RDR_Radar_SW_Info_RDR_SW_Info: accessed-variable=Pp_RDR_Radar_SW_Info.RDR_SW_Info
              SEND_Pp_RDR_Radar_Status_RDR_Status: accessed-variable=Pp_RDR_Radar_Status.RDR_Status
              SEND_Pp_RDR_NM_CAN_NM_State_Vdp_RDR_NM_CAN_NM_State: accessed-variable=Pp_RDR_NM_CAN_NM_State.Vdp_RDR_NM_CAN_NM_State
              SEND_Pp_RDR_NM_CBV_ActWakeBit_4_Vdp_RDR_NM_CBV_ActWakeBit_4: accessed-variable=Pp_RDR_NM_CBV_ActWakeBit_4.Vdp_RDR_NM_CBV_ActWakeBit_4
              SEND_Pp_RDR_NM_CBV_NMCoordBit_3_Vdp_RDR_NM_CBV_NMCoordBit_3: accessed-variable=Pp_RDR_NM_CBV_NMCoordBit_3.Vdp_RDR_NM_CBV_NMCoordBit_3
              SEND_Pp_RDR_NM_CBV_PNIBit_6_Vdp_RDR_NM_CBV_PNIBit_6: accessed-variable=Pp_RDR_NM_CBV_PNIBit_6.Vdp_RDR_NM_CBV_PNIBit_6
              SEND_Pp_RDR_NM_CBV_ReptMsgBit0_Vdp_RDR_NM_CBV_ReptMsgBit0: accessed-variable=Pp_RDR_NM_CBV_ReptMsgBit0.Vdp_RDR_NM_CBV_ReptMsgBit0
              SEND_Pp_RDR_NM_CBV_ResdBit_1_Vdp_RDR_NM_CBV_ResdBit_1: accessed-variable=Pp_RDR_NM_CBV_ResdBit_1.Vdp_RDR_NM_CBV_ResdBit_1
              SEND_Pp_RDR_NM_CBV_ResdBit_2_Vdp_RDR_NM_CBV_ResdBit_2: accessed-variable=Pp_RDR_NM_CBV_ResdBit_2.Vdp_RDR_NM_CBV_ResdBit_2
              SEND_Pp_RDR_NM_CBV_ResdBit_5_Vdp_RDR_NM_CBV_ResdBit_5: accessed-variable=Pp_RDR_NM_CBV_ResdBit_5.Vdp_RDR_NM_CBV_ResdBit_5
              SEND_Pp_RDR_NM_CBV_ResdBit_7_Vdp_RDR_NM_CBV_ResdBit_7: accessed-variable=Pp_RDR_NM_CBV_ResdBit_7.Vdp_RDR_NM_CBV_ResdBit_7
              SEND_Pp_RDR_NM_PNC_Reserved{1..3}_Vdp_RDR_NM_PNC_Reserved{1..3}: accessed-variable=Pp_RDR_NM_PNC_Reserved{1..3}.Vdp_RDR_NM_PNC_Reserved{1..3}
              SEND_Pp_RDR_NM_PN_User_Data_Vdp_RDR_NM_PN_User_Data: accessed-variable=Pp_RDR_NM_PN_User_Data.Vdp_RDR_NM_PN_User_Data
              SEND_Pp_RDR_NM_Wakeup_And_Reason_Vdp_RDR_NM_Wakeup_And_Reason: accessed-variable=Pp_RDR_NM_Wakeup_And_Reason.Vdp_RDR_NM_Wakeup_And_Reason
              SEND_Pp_SG_TrackerHeader_Vdp_SG_TrackerHeader: accessed-variable=Pp_SG_TrackerHeader.Vdp_SG_TrackerHeader
              SEND_Pp_SG_TrackerObject{001..064}_Vdp_SG_TrackerObject{001..064}: accessed-variable=Pp_SG_TrackerObject{001..064}.Vdp_SG_TrackerObject{001..064}
              SEND_Pp_SG_TrackerStatus_Vdp_SG_TrackerStatus: accessed-variable=Pp_SG_TrackerStatus.Vdp_SG_TrackerStatus
              SEND_Pp_SG_AlignmentStatus1_AL_Vdp_SG_AlignmentStatus1_AL: accessed-variable=Pp_SG_AlignmentStatus1_AL.Vdp_SG_AlignmentStatus1_AL
              SEND_Pp_SG_AlignmentStatus2_AL_Vdp_SG_AlignmentStatus2_AL: accessed-variable=Pp_SG_AlignmentStatus2_AL.Vdp_SG_AlignmentStatus2_AL
              SEND_Pp_SG_Detections_001_004_AL_Vdp_SG_Detections_001_004_AL: accessed-variable=Pp_SG_Detections_001_004_AL.Vdp_SG_Detections_001_004_AL
              SEND_Pp_SG_Detections_005_008_AL_Vdp_SG_Detections_005_008_AL: accessed-variable=Pp_SG_Detections_005_008_AL.Vdp_SG_Detections_005_008_AL
              SEND_Pp_SG_Detections_009_012_AL_Vdp_SG_Detections_009_012_AL: accessed-variable=Pp_SG_Detections_009_012_AL.Vdp_SG_Detections_009_012_AL
              SEND_Pp_SG_Detections_013_016_AL_Vdp_SG_Detections_013_016_AL: accessed-variable=Pp_SG_Detections_013_016_AL.Vdp_SG_Detections_013_016_AL
              SEND_Pp_SG_Detections_017_020_AL_Vdp_SG_Detections_017_020_AL: accessed-variable=Pp_SG_Detections_017_020_AL.Vdp_SG_Detections_017_020_AL
              SEND_Pp_SG_Detections_021_024_AL_Vdp_SG_Detections_021_024_AL: accessed-variable=Pp_SG_Detections_021_024_AL.Vdp_SG_Detections_021_024_AL
              SEND_Pp_SG_Detections_025_028_AL_Vdp_SG_Detections_025_028_AL: accessed-variable=Pp_SG_Detections_025_028_AL.Vdp_SG_Detections_025_028_AL
              SEND_Pp_SG_Detections_029_032_AL_Vdp_SG_Detections_029_032_AL: accessed-variable=Pp_SG_Detections_029_032_AL.Vdp_SG_Detections_029_032_AL
              SEND_Pp_SG_Detections_033_036_AL_Vdp_SG_Detections_033_036_AL: accessed-variable=Pp_SG_Detections_033_036_AL.Vdp_SG_Detections_033_036_AL
              SEND_Pp_SG_Detections_037_040_AL_Vdp_SG_Detections_037_040_AL: accessed-variable=Pp_SG_Detections_037_040_AL.Vdp_SG_Detections_037_040_AL
              SEND_Pp_SG_Detections_041_044_AL_Vdp_SG_Detections_041_044_AL: accessed-variable=Pp_SG_Detections_041_044_AL.Vdp_SG_Detections_041_044_AL
              SEND_Pp_SG_Detections_045_048_AL_Vdp_SG_Detections_045_048_AL: accessed-variable=Pp_SG_Detections_045_048_AL.Vdp_SG_Detections_045_048_AL
              SEND_Pp_SG_Detections_049_052_AL_Vdp_SG_Detections_049_052_AL: accessed-variable=Pp_SG_Detections_049_052_AL.Vdp_SG_Detections_049_052_AL
              SEND_Pp_SG_Detections_053_056_AL_Vdp_SG_Detections_053_056_AL: accessed-variable=Pp_SG_Detections_053_056_AL.Vdp_SG_Detections_053_056_AL
              SEND_Pp_SG_Detections_057_060_AL_Vdp_SG_Detections_057_060_AL: accessed-variable=Pp_SG_Detections_057_060_AL.Vdp_SG_Detections_057_060_AL
              SEND_Pp_SG_Detections_061_064_AL_Vdp_SG_Detections_061_064_AL: accessed-variable=Pp_SG_Detections_061_064_AL.Vdp_SG_Detections_061_064_AL
              SEND_Pp_SG_Detections_065_068_AL_Vdp_SG_Detections_065_068_AL: accessed-variable=Pp_SG_Detections_065_068_AL.Vdp_SG_Detections_065_068_AL
              SEND_Pp_SG_Detections_069_072_AL_Vdp_SG_Detections_069_072_AL: accessed-variable=Pp_SG_Detections_069_072_AL.Vdp_SG_Detections_069_072_AL
              SEND_Pp_SG_Detections_073_076_AL_Vdp_SG_Detections_073_076_AL: accessed-variable=Pp_SG_Detections_073_076_AL.Vdp_SG_Detections_073_076_AL
              SEND_Pp_SG_Detections_077_080_AL_Vdp_SG_Detections_077_080_AL: accessed-variable=Pp_SG_Detections_077_080_AL.Vdp_SG_Detections_077_080_AL
              SEND_Pp_SG_Detections_081_084_AL_Vdp_SG_Detections_081_084_AL: accessed-variable=Pp_SG_Detections_081_084_AL.Vdp_SG_Detections_081_084_AL
              SEND_Pp_SG_Detections_085_088_AL_Vdp_SG_Detections_085_088_AL: accessed-variable=Pp_SG_Detections_085_088_AL.Vdp_SG_Detections_085_088_AL
              SEND_Pp_SG_Detections_089_092_AL_Vdp_SG_Detections_089_092_AL: accessed-variable=Pp_SG_Detections_089_092_AL.Vdp_SG_Detections_089_092_AL
              SEND_Pp_SG_Detections_093_096_AL_Vdp_SG_Detections_093_096_AL: accessed-variable=Pp_SG_Detections_093_096_AL.Vdp_SG_Detections_093_096_AL
              SEND_Pp_SG_Detections_097_100_AL_Vdp_SG_Detections_097_100_AL: accessed-variable=Pp_SG_Detections_097_100_AL.Vdp_SG_Detections_097_100_AL
              SEND_Pp_SG_Detections_101_104_AL_Vdp_SG_Detections_101_104_AL: accessed-variable=Pp_SG_Detections_101_104_AL.Vdp_SG_Detections_101_104_AL
              SEND_Pp_SG_Detections_105_108_AL_Vdp_SG_Detections_105_108_AL: accessed-variable=Pp_SG_Detections_105_108_AL.Vdp_SG_Detections_105_108_AL
              SEND_Pp_SG_Detections_109_112_AL_Vdp_SG_Detections_109_112_AL: accessed-variable=Pp_SG_Detections_109_112_AL.Vdp_SG_Detections_109_112_AL
              SEND_Pp_SG_Detections_113_116_AL_Vdp_SG_Detections_113_116_AL: accessed-variable=Pp_SG_Detections_113_116_AL.Vdp_SG_Detections_113_116_AL
              SEND_Pp_SG_Detections_117_120_AL_Vdp_SG_Detections_117_120_AL: accessed-variable=Pp_SG_Detections_117_120_AL.Vdp_SG_Detections_117_120_AL
              SEND_Pp_SG_Detections_121_124_AL_Vdp_SG_Detections_121_124_AL: accessed-variable=Pp_SG_Detections_121_124_AL.Vdp_SG_Detections_121_124_AL
              SEND_Pp_SG_Detections_125_128_AL_Vdp_SG_Detections_125_128_AL: accessed-variable=Pp_SG_Detections_125_128_AL.Vdp_SG_Detections_125_128_AL
              SEND_Pp_SG_Detections_129_132_AL_Vdp_SG_Detections_129_132_AL: accessed-variable=Pp_SG_Detections_129_132_AL.Vdp_SG_Detections_129_132_AL
              SEND_Pp_SG_Detections_133_136_AL_Vdp_SG_Detections_133_136_AL: accessed-variable=Pp_SG_Detections_133_136_AL.Vdp_SG_Detections_133_136_AL
              SEND_Pp_SG_Detections_137_140_AL_Vdp_SG_Detections_137_140_AL: accessed-variable=Pp_SG_Detections_137_140_AL.Vdp_SG_Detections_137_140_AL
              SEND_Pp_SG_Detections_141_144_AL_Vdp_SG_Detections_141_144_AL: accessed-variable=Pp_SG_Detections_141_144_AL.Vdp_SG_Detections_141_144_AL
              SEND_Pp_SG_Detections_145_148_AL_Vdp_SG_Detections_145_148_AL: accessed-variable=Pp_SG_Detections_145_148_AL.Vdp_SG_Detections_145_148_AL
              SEND_Pp_SG_Detections_149_152_AL_Vdp_SG_Detections_149_152_AL: accessed-variable=Pp_SG_Detections_149_152_AL.Vdp_SG_Detections_149_152_AL
              SEND_Pp_SG_Detections_153_156_AL_Vdp_SG_Detections_153_156_AL: accessed-variable=Pp_SG_Detections_153_156_AL.Vdp_SG_Detections_153_156_AL
              SEND_Pp_SG_Detections_157_160_AL_Vdp_SG_Detections_157_160_AL: accessed-variable=Pp_SG_Detections_157_160_AL.Vdp_SG_Detections_157_160_AL
              SEND_Pp_SG_Detections_161_164_AL_Vdp_SG_Detections_161_164_AL: accessed-variable=Pp_SG_Detections_161_164_AL.Vdp_SG_Detections_161_164_AL
              SEND_Pp_SG_Detections_165_168_AL_Vdp_SG_Detections_165_168_AL: accessed-variable=Pp_SG_Detections_165_168_AL.Vdp_SG_Detections_165_168_AL
              SEND_Pp_SG_Detections_169_172_AL_Vdp_SG_Detections_169_172_AL: accessed-variable=Pp_SG_Detections_169_172_AL.Vdp_SG_Detections_169_172_AL
              SEND_Pp_SG_Detections_173_176_AL_Vdp_SG_Detections_173_176_AL: accessed-variable=Pp_SG_Detections_173_176_AL.Vdp_SG_Detections_173_176_AL
              SEND_Pp_SG_Detections_177_180_AL_Vdp_SG_Detections_177_180_AL: accessed-variable=Pp_SG_Detections_177_180_AL.Vdp_SG_Detections_177_180_AL
              SEND_Pp_SG_Detections_181_184_AL_Vdp_SG_Detections_181_184_AL: accessed-variable=Pp_SG_Detections_181_184_AL.Vdp_SG_Detections_181_184_AL
              SEND_Pp_SG_Detections_185_188_AL_Vdp_SG_Detections_185_188_AL: accessed-variable=Pp_SG_Detections_185_188_AL.Vdp_SG_Detections_185_188_AL
              SEND_Pp_SG_Detections_189_192_AL_Vdp_SG_Detections_189_192_AL: accessed-variable=Pp_SG_Detections_189_192_AL.Vdp_SG_Detections_189_192_AL
              SEND_Pp_SG_Detections_193_196_AL_Vdp_SG_Detections_193_196_AL: accessed-variable=Pp_SG_Detections_193_196_AL.Vdp_SG_Detections_193_196_AL
              SEND_Pp_SG_Detections_197_200_AL_Vdp_SG_Detections_197_200_AL: accessed-variable=Pp_SG_Detections_197_200_AL.Vdp_SG_Detections_197_200_AL
              SEND_Pp_SG_Detections_201_204_AL_Vdp_SG_Detections_201_204_AL: accessed-variable=Pp_SG_Detections_201_204_AL.Vdp_SG_Detections_201_204_AL
              SEND_Pp_SG_Detections_205_208_AL_Vdp_SG_Detections_205_208_AL: accessed-variable=Pp_SG_Detections_205_208_AL.Vdp_SG_Detections_205_208_AL
              SEND_Pp_SG_Detections_209_212_AL_Vdp_SG_Detections_209_212_AL: accessed-variable=Pp_SG_Detections_209_212_AL.Vdp_SG_Detections_209_212_AL
              SEND_Pp_SG_Detections_213_216_AL_Vdp_SG_Detections_213_216_AL: accessed-variable=Pp_SG_Detections_213_216_AL.Vdp_SG_Detections_213_216_AL
              SEND_Pp_SG_Detections_217_220_AL_Vdp_SG_Detections_217_220_AL: accessed-variable=Pp_SG_Detections_217_220_AL.Vdp_SG_Detections_217_220_AL
              SEND_Pp_SG_Detections_221_224_AL_Vdp_SG_Detections_221_224_AL: accessed-variable=Pp_SG_Detections_221_224_AL.Vdp_SG_Detections_221_224_AL
              SEND_Pp_SG_Detections_225_228_AL_Vdp_SG_Detections_225_228_AL: accessed-variable=Pp_SG_Detections_225_228_AL.Vdp_SG_Detections_225_228_AL
              SEND_Pp_SG_Detections_229_232_AL_Vdp_SG_Detections_229_232_AL: accessed-variable=Pp_SG_Detections_229_232_AL.Vdp_SG_Detections_229_232_AL
              SEND_Pp_SG_Detections_233_236_AL_Vdp_SG_Detections_233_236_AL: accessed-variable=Pp_SG_Detections_233_236_AL.Vdp_SG_Detections_233_236_AL
              SEND_Pp_SG_Detections_237_240_AL_Vdp_SG_Detections_237_240_AL: accessed-variable=Pp_SG_Detections_237_240_AL.Vdp_SG_Detections_237_240_AL
              SEND_Pp_SG_Detections_241_244_AL_Vdp_SG_Detections_241_244_AL: accessed-variable=Pp_SG_Detections_241_244_AL.Vdp_SG_Detections_241_244_AL
              SEND_Pp_SG_Detections_245_248_AL_Vdp_SG_Detections_245_248_AL: accessed-variable=Pp_SG_Detections_245_248_AL.Vdp_SG_Detections_245_248_AL
              SEND_Pp_SG_Detections_249_252_AL_Vdp_SG_Detections_249_252_AL: accessed-variable=Pp_SG_Detections_249_252_AL.Vdp_SG_Detections_249_252_AL
              SEND_Pp_SG_Detections_253_256_AL_Vdp_SG_Detections_253_256_AL: accessed-variable=Pp_SG_Detections_253_256_AL.Vdp_SG_Detections_253_256_AL
              SEND_Pp_SG_Detections_257_260_AL_Vdp_SG_Detections_257_260_AL: accessed-variable=Pp_SG_Detections_257_260_AL.Vdp_SG_Detections_257_260_AL
              SEND_Pp_SG_Detections_261_264_AL_Vdp_SG_Detections_261_264_AL: accessed-variable=Pp_SG_Detections_261_264_AL.Vdp_SG_Detections_261_264_AL
              SEND_Pp_SG_Detections_265_268_AL_Vdp_SG_Detections_265_268_AL: accessed-variable=Pp_SG_Detections_265_268_AL.Vdp_SG_Detections_265_268_AL
              SEND_Pp_SG_Detections_269_272_AL_Vdp_SG_Detections_269_272_AL: accessed-variable=Pp_SG_Detections_269_272_AL.Vdp_SG_Detections_269_272_AL
              SEND_Pp_SG_Detections_273_276_AL_Vdp_SG_Detections_273_276_AL: accessed-variable=Pp_SG_Detections_273_276_AL.Vdp_SG_Detections_273_276_AL
              SEND_Pp_SG_Detections_277_280_AL_Vdp_SG_Detections_277_280_AL: accessed-variable=Pp_SG_Detections_277_280_AL.Vdp_SG_Detections_277_280_AL
              SEND_Pp_SG_Detections_281_284_AL_Vdp_SG_Detections_281_284_AL: accessed-variable=Pp_SG_Detections_281_284_AL.Vdp_SG_Detections_281_284_AL
              SEND_Pp_SG_Detections_285_288_AL_Vdp_SG_Detections_285_288_AL: accessed-variable=Pp_SG_Detections_285_288_AL.Vdp_SG_Detections_285_288_AL
              SEND_Pp_SG_Detections_289_292_AL_Vdp_SG_Detections_289_292_AL: accessed-variable=Pp_SG_Detections_289_292_AL.Vdp_SG_Detections_289_292_AL
              SEND_Pp_SG_Detections_293_296_AL_Vdp_SG_Detections_293_296_AL: accessed-variable=Pp_SG_Detections_293_296_AL.Vdp_SG_Detections_293_296_AL
              SEND_Pp_SG_Detections_297_300_AL_Vdp_SG_Detections_297_300_AL: accessed-variable=Pp_SG_Detections_297_300_AL.Vdp_SG_Detections_297_300_AL
              SEND_Pp_SG_Detections_301_304_AL_Vdp_SG_Detections_301_304_AL: accessed-variable=Pp_SG_Detections_301_304_AL.Vdp_SG_Detections_301_304_AL
              SEND_Pp_SG_Detections_305_308_AL_Vdp_SG_Detections_305_308_AL: accessed-variable=Pp_SG_Detections_305_308_AL.Vdp_SG_Detections_305_308_AL
              SEND_Pp_SG_Detections_309_312_AL_Vdp_SG_Detections_309_312_AL: accessed-variable=Pp_SG_Detections_309_312_AL.Vdp_SG_Detections_309_312_AL
              SEND_Pp_SG_Detections_313_316_AL_Vdp_SG_Detections_313_316_AL: accessed-variable=Pp_SG_Detections_313_316_AL.Vdp_SG_Detections_313_316_AL
              SEND_Pp_SG_Detections_317_320_AL_Vdp_SG_Detections_317_320_AL: accessed-variable=Pp_SG_Detections_317_320_AL.Vdp_SG_Detections_317_320_AL
              SEND_Pp_SG_Detections_321_324_AL_Vdp_SG_Detections_321_324_AL: accessed-variable=Pp_SG_Detections_321_324_AL.Vdp_SG_Detections_321_324_AL
              SEND_Pp_SG_Detections_325_328_AL_Vdp_SG_Detections_325_328_AL: accessed-variable=Pp_SG_Detections_325_328_AL.Vdp_SG_Detections_325_328_AL
              SEND_Pp_SG_Detections_329_332_AL_Vdp_SG_Detections_329_332_AL: accessed-variable=Pp_SG_Detections_329_332_AL.Vdp_SG_Detections_329_332_AL
              SEND_Pp_SG_Detections_333_336_AL_Vdp_SG_Detections_333_336_AL: accessed-variable=Pp_SG_Detections_333_336_AL.Vdp_SG_Detections_333_336_AL
              SEND_Pp_SG_Detections_337_340_AL_Vdp_SG_Detections_337_340_AL: accessed-variable=Pp_SG_Detections_337_340_AL.Vdp_SG_Detections_337_340_AL
              SEND_Pp_SG_Detections_341_344_AL_Vdp_SG_Detections_341_344_AL: accessed-variable=Pp_SG_Detections_341_344_AL.Vdp_SG_Detections_341_344_AL
              SEND_Pp_SG_Detections_345_348_AL_Vdp_SG_Detections_345_348_AL: accessed-variable=Pp_SG_Detections_345_348_AL.Vdp_SG_Detections_345_348_AL
              SEND_Pp_SG_Detections_349_352_AL_Vdp_SG_Detections_349_352_AL: accessed-variable=Pp_SG_Detections_349_352_AL.Vdp_SG_Detections_349_352_AL
              SEND_Pp_SG_Detections_353_356_AL_Vdp_SG_Detections_353_356_AL: accessed-variable=Pp_SG_Detections_353_356_AL.Vdp_SG_Detections_353_356_AL
              SEND_Pp_SG_Detections_357_360_AL_Vdp_SG_Detections_357_360_AL: accessed-variable=Pp_SG_Detections_357_360_AL.Vdp_SG_Detections_357_360_AL
              SEND_Pp_SG_Detections_361_364_AL_Vdp_SG_Detections_361_364_AL: accessed-variable=Pp_SG_Detections_361_364_AL.Vdp_SG_Detections_361_364_AL
              SEND_Pp_SG_Detections_365_368_AL_Vdp_SG_Detections_365_368_AL: accessed-variable=Pp_SG_Detections_365_368_AL.Vdp_SG_Detections_365_368_AL
              SEND_Pp_SG_Detections_369_372_AL_Vdp_SG_Detections_369_372_AL: accessed-variable=Pp_SG_Detections_369_372_AL.Vdp_SG_Detections_369_372_AL
              SEND_Pp_SG_Detections_373_376_AL_Vdp_SG_Detections_373_376_AL: accessed-variable=Pp_SG_Detections_373_376_AL.Vdp_SG_Detections_373_376_AL
              SEND_Pp_SG_Detections_377_380_AL_Vdp_SG_Detections_377_380_AL: accessed-variable=Pp_SG_Detections_377_380_AL.Vdp_SG_Detections_377_380_AL
              SEND_Pp_SG_Detections_381_384_AL_Vdp_SG_Detections_381_384_AL: accessed-variable=Pp_SG_Detections_381_384_AL.Vdp_SG_Detections_381_384_AL
              SEND_Pp_SG_Detections_385_388_AL_Vdp_SG_Detections_385_388_AL: accessed-variable=Pp_SG_Detections_385_388_AL.Vdp_SG_Detections_385_388_AL
              SEND_Pp_SG_Detections_389_392_AL_Vdp_SG_Detections_389_392_AL: accessed-variable=Pp_SG_Detections_389_392_AL.Vdp_SG_Detections_389_392_AL
              SEND_Pp_SG_Detections_393_396_AL_Vdp_SG_Detections_393_396_AL: accessed-variable=Pp_SG_Detections_393_396_AL.Vdp_SG_Detections_393_396_AL
              SEND_Pp_SG_Detections_397_400_AL_Vdp_SG_Detections_397_400_AL: accessed-variable=Pp_SG_Detections_397_400_AL.Vdp_SG_Detections_397_400_AL
              SEND_Pp_SG_RadarCapability_AL_Vdp_SG_RadarCapability_AL: accessed-variable=Pp_SG_RadarCapability_AL.Vdp_SG_RadarCapability_AL
              SEND_Pp_SG_RadarStatus2_AL_Vdp_SG_RadarStatus2_AL: accessed-variable=Pp_SG_RadarStatus2_AL.Vdp_SG_RadarStatus2_AL
              SEND_Pp_SG_XcpCTOResp_AL_Vdp_SG_XcpCTOResp_AL: accessed-variable=Pp_SG_XcpCTOResp_AL.Vdp_SG_XcpCTOResp_AL
              SEND_Pp_SG_XcpDAQResp_AL_Vdp_SG_XcpDAQResp_AL: accessed-variable=Pp_SG_XcpDAQResp_AL.Vdp_SG_XcpDAQResp_AL
              SEND_Pp_WarningRelevantObjectDetected_AL_Vdp_WarningRelevantObjectDetected_AL: accessed-variable=Pp_WarningRelevantObjectDetected_AL.Vdp_WarningRelevantObjectDetected_AL
              SEND_Pp_SG_GW_prop_ADAS_BSIS_info_ALPCAN_Vdp_SG_GW_prop_ADAS_BSIS_info_ALPCAN: accessed-variable=Pp_SG_GW_prop_ADAS_BSIS_info_ALPCAN.Vdp_SG_GW_prop_ADAS_BSIS_info_ALPCAN
              SEND_Pp_SG_MOIS_ALVCAN_Vdp_SG_MOIS_ALVCAN: accessed-variable=Pp_SG_MOIS_ALVCAN.Vdp_SG_MOIS_ALVCAN
              SEND_Pp_SG_RDR_BSD1_Tx_ALPCAN_Vdp_SG_RDR_BSD1_Tx_ALPCAN: accessed-variable=Pp_SG_RDR_BSD1_Tx_ALPCAN.Vdp_SG_RDR_BSD1_Tx_ALPCAN
              SEND_Pp_SG_RadarHeader_ALPCAN_Vdp_SG_RadarHeader_ALPCAN: accessed-variable=Pp_SG_RadarHeader_ALPCAN.Vdp_SG_RadarHeader_ALPCAN
              SEND_Pp_SG_RadarStatus1_ALPCAN_Vdp_SG_RadarStatus1_ALPCAN: accessed-variable=Pp_SG_RadarStatus1_ALPCAN.Vdp_SG_RadarStatus1_ALPCAN
              SEND_Pp_SG_prop_ADAS_MOIS_info_ALVCAN_Vdp_SG_prop_ADAS_MOIS_info_ALVCAN: accessed-variable=Pp_SG_prop_ADAS_MOIS_info_ALVCAN.Vdp_SG_prop_ADAS_MOIS_info_ALVCAN
              SEND_Pp_Alignment_Status_1_Com_Rx_Timeout_Status_De_Com_Rx_Timeout_Status: accessed-variable=Pp_Alignment_Status_1_Com_Rx_Timeout_Status.De_Com_Rx_Timeout_Status
              SEND_Pp_Header_msg_Com_Rx_Timeout_Status_De_Com_Rx_Timeout_Status: accessed-variable=Pp_Header_msg_Com_Rx_Timeout_Status.De_Com_Rx_Timeout_Status
              SEND_Pp_Radar_Capability_Com_Rx_Timeout_Status_De_Com_Rx_Timeout_Status: accessed-variable=Pp_Radar_Capability_Com_Rx_Timeout_Status.De_Com_Rx_Timeout_Status
              SEND_Pp_Radar_Status_1_Com_Rx_Timeout_Status_De_Com_Rx_Timeout_Status: accessed-variable=Pp_Radar_Status_1_Com_Rx_Timeout_Status.De_Com_Rx_Timeout_Status
              SEND_Pp_Radar_Status_2_Com_Rx_Timeout_Status_De_Com_Rx_Timeout_Status: accessed-variable=Pp_Radar_Status_2_Com_Rx_Timeout_Status.De_Com_Rx_Timeout_Status
              SEND_Pp_CCVS1_message_Vcan_Safety_Timeout_Status_De_Com_Rx_Vcan_Timeout_Status: accessed-variable=Pp_CCVS1_message_Vcan_Safety_Timeout_Status.De_Com_Rx_Vcan_Timeout_Status
              SEND_Pp_ETC2_AT_AMT_message_Vcan_Safety_Timeout_Status_De_Com_Rx_Vcan_Timeout_Status: accessed-variable=Pp_ETC2_AT_AMT_message_Vcan_Safety_Timeout_Status.De_Com_Rx_Vcan_Timeout_Status
              SEND_Pp_ETC2_MT_Variant_message_Vcan_Safety_Timeout_Status_De_Com_Rx_Vcan_Timeout_Status: accessed-variable=Pp_ETC2_MT_Variant_message_Vcan_Safety_Timeout_Status.De_Com_Rx_Vcan_Timeout_Status
              SEND_Pp_VDC2_message_Vcan_Safety_Timeout_Status_De_Com_Rx_Vcan_Timeout_Status: accessed-variable=Pp_VDC2_message_Vcan_Safety_Timeout_Status.De_Com_Rx_Vcan_Timeout_Status
              SEND_Pp_ADAS_Function_Switch_message_Non_Safety_Timeout_Status_De_Com_Rx_Vcan_Non_Safety_Timeout_Status: accessed-variable=Pp_ADAS_Function_Switch_message_Non_Safety_Timeout_Status.De_Com_Rx_Vcan_Non_Safety_Timeout_Status
              SEND_Pp_OEL_message_Non_Safety_Timeout_Status_De_Com_Rx_Vcan_Non_Safety_Timeout_Status: accessed-variable=Pp_OEL_message_Non_Safety_Timeout_Status.De_Com_Rx_Vcan_Non_Safety_Timeout_Status
              SEND_Pp_SAS_LCV_message_Non_Safety_Timeout_Status_De_Com_Rx_Vcan_Non_Safety_Timeout_Status: accessed-variable=Pp_SAS_message_Non_Safety_Timeout_Status.De_Com_Rx_Vcan_Non_Safety_Timeout_Status
              SEND_Pp_TD_message_Non_Safety_Timeout_Status_De_Com_Rx_Vcan_Non_Safety_Timeout_Status: accessed-variable=Pp_TD_message_Non_Safety_Timeout_Status.De_Com_Rx_Vcan_Non_Safety_Timeout_Status
              SEND_Pp_CLS_TX_16_message_Non_Safety_Timeout_Status_De_Com_Rx_Vcan_Non_Safety_Timeout_Status: accessed-variable=Pp_CLS_TX_16_message_Non_Safety_Timeout_Status.De_Com_Rx_Vcan_Non_Safety_Timeout_Status
              SEND_Pp_CLS_TX_4_message_Non_Safety_Timeout_Status_De_Com_Rx_Vcan_Non_Safety_Timeout_Status: accessed-variable=Pp_CLS_TX_4_message_Non_Safety_Timeout_Status.De_Com_Rx_Vcan_Non_Safety_Timeout_Status
              SEND_Pp_VD_message_Non_Safety_Timeout_Status_De_Com_Rx_Vcan_Non_Safety_Timeout_Status: accessed-variable=Pp_VD_message_Non_Safety_Timeout_Status.De_Com_Rx_Vcan_Non_Safety_Timeout_Status
              SEND_Pp_SG_VehicleStatus_AL_Vdp_SG_VehicleStatus_AL: accessed-variable=Pp_SG_VehicleStatus_AL.Vdp_SG_VehicleStatus_AL
              SEND_Pp_VSE_NVM_Params_De_VSE_NVM_Params: accessed-variable=Pp_VSE_NVM_Params.De_VSE_NVM_Params
              SEND_Pp_Pcan_Communication_ETE_fault_De_Communication_ETE_fault: accessed-variable=Pp_Pcan_Communication_ETE_fault.De_Communication_ETE_fault
          mode-access-points:
            Switch_SDC_Mode_C_consService_RDR_1_ADAS_Vehicle_Status_2b1e055b.BswM_MDGP_SDC_SdClientServiceState
            Switch_SDC_Mode_C_consService_RDR_1_ADAS_Vehicle_Status_2b1e055b_CEG_consServiceGrp_RDR_1_ADAS_Vehicle_Status_4b79da85.BswM_MDGP_SDC_SdConsumedEventGroupState
            Switch_SDC_Mode_S_provService_RDR_1_Detections_89f78c9f_EH_EventGroup_RDR_1_ca62382d.BswM_MDGP_SDC_SdEventHandlerState
            Switch_SDC_Mode_S_provService_RDR_1_SW_Info_c2745ec9_EH_EventGroup_RDR_1_653e2581.BswM_MDGP_SDC_SdEventHandlerState
            Switch_SDC_Mode_S_provService_RDR_1_Status_d2069d01_EH_EventGroup_RDR_1_f7c73cae.BswM_MDGP_SDC_SdEventHandlerState
        RE_Communication_Rx
          data-receive-point-by-arguments:
            79 x access:
              REC_RP_RDR_Vehicle_Status_Vehicle_Status: accessed-variable=RP_RDR_Vehicle_Status.Vehicle_Status
              REC_Rp_TSYNC_CRC_Vdp_TSYNC_CRC: accessed-variable=Rp_TSYNC_CRC.Vdp_TSYNC_CRC
              REC_Rp_TSYN_OVS_Vdp_TSYN_OVS: accessed-variable=Rp_TSYN_OVS.Vdp_TSYN_OVS
              REC_Rp_TSYN_PDU_Vdp_TSYN_PDU: accessed-variable=Rp_TSYN_PDU.Vdp_TSYN_PDU
              REC_Rp_TSYN_RESERVED_Vdp_TSYN_RESERVED: accessed-variable=Rp_TSYN_RESERVED.Vdp_TSYN_RESERVED
              REC_Rp_TSYN_SEQUENCE_COUNTER_Vdp_TSYN_SEQUENCE_COUNTER: accessed-variable=Rp_TSYN_SEQUENCE_COUNTER.Vdp_TSYN_SEQUENCE_COUNTER
              REC_Rp_TSYN_SGW_Vdp_TSYN_SGW: accessed-variable=Rp_TSYN_SGW.Vdp_TSYN_SGW
              REC_Rp_TSYN_SYNCTIME_NANOSEC_Vdp_TSYN_SYNCTIME_NANOSEC: accessed-variable=Rp_TSYN_SYNCTIME_NANOSEC.Vdp_TSYN_SYNCTIME_NANOSEC
              REC_Rp_TSYN_SYNCTIME_SEC_Vdp_TSYN_SYNCTIME_SEC: accessed-variable=Rp_TSYN_SYNCTIME_SEC.Vdp_TSYN_SYNCTIME_SEC
              REC_Rp_TSYN_TIMEDOMAIN_Vdp_TSYN_TIMEDOMAIN: accessed-variable=Rp_TSYN_TIMEDOMAIN.Vdp_TSYN_TIMEDOMAIN
              REC_Rp_TSYN_USERBYTE_Vdp_TSYN_USERBYTE: accessed-variable=Rp_TSYN_USERBYTE.Vdp_TSYN_USERBYTE
              REC_Rp_SG_Fusion_Detections_001_004_AL_Vdp_SG_Fusion_Detections_001_004_AL: accessed-variable=Rp_SG_Fusion_Detections_001_004_AL.Vdp_SG_Fusion_Detections_001_004_AL
              REC_Rp_SG_Fusion_Detections_005_008_AL_Vdp_SG_Fusion_Detections_005_008_AL: accessed-variable=Rp_SG_Fusion_Detections_005_008_AL.Vdp_SG_Fusion_Detections_005_008_AL
              REC_Rp_SG_Fusion_Detections_009_012_AL_Vdp_SG_Fusion_Detections_009_012_AL: accessed-variable=Rp_SG_Fusion_Detections_009_012_AL.Vdp_SG_Fusion_Detections_009_012_AL
              REC_Rp_SG_Fusion_Detections_013_016_AL_Vdp_SG_Fusion_Detections_013_016_AL: accessed-variable=Rp_SG_Fusion_Detections_013_016_AL.Vdp_SG_Fusion_Detections_013_016_AL
              REC_Rp_SG_Fusion_Detections_017_020_AL_Vdp_SG_Fusion_Detections_017_020_AL: accessed-variable=Rp_SG_Fusion_Detections_017_020_AL.Vdp_SG_Fusion_Detections_017_020_AL
              REC_Rp_SG_Fusion_Detections_021_024_AL_Vdp_SG_Fusion_Detections_021_024_AL: accessed-variable=Rp_SG_Fusion_Detections_021_024_AL.Vdp_SG_Fusion_Detections_021_024_AL
              REC_Rp_SG_Fusion_Detections_025_028_AL_Vdp_SG_Fusion_Detections_025_028_AL: accessed-variable=Rp_SG_Fusion_Detections_025_028_AL.Vdp_SG_Fusion_Detections_025_028_AL
              REC_Rp_SG_Fusion_Detections_029_032_AL_Vdp_SG_Fusion_Detections_029_032_AL: accessed-variable=Rp_SG_Fusion_Detections_029_032_AL.Vdp_SG_Fusion_Detections_029_032_AL
              REC_Rp_SG_Fusion_Detections_033_036_AL_Vdp_SG_Fusion_Detections_033_036_AL: accessed-variable=Rp_SG_Fusion_Detections_033_036_AL.Vdp_SG_Fusion_Detections_033_036_AL
              REC_Rp_SG_Fusion_Detections_037_040_AL_Vdp_SG_Fusion_Detections_037_040_AL: accessed-variable=Rp_SG_Fusion_Detections_037_040_AL.Vdp_SG_Fusion_Detections_037_040_AL
              REC_Rp_SG_Fusion_Detections_041_044_AL_Vdp_SG_Fusion_Detections_041_044_AL: accessed-variable=Rp_SG_Fusion_Detections_041_044_AL.Vdp_SG_Fusion_Detections_041_044_AL
              REC_Rp_SG_Fusion_Detections_045_048_AL_Vdp_SG_Fusion_Detections_045_048_AL: accessed-variable=Rp_SG_Fusion_Detections_045_048_AL.Vdp_SG_Fusion_Detections_045_048_AL
              REC_Rp_SG_Fusion_Detections_049_052_AL_Vdp_SG_Fusion_Detections_049_052_AL: accessed-variable=Rp_SG_Fusion_Detections_049_052_AL.Vdp_SG_Fusion_Detections_049_052_AL
              REC_Rp_SG_Fusion_Detections_053_056_AL_Vdp_SG_Fusion_Detections_053_056_AL: accessed-variable=Rp_SG_Fusion_Detections_053_056_AL.Vdp_SG_Fusion_Detections_053_056_AL
              REC_Rp_SG_Fusion_Detections_057_060_AL_Vdp_SG_Fusion_Detections_057_060_AL: accessed-variable=Rp_SG_Fusion_Detections_057_060_AL.Vdp_SG_Fusion_Detections_057_060_AL
              REC_Rp_SG_Fusion_Detections_061_064_AL_Vdp_SG_Fusion_Detections_061_064_AL: accessed-variable=Rp_SG_Fusion_Detections_061_064_AL.Vdp_SG_Fusion_Detections_061_064_AL
              REC_Rp_SG_Fusion_Detections_065_068_AL_Vdp_SG_Fusion_Detections_065_068_AL: accessed-variable=Rp_SG_Fusion_Detections_065_068_AL.Vdp_SG_Fusion_Detections_065_068_AL
              REC_Rp_SG_Fusion_Detections_069_072_AL_Vdp_SG_Fusion_Detections_069_072_AL: accessed-variable=Rp_SG_Fusion_Detections_069_072_AL.Vdp_SG_Fusion_Detections_069_072_AL
              REC_Rp_SG_Fusion_Detections_073_076_AL_Vdp_SG_Fusion_Detections_073_076_AL: accessed-variable=Rp_SG_Fusion_Detections_073_076_AL.Vdp_SG_Fusion_Detections_073_076_AL
              REC_Rp_SG_Fusion_Detections_077_080_AL_Vdp_SG_Fusion_Detections_077_080_AL: accessed-variable=Rp_SG_Fusion_Detections_077_080_AL.Vdp_SG_Fusion_Detections_077_080_AL
              REC_Rp_SG_Fusion_Detections_081_084_AL_Vdp_SG_Fusion_Detections_081_084_AL: accessed-variable=Rp_SG_Fusion_Detections_081_084_AL.Vdp_SG_Fusion_Detections_081_084_AL
              REC_Rp_SG_Fusion_Detections_085_088_AL_Vdp_SG_Fusion_Detections_085_088_AL: accessed-variable=Rp_SG_Fusion_Detections_085_088_AL.Vdp_SG_Fusion_Detections_085_088_AL
              REC_Rp_SG_Fusion_Detections_089_092_AL_Vdp_SG_Fusion_Detections_089_092_AL: accessed-variable=Rp_SG_Fusion_Detections_089_092_AL.Vdp_SG_Fusion_Detections_089_092_AL
              REC_Rp_SG_Fusion_Detections_093_096_AL_Vdp_SG_Fusion_Detections_093_096_AL: accessed-variable=Rp_SG_Fusion_Detections_093_096_AL.Vdp_SG_Fusion_Detections_093_096_AL
              REC_Rp_SG_Fusion_Detections_097_100_AL_Vdp_SG_Fusion_Detections_097_100_AL: accessed-variable=Rp_SG_Fusion_Detections_097_100_AL.Vdp_SG_Fusion_Detections_097_100_AL
              REC_Rp_SG_Fusion_Detections_101_104_AL_Vdp_SG_Fusion_Detections_101_104_AL: accessed-variable=Rp_SG_Fusion_Detections_101_104_AL.Vdp_SG_Fusion_Detections_101_104_AL
              REC_Rp_SG_Fusion_Detections_105_108_AL_Vdp_SG_Fusion_Detections_105_108_AL: accessed-variable=Rp_SG_Fusion_Detections_105_108_AL.Vdp_SG_Fusion_Detections_105_108_AL
              REC_Rp_SG_Fusion_Detections_109_112_AL_Vdp_SG_Fusion_Detections_109_112_AL: accessed-variable=Rp_SG_Fusion_Detections_109_112_AL.Vdp_SG_Fusion_Detections_109_112_AL
              REC_Rp_SG_Fusion_Detections_113_116_AL_Vdp_SG_Fusion_Detections_113_116_AL: accessed-variable=Rp_SG_Fusion_Detections_113_116_AL.Vdp_SG_Fusion_Detections_113_116_AL
              REC_Rp_SG_Fusion_Detections_117_120_AL_Vdp_SG_Fusion_Detections_117_120_AL: accessed-variable=Rp_SG_Fusion_Detections_117_120_AL.Vdp_SG_Fusion_Detections_117_120_AL
              REC_Rp_SG_Fusion_Detections_121_124_AL_Vdp_SG_Fusion_Detections_121_124_AL: accessed-variable=Rp_SG_Fusion_Detections_121_124_AL.Vdp_SG_Fusion_Detections_121_124_AL
              REC_Rp_SG_Fusion_Detections_125_128_AL_Vdp_SG_Fusion_Detections_125_128_AL: accessed-variable=Rp_SG_Fusion_Detections_125_128_AL.Vdp_SG_Fusion_Detections_125_128_AL
              REC_Rp_SG_VehicleStatus_AL_Vdp_SG_VehicleStatus_AL: accessed-variable=Rp_SG_VehicleStatus_AL.Vdp_SG_VehicleStatus_AL
              REC_Rp_SG_XcpCTOReq_AL_Vdp_SG_XcpCTOReq_AL: accessed-variable=Rp_SG_XcpCTOReq_AL.Vdp_SG_XcpCTOReq_AL
              REC_Rp_TimeSync_Status_No_Tsyn_Error_De_STS_No_TSyn_Error: accessed-variable=Rp_TimeSync_Status_No_Tsyn_Error.De_STS_No_TSyn_Error
              REC_Rp_Time_Stamp_Delta_De_Time_Stamp_Delta: accessed-variable=Rp_Time_Stamp_Delta.De_Time_Stamp_Delta
              REC_Rp_Vbatt_State_De_Vbatt_State: accessed-variable=Rp_Vbatt_State.De_Vbatt_State
              REC_Rp_OperationMode_System_De_OperationMode_System: accessed-variable=Rp_OperationMode_System.De_OperationMode_System
              REC_Rp_SG_ADAS_FN_Enable_disable_sts_ALVCAN_Vdp_SG_ADAS_FN_Enable_disable_sts_ALVCAN: accessed-variable=Rp_SG_ADAS_FN_Enable_disable_sts_ALVCAN.Vdp_SG_ADAS_FN_Enable_disable_sts_ALVCAN
              REC_Rp_SG_CCVS1_ALVCAN_Vdp_SG_CCVS1_ALVCAN: accessed-variable=Rp_SG_CCVS1_ALVCAN.Vdp_SG_CCVS1_ALVCAN
              REC_Rp_SG_CLS_Tx_16_ALVCAN_Vdp_SG_CLS_Tx_16_ALVCAN: accessed-variable=Rp_SG_CLS_Tx_16_ALVCAN.Vdp_SG_CLS_Tx_16_ALVCAN
              REC_Rp_SG_CLS_Tx_4_ALVCAN_Vdp_SG_CLS_Tx_4_ALVCAN: accessed-variable=Rp_SG_CLS_Tx_4_ALVCAN.Vdp_SG_CLS_Tx_4_ALVCAN
              REC_Rp_SG_ETC2_00_ALVCAN_Vdp_SG_ETC2_00_ALVCAN: accessed-variable=Rp_SG_ETC2_00_ALVCAN.Vdp_SG_ETC2_00_ALVCAN
              REC_Rp_SG_ETC2_03_ALVCAN_Vdp_SG_ETC2_03_ALVCAN: accessed-variable=Rp_SG_ETC2_03_ALVCAN.Vdp_SG_ETC2_03_ALVCAN
              REC_Rp_SG_Fusion_AlignmentStatus1_ALPCAN_Vdp_SG_Fusion_AlignmentStatus1_ALPCAN: accessed-variable=Rp_SG_Fusion_AlignmentStatus1_ALPCAN.Vdp_SG_Fusion_AlignmentStatus1_ALPCAN
              REC_Rp_SG_Fusion_AlignmentStatus2_ALPCAN_Vdp_SG_Fusion_AlignmentStatus2_ALPCAN: accessed-variable=Rp_SG_Fusion_AlignmentStatus2_ALPCAN.Vdp_SG_Fusion_AlignmentStatus2_ALPCAN
              REC_Rp_SG_Fusion_RadarCapability_ALPCAN_Vdp_SG_Fusion_RadarCapability_ALPCAN: accessed-variable=Rp_SG_Fusion_RadarCapability_ALPCAN.Vdp_SG_Fusion_RadarCapability_ALPCAN
              REC_Rp_SG_Fusion_RadarHeader_ALPCAN_Vdp_SG_Fusion_RadarHeader_ALPCAN: accessed-variable=Rp_SG_Fusion_RadarHeader_ALPCAN.Vdp_SG_Fusion_RadarHeader_ALPCAN
              REC_Rp_SG_Fusion_RadarStatus2_ALPCAN_Vdp_SG_Fusion_RadarStatus2_ALPCAN: accessed-variable=Rp_SG_Fusion_RadarStatus2_ALPCAN.Vdp_SG_Fusion_RadarStatus2_ALPCAN
              REC_Rp_SG_Fusion_RadarStatus_ALPCAN_Vdp_SG_Fusion_RadarStatus_ALPCAN: accessed-variable=Rp_SG_Fusion_RadarStatus_ALPCAN.Vdp_SG_Fusion_RadarStatus_ALPCAN
              REC_Rp_SG_GW_ADAS_FN_Enable_disable_sts_ALPCAN_Vdp_SG_GW_ADAS_FN_Enable_disable_sts_ALPCAN: accessed-variable=Rp_SG_GW_ADAS_FN_Enable_disable_sts_ALPCAN.Vdp_SG_GW_ADAS_FN_Enable_disable_sts_ALPCAN
              REC_Rp_SG_GW_CCVS1_ALPCAN_Vdp_SG_GW_CCVS1_ALPCAN: accessed-variable=Rp_SG_GW_CCVS1_ALPCAN.Vdp_SG_GW_CCVS1_ALPCAN
              REC_Rp_SG_GW_CLS_Tx_16_ALPCAN_Vdp_SG_GW_CLS_Tx_16_ALPCAN: accessed-variable=Rp_SG_GW_CLS_Tx_16_ALPCAN.Vdp_SG_GW_CLS_Tx_16_ALPCAN
              REC_Rp_SG_GW_CLS_Tx_4_ALPCAN_Vdp_SG_GW_CLS_Tx_4_ALPCAN: accessed-variable=Rp_SG_GW_CLS_Tx_4_ALPCAN.Vdp_SG_GW_CLS_Tx_4_ALPCAN
              REC_Rp_SG_GW_ETC2_03_ALPCAN_Vdp_SG_GW_ETC2_03_ALPCAN: accessed-variable=Rp_SG_GW_ETC2_03_ALPCAN.Vdp_SG_GW_ETC2_03_ALPCAN
              REC_Rp_SG_GW_ETC2_ALPCAN_Vdp_SG_GW_ETC2_ALPCAN: accessed-variable=Rp_SG_GW_ETC2_ALPCAN.Vdp_SG_GW_ETC2_ALPCAN
              REC_Rp_SG_GW_OEL_ALPCAN_Vdp_SG_GW_OEL_ALPCAN: accessed-variable=Rp_SG_GW_OEL_ALPCAN.Vdp_SG_GW_OEL_ALPCAN
              REC_Rp_SG_GW_SAS_ALPCAN_Vdp_SG_GW_SAS_ALPCAN: accessed-variable=Rp_SG_GW_SAS_ALPCAN.Vdp_SG_GW_SAS_ALPCAN
              REC_Rp_SG_GW_TD_ALPCAN_Vdp_SG_GW_TD_ALPCAN: accessed-variable=Rp_SG_GW_TD_ALPCAN.Vdp_SG_GW_TD_ALPCAN
              REC_Rp_SG_GW_VDC2_ALPCAN_Vdp_SG_GW_VDC2_ALPCAN: accessed-variable=Rp_SG_GW_VDC2_ALPCAN.Vdp_SG_GW_VDC2_ALPCAN
              REC_Rp_SG_GW_VD_ALPCAN_Vdp_SG_GW_VD_ALPCAN: accessed-variable=Rp_SG_GW_VD_ALPCAN.Vdp_SG_GW_VD_ALPCAN
              REC_Rp_SG_GW_VI_ALPCAN_Vdp_SG_GW_VI_ALPCAN: accessed-variable=Rp_SG_GW_VI_ALPCAN.Vdp_SG_GW_VI_ALPCAN
              REC_Rp_SG_OEL_ALVCAN_Vdp_SG_OEL_ALVCAN: accessed-variable=Rp_SG_OEL_ALVCAN.Vdp_SG_OEL_ALVCAN
              REC_Rp_SG_SAS_ALVCAN_Vdp_SG_SAS_ALVCAN: accessed-variable=Rp_SG_SAS_ALVCAN.Vdp_SG_SAS_ALVCAN
              REC_Rp_SG_TD_ALVCAN_Vdp_SG_TD_ALVCAN: accessed-variable=Rp_SG_TD_ALVCAN.Vdp_SG_TD_ALVCAN
              REC_Rp_SG_VDC2_ALVCAN_Vdp_SG_VDC2_ALVCAN: accessed-variable=Rp_SG_VDC2_ALVCAN.Vdp_SG_VDC2_ALVCAN
              REC_Rp_SG_VD_ALVCAN_Vdp_SG_VD_ALVCAN: accessed-variable=Rp_SG_VD_ALVCAN.Vdp_SG_VD_ALVCAN
              REC_Rp_SG_VI_ALVCAN_Vdp_SG_VI_ALVCAN: accessed-variable=Rp_SG_VI_ALVCAN.Vdp_SG_VI_ALVCAN
        Pp_PCAN_Srv_DisableAppTx_Operation
        Pp_PCAN_Srv_EnableAppTx_Operation
        PostRadarProcessing_CAN_Tx_RE_Communication_Tx
        Pp_VCAN_Srv_DisableAppTx_Operation
        Pp_VCAN_Srv_EnableAppTx_Operation
        RE_Communication_10ms
  swc implementation SWC_PLT_Appl_Communication_Implementation: behavior=SWC_PLT_Appl_Communication_InternalBehavior
